VERSION ""

NS_ :

BS_:

BU_: PowertrainControlModule AtmosphericSensor SafetyRestraintSystem2 Aftertreatment_2_GasOutlet Aftertreatment_2_GasIntake DieselParticulateFilterControl Turbocharger SafetyRestraintSystem1 CabDisplay2 Aftertreatment_1_GasOutlet Aftertreatment_1_GasIntake OnBoardDataLogger OffBoardDiagnosticTool2 OffBoardDiagnosticTool1 FileServer ParkingBrakeController SeatController2 FanDriveController SteeringColumnUnit CommunicationUnitRadio CommunicationUnitSatellite CommunicationUnitCellular PropulsionBatteryCharger ChassisController2 ChassisController1 EngineValveControl AuxiliaryHeater2 AuxiliaryHeater1 ClutchUnit RampControl InformationSystem1 SuspensionSystemController2 OilSensor VehicleDynamicStability ExhaustEmissionController TransmissionDisplay2 TransmissionDisplay1 ClimateControl2 WaterPumpController RearAxleSteeringController LightingOperatorControl SeatController1 IgnitionController2 IgnitionController1 TirePressureController CabController2 CabController1 PneumaticSystemController SuspensionSystemController1 HydraulicPumpController EnduranceBrakingSystem RetarderExhaustEngine2 OnBoardDiagnosticUnit HeadwayController RetarderExhaustEngine1 CabDisplay1 ManagementComputer VirtualTerminal OffVehicleGateway PowerTakeOffFront HitchControl AuxiliaryValveControl BodyController TractorTrailerBridge1 StarterSystem ElectricalSystem VehicleSecurity VehicleNavigation AerodynamicControl ElectricalChargingSystem ClimateControl1 TripRecorder InstrumentCluster SuspensionDriveAxle2 SuspensionDriveAxle1 SuspensionSteerAxle SteeringController FuelSystem CruiseControl RetarderDriveline RetarderEngine BrakesDriveAxle2 BrakesDriveAxle1 BrakesSystemController BrakesSteerAxle AxleDrive2 AxleDrive1 AxleSteering PowerTakeOff ShiftConsoleSecondary ShiftConsolePrimary Transmission2 Transmission1 Engine2 Engine1

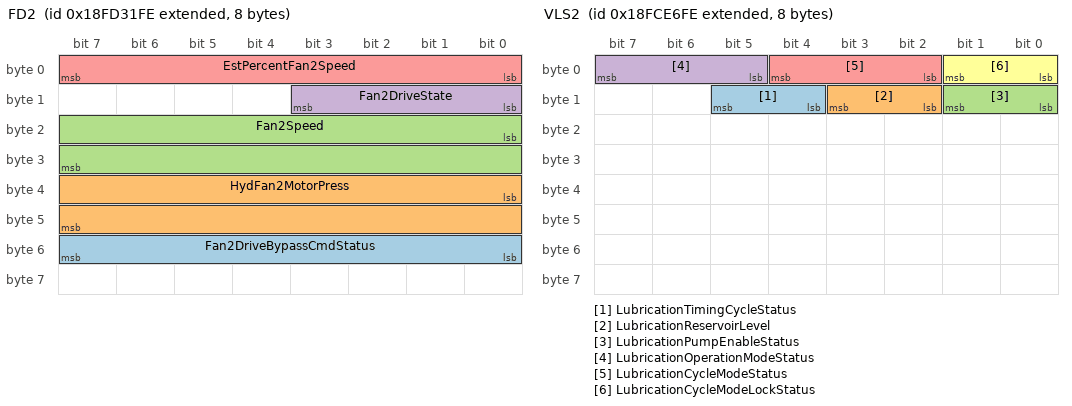
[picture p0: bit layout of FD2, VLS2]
BO_ 2566730238 FD2: 8 Vector__XXX
 SG_ Fan2DriveBypassCmdStatus : 48|8@1+ (0.4,0) [0|100] "%" Vector__XXX
 SG_ HydFan2MotorPress : 32|16@1+ (0.5,0) [0|32127.5] "kPa" Vector__XXX
 SG_ Fan2Speed : 16|16@1+ (0.125,0) [0|8031.875] "rpm" Vector__XXX
 SG_ Fan2DriveState : 8|4@1+ (1,0) [0|15] "" Vector__XXX
 SG_ EstPercentFan2Speed : 0|8@1+ (0.4,0) [0|100] "%" Vector__XXX

BO_ 2566711038 VLS2: 8 Vector__XXX
 SG_ LubricationTimingCycleStatus : 12|2@1+ (1,0) [0|3] "" Vector__XXX
 SG_ LubricationReservoirLevel : 10|2@1+ (1,0) [0|3] "" Vector__XXX
 SG_ LubricationPumpEnableStatus : 8|2@1+ (1,0) [0|3] "" Vector__XXX
 SG_ LubricationOperationModeStatus : 5|3@1+ (1,0) [0|7] "" Vector__XXX
 SG_ LubricationCycleModeStatus : 2|3@1+ (1,0) [0|7] "" Vector__XXX
 SG_ LubricationCycleModeLockStatus : 0|2@1+ (1,0) [0|3] "" Vector__XXX

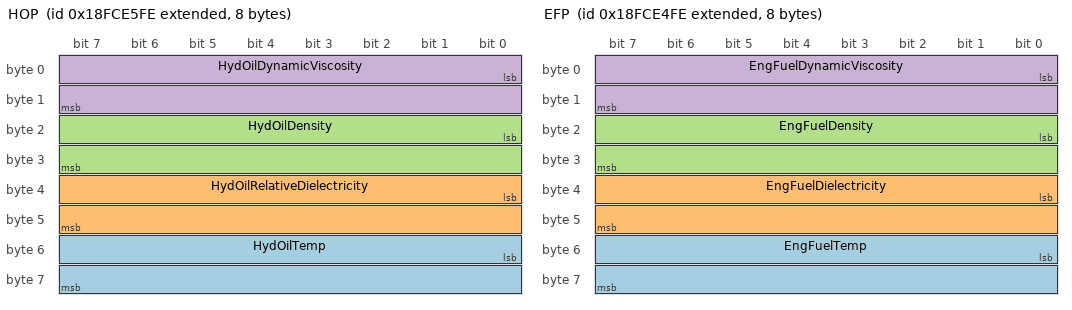
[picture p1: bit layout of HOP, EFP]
BO_ 2566710782 HOP: 8 Vector__XXX
 SG_ HydOilTemp : 48|16@1+ (0.03125,-273) [-273|1734.96875] "캜" Vector__XXX
 SG_ HydOilRelativeDielectricity : 32|16@1+ (0.0001220703125,0) [0|7.844] "" Vector__XXX
 SG_ HydOilDensity : 16|16@1+ (3.052E-005,0) [0|1.961] "g/cc" Vector__XXX
 SG_ HydOilDynamicViscosity : 0|16@1+ (0.015625,0) [0|1003.984375] "Cp" Vector__XXX

BO_ 2566710526 EFP: 8 Vector__XXX
 SG_ EngFuelTemp : 48|16@1+ (0.03125,-273) [-273|1734.96875] "캜" Vector__XXX
 SG_ EngFuelDielectricity : 32|16@1+ (0.0001220703125,0) [0|7.844] "" Vector__XXX
 SG_ EngFuelDensity : 16|16@1+ (3.052E-005,0) [0|1.961] "g/cc" Vector__XXX
 SG_ EngFuelDynamicViscosity : 0|16@1+ (0.015625,0) [0|1003.984375] "Cp" Vector__XXX

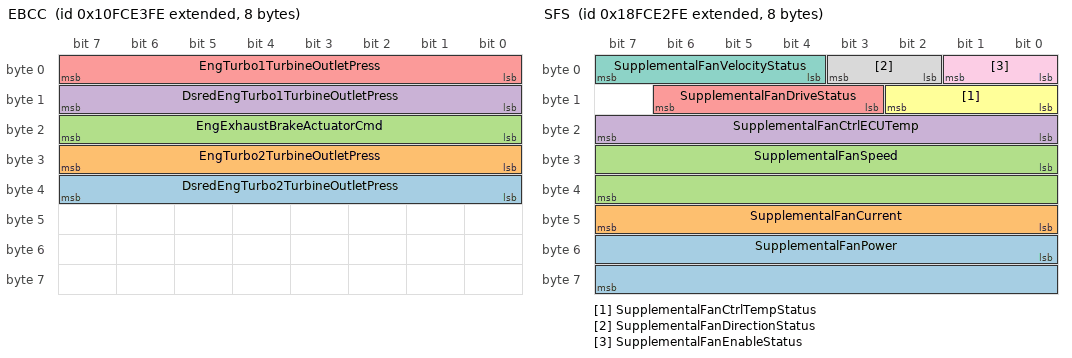
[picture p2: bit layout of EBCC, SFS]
BO_ 2432492542 EBCC: 8 Vector__XXX
 SG_ DsredEngTurbo2TurbineOutletPress : 32|8@1+ (2,0) [0|500] "kPa" Vector__XXX
 SG_ EngTurbo2TurbineOutletPress : 24|8@1+ (2,0) [0|500] "kPa" Vector__XXX
 SG_ EngExhaustBrakeActuatorCmd : 16|8@1+ (0.4,0) [0|100] "%" Vector__XXX
 SG_ DsredEngTurbo1TurbineOutletPress : 8|8@1+ (2,0) [0|500] "kPa" Vector__XXX
 SG_ EngTurbo1TurbineOutletPress : 0|8@1+ (2,0) [0|500] "kPa" Vector__XXX

BO_ 2566710014 SFS: 8 Vector__XXX
 SG_ SupplementalFanPower : 48|16@1+ (0.5,0) [0|32127.5] "W" Vector__XXX
 SG_ SupplementalFanCurrent : 40|8@1+ (1,-125) [-125|125] "A" Vector__XXX
 SG_ SupplementalFanSpeed : 24|16@1+ (0.5,0) [0|32127.5] "rpm" Vector__XXX
 SG_ SupplementalFanCtrlECUTemp : 16|8@1+ (1,-40) [-40|210] "캜" Vector__XXX
 SG_ SupplementalFanDriveStatus : 11|4@1+ (1,0) [0|15] "" Vector__XXX
 SG_ SupplementalFanCtrlTempStatus : 8|3@1+ (1,0) [0|7] "" Vector__XXX
 SG_ SupplementalFanVelocityStatus : 4|4@1+ (1,0) [0|15] "" Vector__XXX
 SG_ SupplementalFanDirectionStatus : 2|2@1+ (1,0) [0|3] "" Vector__XXX
 SG_ SupplementalFanEnableStatus : 0|2@1+ (1,0) [0|3] "" Vector__XXX

BO_ 2566709758 LFE2: 8 Vector__XXX
 SG_ EngDieselFuelDemandRate : 32|16@1+ (0.05,0) [0|3212.75] "l/h" Vector__XXX
 SG_ HighResolutionEngFuelRate : 0|32@1+ (0.001,0) [0|4211081.215] "l/h" Vector__XXX

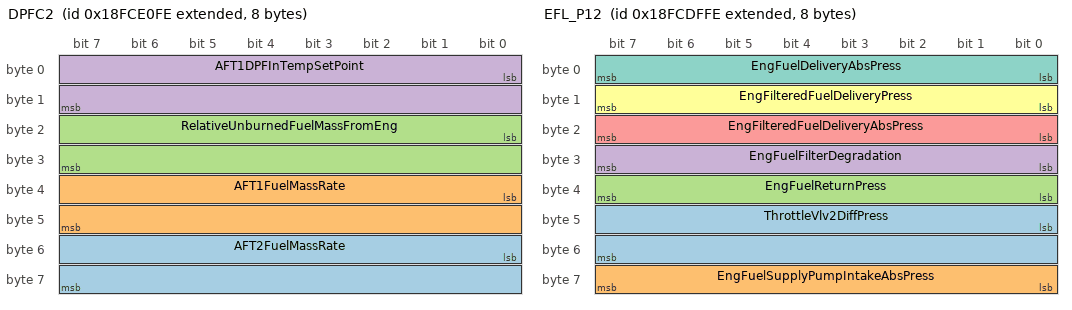
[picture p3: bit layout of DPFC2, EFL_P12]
BO_ 2566709502 DPFC2: 8 Vector__XXX
 SG_ AFT2FuelMassRate : 48|16@1+ (0.05,0) [0|3212.75] "g/min" Vector__XXX
 SG_ AFT1FuelMassRate : 32|16@1+ (0.05,0) [0|3212.75] "g/min" Vector__XXX
 SG_ RelativeUnburnedFuelMassFromEng : 16|16@1+ (0.0025,0) [0|160.6375] "%" Vector__XXX
 SG_ AFT1DPFInTempSetPoint : 0|16@1+ (0.03125,-273) [-273|1734.96875] "캜" Vector__XXX

BO_ 2566709246 EFL_P12: 8 Vector__XXX
 SG_ ThrottleVlv2DiffPress : 40|16@1+ (0.1,0) [0|6425.5] "kPa" Vector__XXX
 SG_ EngFuelSupplyPumpIntakeAbsPress : 56|8@1+ (5,0) [0|1250] "kPa" Vector__XXX
 SG_ EngFuelReturnPress : 32|8@1+ (1.64,-7) [-7|403] "kPa" Vector__XXX
 SG_ EngFuelFilterDegradation : 24|8@1+ (1,0) [0|250] "%" Vector__XXX
 SG_ EngFilteredFuelDeliveryAbsPress : 16|8@1+ (4,0) [0|1000] "kPa" Vector__XXX
 SG_ EngFilteredFuelDeliveryPress : 8|8@1+ (4,0) [0|1000] "kPa" Vector__XXX
 SG_ EngFuelDeliveryAbsPress : 0|8@1+ (4,0) [0|1000] "kPa" Vector__XXX

BO_ 2566708990 AT1AC3: 8 Vector__XXX
 SG_ SecondAirAbsPress : 0|16@1+ (0.1,0) [0|6425.5] "kPa" Vector__XXX

BO_ 2566708734 AT2AC3: 8 Vector__XXX
 SG_ SecondAirAbsPress : 0|16@1+ (0.1,0) [0|6425.5] "kPa" Vector__XXX

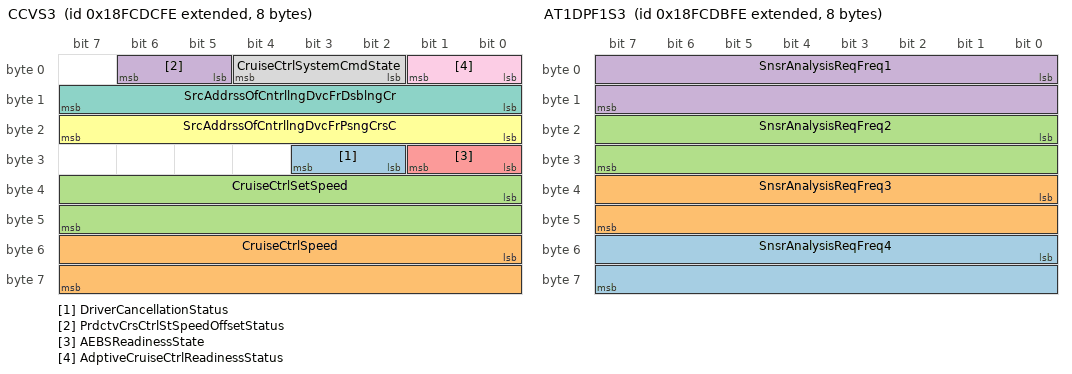
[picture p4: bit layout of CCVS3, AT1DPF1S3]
BO_ 2566708478 CCVS3: 8 Vector__XXX
 SG_ DriverCancellationStatus : 26|2@1+ (1,0) [0|3] "" Vector__XXX
 SG_ CruiseCtrlSpeed : 48|16@1+ (0.00390625,0) [0|250.996] "km/h" Vector__XXX
 SG_ CruiseCtrlSetSpeed : 32|16@1+ (0.00390625,0) [0|250.996] "km/h" Vector__XXX
 SG_ PrdctvCrsCtrlStSpeedOffsetStatus : 5|2@1+ (1,0) [0|3] "" Vector__XXX
 SG_ AEBSReadinessState : 24|2@1+ (1,0) [0|3] "" Vector__XXX
 SG_ SrcAddrssOfCntrllngDvcFrPsngCrsC : 16|8@1+ (1,0) [0|255] "" Vector__XXX
 SG_ SrcAddrssOfCntrllngDvcFrDsblngCr : 8|8@1+ (1,0) [0|255] "" Vector__XXX
 SG_ CruiseCtrlSystemCmdState : 2|3@1+ (1,0) [0|7] "" Vector__XXX
 SG_ AdptiveCruiseCtrlReadinessStatus : 0|2@1+ (1,0) [0|3] "" Vector__XXX

BO_ 2566708222 AT1DPF1S3: 8 Vector__XXX
 SG_ SnsrAnalysisReqFreq4 : 48|16@1+ (0.1,0) [0|6425.5] "MHz" Vector__XXX
 SG_ SnsrAnalysisReqFreq3 : 32|16@1+ (0.1,0) [0|6425.5] "MHz" Vector__XXX
 SG_ SnsrAnalysisReqFreq2 : 16|16@1+ (0.1,0) [0|6425.5] "MHz" Vector__XXX
 SG_ SnsrAnalysisReqFreq1 : 0|16@1+ (0.1,0) [0|6425.5] "MHz" Vector__XXX

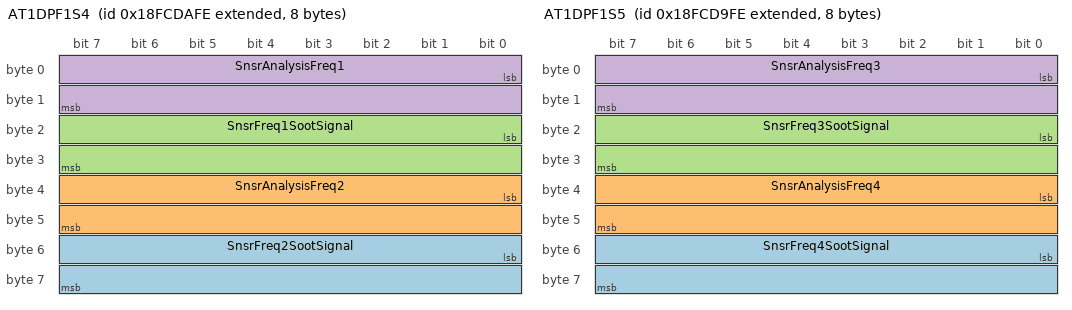
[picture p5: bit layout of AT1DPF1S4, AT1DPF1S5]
BO_ 2566707966 AT1DPF1S4: 8 Vector__XXX
 SG_ SnsrFreq2SootSignal : 48|16@1+ (0.0025,0) [0|160.6375] "%" Vector__XXX
 SG_ SnsrAnalysisFreq2 : 32|16@1+ (0.1,0) [0|6425.5] "MHz" Vector__XXX
 SG_ SnsrFreq1SootSignal : 16|16@1+ (0.0025,0) [0|160.6375] "%" Vector__XXX
 SG_ SnsrAnalysisFreq1 : 0|16@1+ (0.1,0) [0|6425.5] "MHz" Vector__XXX

BO_ 2566707710 AT1DPF1S5: 8 Vector__XXX
 SG_ SnsrFreq4SootSignal : 48|16@1+ (0.0025,0) [0|160.6375] "%" Vector__XXX
 SG_ SnsrAnalysisFreq4 : 32|16@1+ (0.1,0) [0|6425.5] "MHz" Vector__XXX
 SG_ SnsrFreq3SootSignal : 16|16@1+ (0.0025,0) [0|160.6375] "%" Vector__XXX
 SG_ SnsrAnalysisFreq3 : 0|16@1+ (0.1,0) [0|6425.5] "MHz" Vector__XXX

BO_ 2561343230 CFS: 8 Vector__XXX

BO_ 2566749694 FMS1: 8 Vector__XXX

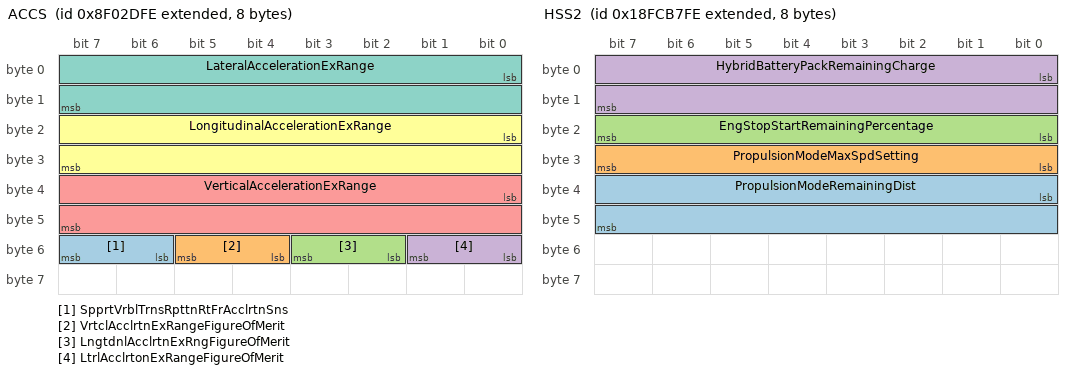
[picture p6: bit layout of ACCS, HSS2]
BO_ 2297441790 ACCS: 8 Vector__XXX
 SG_ SpprtVrblTrnsRpttnRtFrAcclrtnSns : 54|2@1+ (1,0) [0|3] "" Vector__XXX
 SG_ VrtclAcclrtnExRangeFigureOfMerit : 52|2@1+ (1,0) [0|3] "" Vector__XXX
 SG_ LngtdnlAcclrtnExRngFigureOfMerit : 50|2@1+ (1,0) [0|3] "" Vector__XXX
 SG_ LtrlAcclrtonExRangeFigureOfMerit : 48|2@1+ (1,0) [0|3] "" Vector__XXX
 SG_ VerticalAccelerationExRange : 32|16@1+ (0.01,-320) [-320|322.55] "m/s�" Vector__XXX
 SG_ LongitudinalAccelerationExRange : 16|16@1+ (0.01,-320) [-320|322.55] "m/s�" Vector__XXX
 SG_ LateralAccelerationExRange : 0|16@1+ (0.01,-320) [-320|322.55] "m/s�" Vector__XXX

BO_ 2566699006 HSS2: 8 Vector__XXX
 SG_ PropulsionModeRemainingDist : 32|16@1+ (0.03125,0) [0|2007.96875] "km" Vector__XXX
 SG_ PropulsionModeMaxSpdSetting : 24|8@1+ (1,0) [0|250] "km/h" Vector__XXX
 SG_ EngStopStartRemainingPercentage : 16|8@1+ (0.4,0) [0|100] "%" Vector__XXX
 SG_ HybridBatteryPackRemainingCharge : 0|16@1+ (0.0025,0) [0|160.6375] "%" Vector__XXX

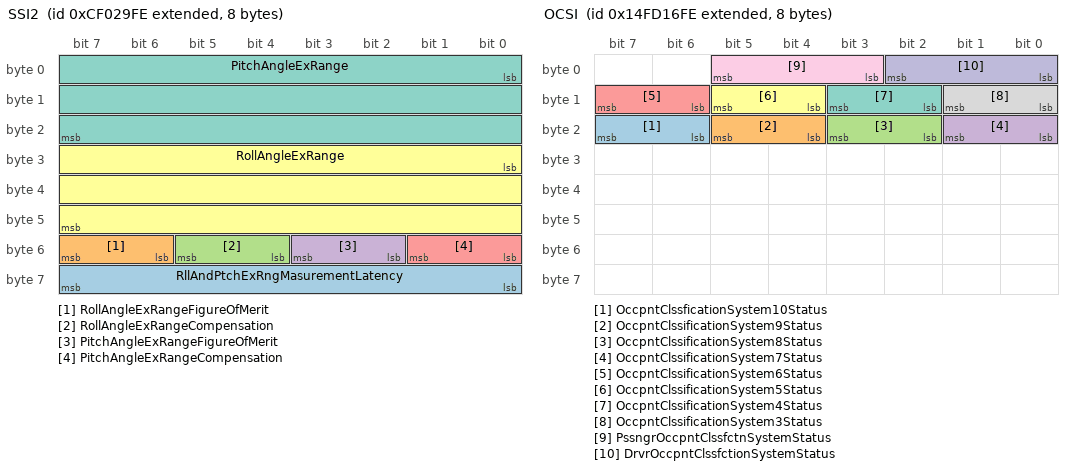
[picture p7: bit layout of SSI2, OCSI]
BO_ 2364549630 SSI2: 8 Vector__XXX
 SG_ RllAndPtchExRngMasurementLatency : 56|8@1+ (0.5,0) [0|125] "ms" Vector__XXX
 SG_ RollAngleExRangeFigureOfMerit : 54|2@1+ (1,0) [0|3] "" Vector__XXX
 SG_ RollAngleExRangeCompensation : 52|2@1+ (1,0) [0|3] "" Vector__XXX
 SG_ PitchAngleExRangeFigureOfMerit : 50|2@1+ (1,0) [0|3] "" Vector__XXX
 SG_ PitchAngleExRangeCompensation : 48|2@1+ (1,0) [0|3] "" Vector__XXX
 SG_ RollAngleExRange : 24|24@1+ (3.0517578125E-005,-250) [-250|252] "deg" Vector__XXX
 SG_ PitchAngleExRange : 0|24@1+ (3.0517578125E-005,-250) [-250|252] "deg" Vector__XXX

BO_ 2499614462 OCSI: 8 Vector__XXX
 SG_ OccpntClssficationSystem10Status : 22|2@1+ (1,0) [0|3] "" Vector__XXX
 SG_ OccpntClssificationSystem9Status : 20|2@1+ (1,0) [0|3] "" Vector__XXX
 SG_ OccpntClssificationSystem8Status : 18|2@1+ (1,0) [0|3] "" Vector__XXX
 SG_ OccpntClssificationSystem7Status : 16|2@1+ (1,0) [0|3] "" Vector__XXX
 SG_ OccpntClssificationSystem6Status : 14|2@1+ (1,0) [0|3] "" Vector__XXX
 SG_ OccpntClssificationSystem5Status : 12|2@1+ (1,0) [0|3] "" Vector__XXX
 SG_ OccpntClssificationSystem4Status : 10|2@1+ (1,0) [0|3] "" Vector__XXX
 SG_ OccpntClssificationSystem3Status : 8|2@1+ (1,0) [0|3] "" Vector__XXX
 SG_ PssngrOccpntClssfctnSystemStatus : 3|3@1+ (1,0) [0|7] "" Vector__XXX
 SG_ DrvrOccpntClssfctionSystemStatus : 0|3@1+ (1,0) [0|7] "" Vector__XXX

BO_ 2560098046 NCS: 8 Vector__XXX
 SG_ CabNoiseCtrlTuningStatus : 2|4@1+ (1,0) [0|15] "" Vector__XXX
 SG_ CabNoiseCtrlStatus : 0|2@1+ (1,0) [0|3] "" Vector__XXX

BO_ 2560163582 NC1: 8 Vector__XXX
 SG_ CabNoiseCtrlTuningCmd : 2|3@1+ (1,0) [0|7] "" Vector__XXX
 SG_ CabNoiseCtrlCmd : 0|2@1+ (1,0) [0|3] "" Vector__XXX

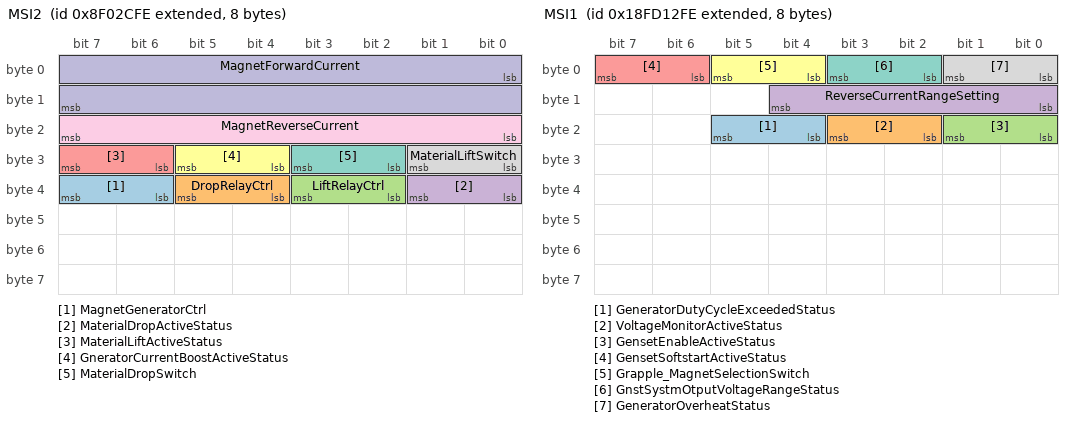
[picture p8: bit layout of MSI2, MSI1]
BO_ 2297441534 MSI2: 8 Vector__XXX
 SG_ MagnetGeneratorCtrl : 38|2@1+ (1,0) [0|3] "" Vector__XXX
 SG_ DropRelayCtrl : 36|2@1+ (1,0) [0|3] "" Vector__XXX
 SG_ LiftRelayCtrl : 34|2@1+ (1,0) [0|3] "" Vector__XXX
 SG_ MaterialDropActiveStatus : 32|2@1+ (1,0) [0|3] "" Vector__XXX
 SG_ MaterialLiftActiveStatus : 30|2@1+ (1,0) [0|3] "" Vector__XXX
 SG_ GneratorCurrentBoostActiveStatus : 28|2@1+ (1,0) [0|3] "" Vector__XXX
 SG_ MaterialDropSwitch : 26|2@1+ (1,0) [0|3] "" Vector__XXX
 SG_ MaterialLiftSwitch : 24|2@1+ (1,0) [0|3] "" Vector__XXX
 SG_ MagnetReverseCurrent : 16|8@1+ (1,0) [0|250] "A" Vector__XXX
 SG_ MagnetForwardCurrent : 0|16@1+ (1,0) [0|64255] "A" Vector__XXX

BO_ 2566722302 MSI1: 8 Vector__XXX
 SG_ GeneratorDutyCycleExceededStatus : 20|2@1+ (1,0) [0|3] "" Vector__XXX
 SG_ VoltageMonitorActiveStatus : 18|2@1+ (1,0) [0|3] "" Vector__XXX
 SG_ GensetEnableActiveStatus : 16|2@1+ (1,0) [0|3] "" Vector__XXX
 SG_ ReverseCurrentRangeSetting : 8|5@1+ (1,0) [0|31] "" Vector__XXX
 SG_ GensetSoftstartActiveStatus : 6|2@1+ (1,0) [0|3] "" Vector__XXX
 SG_ Grapple_MagnetSelectionSwitch : 4|2@1+ (1,0) [0|3] "" Vector__XXX
 SG_ GnstSystmOtputVoltageRangeStatus : 2|2@1+ (1,0) [0|3] "" Vector__XXX
 SG_ GeneratorOverheatStatus : 0|2@1+ (1,0) [0|3] "" Vector__XXX

BO_ 2566722558 MSCI: 8 Vector__XXX
 SG_ MagnetRatedPower : 8|16@1+ (0.5,0) [0|32127.5] "kW" Vector__XXX
 SG_ MagnetBoostTime : 0|8@1+ (0.25,0) [0|62.5] "s" Vector__XXX

BO_ 2560032510 LVDSOM: 8 Vector__XXX
 SG_ LwVltgDscnnctDsiredOperatingMode : 0|4@1+ (1,0) [0|15] "" Vector__XXX

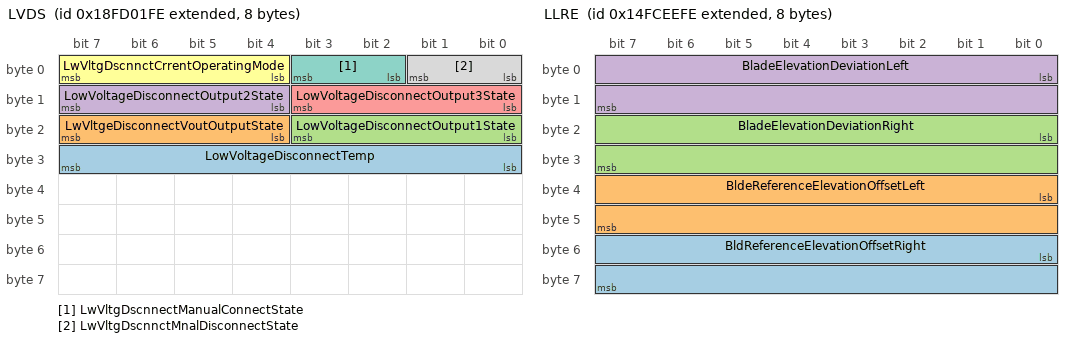
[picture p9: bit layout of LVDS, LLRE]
BO_ 2566717950 LVDS: 8 Vector__XXX
 SG_ LowVoltageDisconnectTemp : 24|8@1+ (1,-40) [-40|210] "캜" Vector__XXX
 SG_ LwVltgeDisconnectVoutOutputState : 20|4@1+ (1,0) [0|15] "" Vector__XXX
 SG_ LowVoltageDisconnectOutput1State : 16|4@1+ (1,0) [0|15] "" Vector__XXX
 SG_ LowVoltageDisconnectOutput2State : 12|4@1+ (1,0) [0|15] "" Vector__XXX
 SG_ LowVoltageDisconnectOutput3State : 8|4@1+ (1,0) [0|15] "" Vector__XXX
 SG_ LwVltgDscnnctCrrentOperatingMode : 4|4@1+ (1,0) [0|15] "" Vector__XXX
 SG_ LwVltgDscnnectManualConnectState : 2|2@1+ (1,0) [0|3] "" Vector__XXX
 SG_ LwVltgDscnnctMnalDisconnectState : 0|2@1+ (1,0) [0|3] "" Vector__XXX

BO_ 2499604222 LLRE: 8 Vector__XXX
 SG_ BldReferenceElevationOffsetRight : 48|16@1+ (1,-32000) [-32000|32255] "mm" Vector__XXX
 SG_ BldeReferenceElevationOffsetLeft : 32|16@1+ (1,-32000) [-32000|32255] "mm" Vector__XXX
 SG_ BladeElevationDeviationRight : 16|16@1+ (1,-32000) [-32000|32255] "mm" Vector__XXX
 SG_ BladeElevationDeviationLeft : 0|16@1+ (1,-32000) [-32000|32255] "mm" Vector__XXX

BO_ 2358902526 JLCM: 8 Vector__XXX
 SG_ Joystick3Lamp10Cmd : 58|2@1+ (1,0) [0|3] "" Vector__XXX
 SG_ Joystick3Lamp9Cmd : 56|2@1+ (1,0) [0|3] "" Vector__XXX
 SG_ Joystick3Lamp8Cmd : 54|2@1+ (1,0) [0|3] "" Vector__XXX
 SG_ Joystick3Lamp7Cmd : 52|2@1+ (1,0) [0|3] "" Vector__XXX
 SG_ Joystick3Lamp6Cmd : 50|2@1+ (1,0) [0|3] "" Vector__XXX
 SG_ Joystick3Lamp5Cmd : 48|2@1+ (1,0) [0|3] "" Vector__XXX
 SG_ Joystick3Lamp4Cmd : 46|2@1+ (1,0) [0|3] "" Vector__XXX
 SG_ Joystick3Lamp3Cmd : 44|2@1+ (1,0) [0|3] "" Vector__XXX
 SG_ Joystick3Lamp2Cmd : 42|2@1+ (1,0) [0|3] "" Vector__XXX
 SG_ Joystick3Lamp1Cmd : 40|2@1+ (1,0) [0|3] "" Vector__XXX
 SG_ Joystick2Lamp10Cmd : 38|2@1+ (1,0) [0|3] "" Vector__XXX
 SG_ Joystick2Lamp9Cmd : 36|2@1+ (1,0) [0|3] "" Vector__XXX
 SG_ Joystick2Lamp8Cmd : 34|2@1+ (1,0) [0|3] "" Vector__XXX
 SG_ Joystick2Lamp7Cmd : 32|2@1+ (1,0) [0|3] "" Vector__XXX
 SG_ Joystick2Lamp6Cmd : 30|2@1+ (1,0) [0|3] "" Vector__XXX
 SG_ Joystick2Lamp5Cmd : 28|2@1+ (1,0) [0|3] "" Vector__XXX
 SG_ Joystick2Lamp4Cmd : 26|2@1+ (1,0) [0|3] "" Vector__XXX
 SG_ Joystick2Lamp3Cmd : 24|2@1+ (1,0) [0|3] "" Vector__XXX
 SG_ Joystick2Lamp2Cmd : 22|2@1+ (1,0) [0|3] "" Vector__XXX
 SG_ Joystick2Lamp1Cmd : 20|2@1+ (1,0) [0|3] "" Vector__XXX
 SG_ Joystick1Lamp10Cmd : 18|2@1+ (1,0) [0|3] "" Vector__XXX
 SG_ Joystick1Lamp9Cmd : 16|2@1+ (1,0) [0|3] "" Vector__XXX
 SG_ Joystick1Lamp8Cmd : 14|2@1+ (1,0) [0|3] "" Vector__XXX
 SG_ Joystick1Lamp7Cmd : 12|2@1+ (1,0) [0|3] "" Vector__XXX
 SG_ Joystick1Lamp6Cmd : 10|2@1+ (1,0) [0|3] "" Vector__XXX
 SG_ Joystick1Lamp5Cmd : 8|2@1+ (1,0) [0|3] "" Vector__XXX
 SG_ Joystick1Lamp4Cmd : 6|2@1+ (1,0) [0|3] "" Vector__XXX
 SG_ Joystick1Lamp3Cmd : 4|2@1+ (1,0) [0|3] "" Vector__XXX
 SG_ Joystick1Lamp2Cmd : 2|2@1+ (1,0) [0|3] "" Vector__XXX
 SG_ Joystick1Lamp1Cmd : 0|2@1+ (1,0) [0|3] "" Vector__XXX

BO_ 2566711550 IVAC: 8 Vector__XXX
 SG_ IntkVlvActtnSystmOlPrss2SlndCtrl : 2|2@1+ (1,0) [0|3] "" Vector__XXX
 SG_ IntkVlvActtnSystmOlPrss1SlndCtrl : 0|2@1+ (1,0) [0|3] "" Vector__XXX

BO_ 2633832958 ILI: 8 Vector__XXX
 SG_ SpecialIgnitorLoop90Resistance : 1584|16@1+ (0.1,0) [0|6425.5] "ohm" Vector__XXX
 SG_ SpecialIgnitorLoop89Resistance : 1568|16@1+ (0.1,0) [0|6425.5] "ohm" Vector__XXX
 SG_ SpecialIgnitorLoop88Resistance : 1552|16@1+ (0.1,0) [0|6425.5] "ohm" Vector__XXX
 SG_ SpecialIgnitorLoop87Resistance : 1536|16@1+ (0.1,0) [0|6425.5] "ohm" Vector__XXX
 SG_ SpecialIgnitorLoop86Resistance : 1520|16@1+ (0.1,0) [0|6425.5] "ohm" Vector__XXX
 SG_ SpecialIgnitorLoop85Resistance : 1504|16@1+ (0.1,0) [0|6425.5] "ohm" Vector__XXX
 SG_ SpecialIgnitorLoop84Resistance : 1488|16@1+ (0.1,0) [0|6425.5] "ohm" Vector__XXX
 SG_ SpecialIgnitorLoop83Resistance : 1472|16@1+ (0.1,0) [0|6425.5] "ohm" Vector__XXX
 SG_ SpecialIgnitorLoop82Resistance : 1456|16@1+ (0.1,0) [0|6425.5] "ohm" Vector__XXX
 SG_ SpecialIgnitorLoop81Resistance : 1440|16@1+ (0.1,0) [0|6425.5] "ohm" Vector__XXX
 SG_ SpecialIgnitorLoop80Resistance : 1424|16@1+ (0.1,0) [0|6425.5] "ohm" Vector__XXX
 SG_ SpecialIgnitorLoop79Resistance : 1408|16@1+ (0.1,0) [0|6425.5] "ohm" Vector__XXX
 SG_ SpecialIgnitorLoop78Resistance : 1392|16@1+ (0.1,0) [0|6425.5] "ohm" Vector__XXX
 SG_ SpecialIgnitorLoop77Resistance : 1376|16@1+ (0.1,0) [0|6425.5] "ohm" Vector__XXX
 SG_ SpecialIgnitorLoop76Resistance : 1360|16@1+ (0.1,0) [0|6425.5] "ohm" Vector__XXX
 SG_ SpecialIgnitorLoop75Resistance : 1344|16@1+ (0.1,0) [0|6425.5] "ohm" Vector__XXX
 SG_ SpecialIgnitorLoop74Resistance : 1328|16@1+ (0.1,0) [0|6425.5] "ohm" Vector__XXX
 SG_ SpecialIgnitorLoop73Resistance : 1312|16@1+ (0.1,0) [0|6425.5] "ohm" Vector__XXX
 SG_ SpecialIgnitorLoop72Resistance : 1296|16@1+ (0.1,0) [0|6425.5] "ohm" Vector__XXX
 SG_ SpecialIgnitorLoop71Resistance : 1280|16@1+ (0.1,0) [0|6425.5] "ohm" Vector__XXX
 SG_ SpecialIgnitorLoop70Resistance : 1264|16@1+ (0.1,0) [0|6425.5] "ohm" Vector__XXX
 SG_ SpecialIgnitorLoop69Resistance : 1248|16@1+ (0.1,0) [0|6425.5] "ohm" Vector__XXX
 SG_ SpecialIgnitorLoop68Resistance : 1232|16@1+ (0.1,0) [0|6425.5] "ohm" Vector__XXX
 SG_ SpecialIgnitorLoop67Resistance : 1216|16@1+ (0.1,0) [0|6425.5] "ohm" Vector__XXX
 SG_ SpecialIgnitorLoop66Resistance : 1200|16@1+ (0.1,0) [0|6425.5] "ohm" Vector__XXX
 SG_ SpecialIgnitorLoop65Resistance : 1184|16@1+ (0.1,0) [0|6425.5] "ohm" Vector__XXX
 SG_ SpecialIgnitorLoop64Resistance : 1168|16@1+ (0.1,0) [0|6425.5] "ohm" Vector__XXX
 SG_ SpecialIgnitorLoop63Resistance : 1152|16@1+ (0.1,0) [0|6425.5] "ohm" Vector__XXX
 SG_ SpecialIgnitorLoop62Resistance : 1136|16@1+ (0.1,0) [0|6425.5] "ohm" Vector__XXX
 SG_ SpecialIgnitorLoop61Resistance : 1120|16@1+ (0.1,0) [0|6425.5] "ohm" Vector__XXX
 SG_ SpecialIgnitorLoop60Resistance : 1104|16@1+ (0.1,0) [0|6425.5] "ohm" Vector__XXX
 SG_ SpecialIgnitorLoop59Resistance : 1088|16@1+ (0.1,0) [0|6425.5] "ohm" Vector__XXX
 SG_ SpecialIgnitorLoop58Resistance : 1072|16@1+ (0.1,0) [0|6425.5] "ohm" Vector__XXX
 SG_ SpecialIgnitorLoop57Resistance : 1056|16@1+ (0.1,0) [0|6425.5] "ohm" Vector__XXX
 SG_ SpecialIgnitorLoop56Resistance : 1040|16@1+ (0.1,0) [0|6425.5] "ohm" Vector__XXX
 SG_ SpecialIgnitorLoop55Resistance : 1024|16@1+ (0.1,0) [0|6425.5] "ohm" Vector__XXX
 SG_ SpecialIgnitorLoop54Resistance : 1008|16@1+ (0.1,0) [0|6425.5] "ohm" Vector__XXX
 SG_ SpecialIgnitorLoop53Resistance : 992|16@1+ (0.1,0) [0|6425.5] "ohm" Vector__XXX
 SG_ SpecialIgnitorLoop52Resistance : 976|16@1+ (0.1,0) [0|6425.5] "ohm" Vector__XXX
 SG_ SpecialIgnitorLoop51Resistance : 960|16@1+ (0.1,0) [0|6425.5] "ohm" Vector__XXX
 SG_ SpecialIgnitorLoop50Resistance : 944|16@1+ (0.1,0) [0|6425.5] "ohm" Vector__XXX
 SG_ SpecialIgnitorLoop49Resistance : 928|16@1+ (0.1,0) [0|6425.5] "ohm" Vector__XXX
 SG_ SpecialIgnitorLoop48Resistance : 912|16@1+ (0.1,0) [0|6425.5] "ohm" Vector__XXX
 SG_ SpecialIgnitorLoop47Resistance : 896|16@1+ (0.1,0) [0|6425.5] "ohm" Vector__XXX
 SG_ SpecialIgnitorLoop46Resistance : 880|16@1+ (0.1,0) [0|6425.5] "ohm" Vector__XXX
 SG_ SpecialIgnitorLoop45Resistance : 864|16@1+ (0.1,0) [0|6425.5] "ohm" Vector__XXX
 SG_ SpecialIgnitorLoop44Resistance : 848|16@1+ (0.1,0) [0|6425.5] "ohm" Vector__XXX
 SG_ SpecialIgnitorLoop43Resistance : 832|16@1+ (0.1,0) [0|6425.5] "ohm" Vector__XXX
 SG_ SpecialIgnitorLoop42Resistance : 816|16@1+ (0.1,0) [0|6425.5] "ohm" Vector__XXX
 SG_ SpecialIgnitorLoop41Resistance : 800|16@1+ (0.1,0) [0|6425.5] "ohm" Vector__XXX
 SG_ SpecialIgnitorLoop40Resistance : 784|16@1+ (0.1,0) [0|6425.5] "ohm" Vector__XXX
 SG_ SpecialIgnitorLoop39Resistance : 768|16@1+ (0.1,0) [0|6425.5] "ohm" Vector__XXX
 SG_ SpecialIgnitorLoop38Resistance : 752|16@1+ (0.1,0) [0|6425.5] "ohm" Vector__XXX
 SG_ SpecialIgnitorLoop37Resistance : 736|16@1+ (0.1,0) [0|6425.5] "ohm" Vector__XXX
 SG_ SpecialIgnitorLoop36Resistance : 720|16@1+ (0.1,0) [0|6425.5] "ohm" Vector__XXX
 SG_ SpecialIgnitorLoop35Resistance : 704|16@1+ (0.1,0) [0|6425.5] "ohm" Vector__XXX
 SG_ SpecialIgnitorLoop34Resistance : 688|16@1+ (0.1,0) [0|6425.5] "ohm" Vector__XXX
 SG_ SpecialIgnitorLoop33Resistance : 672|16@1+ (0.1,0) [0|6425.5] "ohm" Vector__XXX
 SG_ SpecialIgnitorLoop32Resistance : 656|16@1+ (0.1,0) [0|6425.5] "ohm" Vector__XXX
 SG_ SpecialIgnitorLoop31Resistance : 640|16@1+ (0.1,0) [0|6425.5] "ohm" Vector__XXX
 SG_ SpecialIgnitorLoop30Resistance : 624|16@1+ (0.1,0) [0|6425.5] "ohm" Vector__XXX
 SG_ SpecialIgnitorLoop29Resistance : 608|16@1+ (0.1,0) [0|6425.5] "ohm" Vector__XXX
 SG_ SpecialIgnitorLoop28Resistance : 592|16@1+ (0.1,0) [0|6425.5] "ohm" Vector__XXX
 SG_ SpecialIgnitorLoop27Resistance : 576|16@1+ (0.1,0) [0|6425.5] "ohm" Vector__XXX
 SG_ SpecialIgnitorLoop26Resistance : 560|16@1+ (0.1,0) [0|6425.5] "ohm" Vector__XXX
 SG_ SpecialIgnitorLoop25Resistance : 544|16@1+ (0.1,0) [0|6425.5] "ohm" Vector__XXX
 SG_ SpecialIgnitorLoop24Resistance : 528|16@1+ (0.1,0) [0|6425.5] "ohm" Vector__XXX
 SG_ SpecialIgnitorLoop23Resistance : 512|16@1+ (0.1,0) [0|6425.5] "ohm" Vector__XXX
 SG_ SpecialIgnitorLoop22Resistance : 496|16@1+ (0.1,0) [0|6425.5] "ohm" Vector__XXX
 SG_ SpecialIgnitorLoop21Resistance : 480|16@1+ (0.1,0) [0|6425.5] "ohm" Vector__XXX
 SG_ SpecialIgnitorLoop20Resistance : 464|16@1+ (0.1,0) [0|6425.5] "ohm" Vector__XXX
 SG_ SpecialIgnitorLoop19Resistance : 448|16@1+ (0.1,0) [0|6425.5] "ohm" Vector__XXX
 SG_ SpecialIgnitorLoop18Resistance : 432|16@1+ (0.1,0) [0|6425.5] "ohm" Vector__XXX
 SG_ SpecialIgnitorLoop17Resistance : 416|16@1+ (0.1,0) [0|6425.5] "ohm" Vector__XXX
 SG_ SpecialIgnitorLoop16Resistance : 400|16@1+ (0.1,0) [0|6425.5] "ohm" Vector__XXX
 SG_ SpecialIgnitorLoop15Resistance : 384|16@1+ (0.1,0) [0|6425.5] "ohm" Vector__XXX
 SG_ SpecialIgnitorLoop14Resistance : 368|16@1+ (0.1,0) [0|6425.5] "ohm" Vector__XXX
 SG_ SpecialIgnitorLoop13Resistance : 352|16@1+ (0.1,0) [0|6425.5] "ohm" Vector__XXX
 SG_ SpecialIgnitorLoop12Resistance : 336|16@1+ (0.1,0) [0|6425.5] "ohm" Vector__XXX
 SG_ SpecialIgnitorLoop11Resistance : 320|16@1+ (0.1,0) [0|6425.5] "ohm" Vector__XXX
 SG_ SpecialIgnitorLoop10Resistance : 304|16@1+ (0.1,0) [0|6425.5] "ohm" Vector__XXX
 SG_ SpecialIgnitorLoop9Resistance : 288|16@1+ (0.1,0) [0|6425.5] "ohm" Vector__XXX
 SG_ SpecialIgnitorLoop8Resistance : 272|16@1+ (0.1,0) [0|6425.5] "ohm" Vector__XXX
 SG_ SpecialIgnitorLoop7Resistance : 256|16@1+ (0.1,0) [0|6425.5] "ohm" Vector__XXX
 SG_ SpecialIgnitorLoop6Resistance : 240|16@1+ (0.1,0) [0|6425.5] "ohm" Vector__XXX
 SG_ SpecialIgnitorLoop5Resistance : 224|16@1+ (0.1,0) [0|6425.5] "ohm" Vector__XXX
 SG_ SpecialIgnitorLoop4Resistance : 208|16@1+ (0.1,0) [0|6425.5] "ohm" Vector__XXX
 SG_ SpecialIgnitorLoop3Resistance : 192|16@1+ (0.1,0) [0|6425.5] "ohm" Vector__XXX
 SG_ SpecialIgnitorLoop2Resistance : 176|16@1+ (0.1,0) [0|6425.5] "ohm" Vector__XXX
 SG_ SpecialIgnitorLoop1Resistance : 160|16@1+ (0.1,0) [0|6425.5] "ohm" Vector__XXX
 SG_ SdBagIgnitorLoop2RightResistance : 144|16@1+ (0.1,0) [0|6425.5] "ohm" Vector__XXX
 SG_ SdBagIgnitorLoop1RightResistance : 128|16@1+ (0.1,0) [0|6425.5] "ohm" Vector__XXX
 SG_ SdeBagIgnitorLoop2LeftResistance : 112|16@1+ (0.1,0) [0|6425.5] "ohm" Vector__XXX
 SG_ SdeBagIgnitorLoop1LeftResistance : 96|16@1+ (0.1,0) [0|6425.5] "ohm" Vector__XXX
 SG_ PssngrBltTnsnrIgntrLopResistance : 80|16@1+ (0.1,0) [0|6425.5] "ohm" Vector__XXX
 SG_ DrvrBltTnsnrIgntorLoopResistance : 64|16@1+ (0.1,0) [0|6425.5] "ohm" Vector__XXX
 SG_ PssngrArbgIgntrLp2ndStgRsistance : 48|16@1+ (0.1,0) [0|6425.5] "ohm" Vector__XXX
 SG_ DrvrArbgIgntrLp2ndStgeResistance : 32|16@1+ (0.1,0) [0|6425.5] "ohm" Vector__XXX
 SG_ PssngrArbgIgntrLp1stStgRsistance : 16|16@1+ (0.1,0) [0|6425.5] "ohm" Vector__XXX
 SG_ DrvrArbgIgntrLp1stStgeResistance : 0|16@1+ (0.1,0) [0|6425.5] "ohm" Vector__XXX

BO_ 2566719998 HRLFC: 8 Vector__XXX
 SG_ HighResolutionEngTotalFuelUsed : 32|32@1+ (0.001,0) [0|4211081.215] "l" Vector__XXX
 SG_ HighResolutionEngTripFuel : 0|32@1+ (0.001,0) [0|4211081.215] "l" Vector__XXX

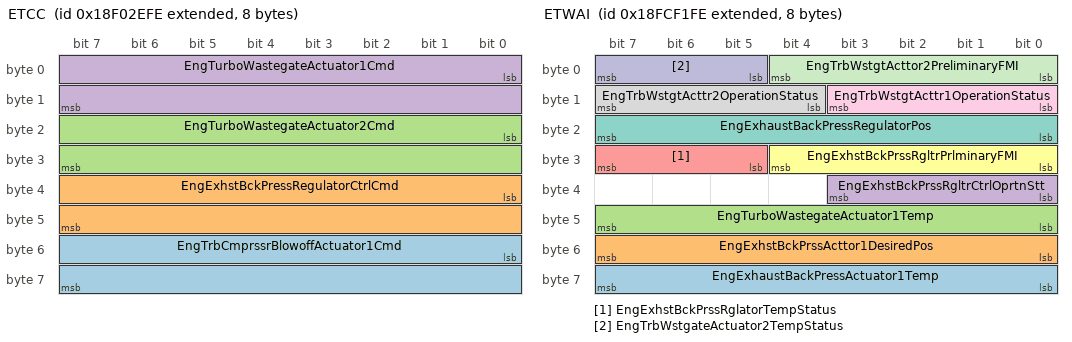
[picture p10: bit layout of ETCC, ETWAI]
BO_ 2565877502 ETCC: 8 Vector__XXX
 SG_ EngTrbCmprssrBlowoffActuator1Cmd : 48|16@1+ (0.0025,0) [0|100] "%" Vector__XXX
 SG_ EngExhstBckPressRegulatorCtrlCmd : 32|16@1+ (0.0025,0) [0|100] "%" Vector__XXX
 SG_ EngTurboWastegateActuator2Cmd : 16|16@1+ (0.0025,0) [0|160.6375] "%" Vector__XXX
 SG_ EngTurboWastegateActuator1Cmd : 0|16@1+ (0.0025,0) [0|160.6375] "%" Vector__XXX

BO_ 2566713854 ETWAI: 8 Vector__XXX
 SG_ EngExhaustBackPressActuator1Temp : 56|8@1+ (1,-40) [-40|210] "캜" Vector__XXX
 SG_ EngExhstBckPrssActtor1DesiredPos : 48|8@1+ (0.4,0) [0|100] "%" Vector__XXX
 SG_ EngTurboWastegateActuator1Temp : 40|8@1+ (1,-40) [-40|210] "캜" Vector__XXX
 SG_ EngExhstBckPrssRgltrCtrlOprtnStt : 32|4@1+ (1,0) [0|15] "" Vector__XXX
 SG_ EngExhstBckPrssRglatorTempStatus : 29|3@1+ (1,0) [0|7] "" Vector__XXX
 SG_ EngExhstBckPrssRgltrPrlminaryFMI : 24|5@1+ (1,0) [0|31] "" Vector__XXX
 SG_ EngExhaustBackPressRegulatorPos : 16|8@1+ (0.4,0) [0|100] "%" Vector__XXX
 SG_ EngTrbWstgtActtr2OperationStatus : 12|4@1+ (1,0) [0|15] "" Vector__XXX
 SG_ EngTrbWstgtActtr1OperationStatus : 8|4@1+ (1,0) [0|15] "" Vector__XXX
 SG_ EngTrbWstgateActuator2TempStatus : 5|3@1+ (1,0) [0|7] "" Vector__XXX
 SG_ EngTrbWstgtActtor2PreliminaryFMI : 0|5@1+ (1,0) [0|31] "" Vector__XXX

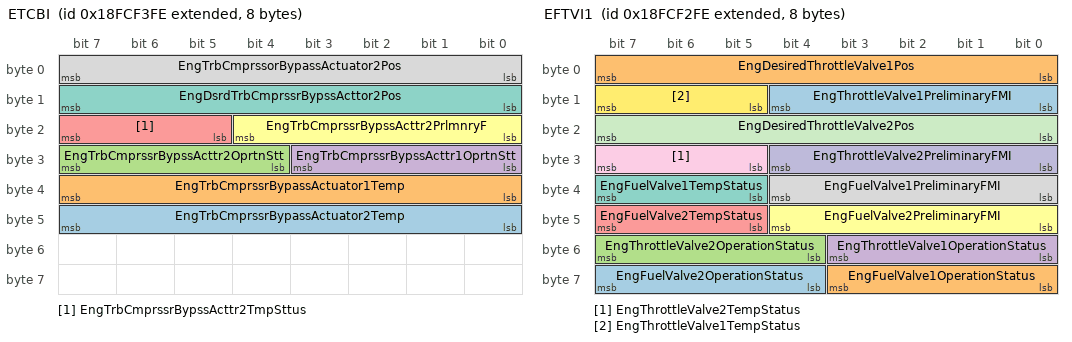
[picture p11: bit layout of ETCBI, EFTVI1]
BO_ 2566714366 ETCBI: 8 Vector__XXX
 SG_ EngTrbCmprssrBypassActuator2Temp : 40|8@1+ (1,-40) [-40|210] "캜" Vector__XXX
 SG_ EngTrbCmprssrBypassActuator1Temp : 32|8@1+ (1,-40) [-40|210] "캜" Vector__XXX
 SG_ EngTrbCmprssrBypssActtr2OprtnStt : 28|4@1+ (1,0) [0|15] "" Vector__XXX
 SG_ EngTrbCmprssrBypssActtr1OprtnStt : 24|4@1+ (1,0) [0|15] "" Vector__XXX
 SG_ EngTrbCmprssrBypssActtr2TmpSttus : 21|3@1+ (1,0) [0|7] "" Vector__XXX
 SG_ EngTrbCmprssrBypssActtr2PrlmnryF : 16|5@1+ (1,0) [0|31] "" Vector__XXX
 SG_ EngDsrdTrbCmprssrBypssActtor2Pos : 8|8@1+ (0.4,0) [0|100] "%" Vector__XXX
 SG_ EngTrbCmprssorBypassActuator2Pos : 0|8@1+ (0.4,0) [0|100] "%" Vector__XXX

BO_ 2566714110 EFTVI1: 8 Vector__XXX
 SG_ EngFuelValve2OperationStatus : 60|4@1+ (1,0) [0|15] "" Vector__XXX
 SG_ EngFuelValve1OperationStatus : 56|4@1+ (1,0) [0|15] "" Vector__XXX
 SG_ EngThrottleValve2OperationStatus : 52|4@1+ (1,0) [0|15] "" Vector__XXX
 SG_ EngThrottleValve1OperationStatus : 48|4@1+ (1,0) [0|15] "" Vector__XXX
 SG_ EngFuelValve2TempStatus : 45|3@1+ (1,0) [0|7] "" Vector__XXX
 SG_ EngFuelValve2PreliminaryFMI : 40|5@1+ (1,0) [0|31] "" Vector__XXX
 SG_ EngFuelValve1TempStatus : 37|3@1+ (1,0) [0|7] "" Vector__XXX
 SG_ EngFuelValve1PreliminaryFMI : 32|5@1+ (1,0) [0|31] "" Vector__XXX
 SG_ EngThrottleValve2TempStatus : 29|3@1+ (1,0) [0|7] "" Vector__XXX
 SG_ EngThrottleValve2PreliminaryFMI : 24|5@1+ (1,0) [0|31] "" Vector__XXX
 SG_ EngDesiredThrottleValve2Pos : 16|8@1+ (0.4,0) [0|100] "%" Vector__XXX
 SG_ EngThrottleValve1TempStatus : 13|3@1+ (1,0) [0|7] "" Vector__XXX
 SG_ EngThrottleValve1PreliminaryFMI : 8|5@1+ (1,0) [0|31] "" Vector__XXX
 SG_ EngDesiredThrottleValve1Pos : 0|8@1+ (0.4,0) [0|100] "%" Vector__XXX

BO_ 2566717438 ET5: 8 Vector__XXX
 SG_ EngExhstGsRcrcltn2MxerIntakeTemp : 16|16@1+ (0.03125,-273) [-273|1734.96875] "캜" Vector__XXX
 SG_ EngExhaustGasRecirculation2Temp : 0|16@1+ (0.03125,-273) [-273|1734.96875] "캜" Vector__XXX

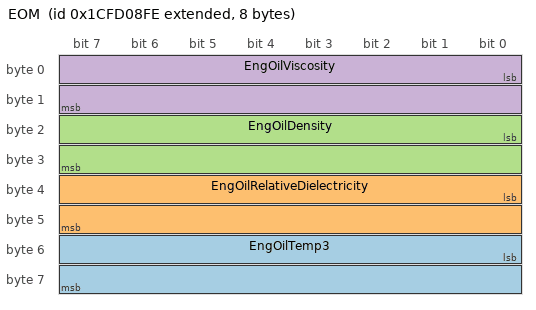
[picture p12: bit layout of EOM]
BO_ 2633828606 EOM: 8 Vector__XXX
 SG_ EngOilTemp3 : 48|16@1+ (0.03125,-273) [-273|1734.96875] "캜" Vector__XXX
 SG_ EngOilRelativeDielectricity : 32|16@1+ (0.0001220703125,0) [0|7.844] "" Vector__XXX
 SG_ EngOilDensity : 16|16@1+ (3.052E-005,0) [0|1.961] "g/cc" Vector__XXX
 SG_ EngOilViscosity : 0|16@1+ (0.015625,0) [0|1003.984375] "Cp" Vector__XXX

BO_ 2499607550 EMAP: 8 Vector__XXX
 SG_ EngExhstMnfldBnk2FlwBlncVlvActtr : 16|16@1+ (0.0025,0) [0|160.6375] "%" Vector__XXX
 SG_ EngExhstMnfldBnk1FlwBlncVlvActtr : 0|16@1+ (0.0025,0) [0|160.6375] "%" Vector__XXX

BO_ 2633825534 EMAC: 8 Vector__XXX
 SG_ EngExhstMnfldBnk2FlwBlncVlvActtr : 16|16@1+ (0.0025,0) [0|160.6375] "%" Vector__XXX
 SG_ EngExhstMnfldBnk1FlwBlncVlvActtr : 0|16@1+ (0.0025,0) [0|160.6375] "%" Vector__XXX

BO_ 2365400574 EJM9: 8 Vector__XXX
 SG_ Joystick9Button13PressedStatus : 62|2@1+ (1,0) [0|3] "" Vector__XXX
 SG_ Joystick9Button14PressedStatus : 60|2@1+ (1,0) [0|3] "" Vector__XXX
 SG_ Joystick9Button15PressedStatus : 58|2@1+ (1,0) [0|3] "" Vector__XXX
 SG_ Joystick9Button16PressedStatus : 56|2@1+ (1,0) [0|3] "" Vector__XXX
 SG_ Jystick9GripXAxisDetentPosStatus : 54|2@1+ (1,0) [0|3] "" Vector__XXX
 SG_ Jystick9GripYAxisDetentPosStatus : 52|2@1+ (1,0) [0|3] "" Vector__XXX
 SG_ Jystick9ThetaAxisDetentPosStatus : 50|2@1+ (1,0) [0|3] "" Vector__XXX
 SG_ Joystick9ThetaAxisPos : 38|10@1+ (0.1,0) [0|102] "%" Vector__XXX
 SG_ Jystck9ThtAxsClckwsPstvPosStatus : 36|2@1+ (1,0) [0|3] "" Vector__XXX
 SG_ Jystck9ThtAxsCntrClckwsNgtvPsStt : 34|2@1+ (1,0) [0|3] "" Vector__XXX
 SG_ Jystck9ThetaAxisNeutralPosStatus : 32|2@1+ (1,0) [0|3] "" Vector__XXX
 SG_ Joystick9GripYAxisPos : 22|10@1+ (0.1,0) [0|102] "%" Vector__XXX
 SG_ Jystck9GrpYAxsLvrFrwrdPstvPsStts : 20|2@1+ (1,0) [0|3] "" Vector__XXX
 SG_ Jystck9GrpYAxsLvrBckNgtvPsStatus : 18|2@1+ (1,0) [0|3] "" Vector__XXX
 SG_ Jystck9GripYAxisNeutralPosStatus : 16|2@1+ (1,0) [0|3] "" Vector__XXX
 SG_ Joystick9GripXAxisPos : 6|10@1+ (0.1,0) [0|102] "%" Vector__XXX
 SG_ Jystck9GrpXAxsLvrRghtPstvPsSttus : 4|2@1+ (1,0) [0|3] "" Vector__XXX
 SG_ Jystck9GrpXAxsLvrLftNgtvPsStatus : 2|2@1+ (1,0) [0|3] "" Vector__XXX
 SG_ Jystck9GripXAxisNeutralPosStatus : 0|2@1+ (1,0) [0|3] "" Vector__XXX

BO_ 2365401086 EJM8: 8 Vector__XXX
 SG_ Joystick8Button13PressedStatus : 62|2@1+ (1,0) [0|3] "" Vector__XXX
 SG_ Joystick8Button14PressedStatus : 60|2@1+ (1,0) [0|3] "" Vector__XXX
 SG_ Joystick8Button15PressedStatus : 58|2@1+ (1,0) [0|3] "" Vector__XXX
 SG_ Joystick8Button16PressedStatus : 56|2@1+ (1,0) [0|3] "" Vector__XXX
 SG_ Jystick8GripXAxisDetentPosStatus : 54|2@1+ (1,0) [0|3] "" Vector__XXX
 SG_ Jystick8GripYAxisDetentPosStatus : 52|2@1+ (1,0) [0|3] "" Vector__XXX
 SG_ Jystick8ThetaAxisDetentPosStatus : 50|2@1+ (1,0) [0|3] "" Vector__XXX
 SG_ Joystick8ThetaAxisPos : 38|10@1+ (0.1,0) [0|102] "%" Vector__XXX
 SG_ Jystck8ThtAxsClckwsPstvPosStatus : 36|2@1+ (1,0) [0|3] "" Vector__XXX
 SG_ Jystck8ThtAxsCntrClckwsNgtvPsStt : 34|2@1+ (1,0) [0|3] "" Vector__XXX
 SG_ Jystck8ThetaAxisNeutralPosStatus : 32|2@1+ (1,0) [0|3] "" Vector__XXX
 SG_ Joystick8GripYAxisPos : 22|10@1+ (0.1,0) [0|102] "%" Vector__XXX
 SG_ Jystck8GrpYAxsLvrFrwrdPstvPsStts : 20|2@1+ (1,0) [0|3] "" Vector__XXX
 SG_ Jystck8GrpYAxsLvrBckNgtvPsStatus : 18|2@1+ (1,0) [0|3] "" Vector__XXX
 SG_ Jystck8GripYAxisNeutralPosStatus : 16|2@1+ (1,0) [0|3] "" Vector__XXX
 SG_ Joystick8GripXAxisPos : 6|10@1+ (0.1,0) [0|102] "%" Vector__XXX
 SG_ Jystck8GrpXAxsLvrRghtPstvPsSttus : 4|2@1+ (1,0) [0|3] "" Vector__XXX
 SG_ Jystck8GrpXAxsLvrLftNgtvPsStatus : 2|2@1+ (1,0) [0|3] "" Vector__XXX
 SG_ Jystck8GripXAxisNeutralPosStatus : 0|2@1+ (1,0) [0|3] "" Vector__XXX

BO_ 2365401598 EJM7: 8 Vector__XXX
 SG_ Joystick7Button13PressedStatus : 62|2@1+ (1,0) [0|3] "" Vector__XXX
 SG_ Joystick7Button14PressedStatus : 60|2@1+ (1,0) [0|3] "" Vector__XXX
 SG_ Joystick7Button15PressedStatus : 58|2@1+ (1,0) [0|3] "" Vector__XXX
 SG_ Joystick7Button16PressedStatus : 56|2@1+ (1,0) [0|3] "" Vector__XXX
 SG_ Jystick7GripXAxisDetentPosStatus : 54|2@1+ (1,0) [0|3] "" Vector__XXX
 SG_ Jystick7GripYAxisDetentPosStatus : 52|2@1+ (1,0) [0|3] "" Vector__XXX
 SG_ Jystick7ThetaAxisDetentPosStatus : 50|2@1+ (1,0) [0|3] "" Vector__XXX
 SG_ Joystick7ThetaAxisPos : 38|10@1+ (0.1,0) [0|102] "%" Vector__XXX
 SG_ Jystck7ThtAxsClckwsPstvPosStatus : 36|2@1+ (1,0) [0|3] "" Vector__XXX
 SG_ Jystck7ThtAxsCntrClckwsNgtvPsStt : 34|2@1+ (1,0) [0|3] "" Vector__XXX
 SG_ Jystck7ThetaAxisNeutralPosStatus : 32|2@1+ (1,0) [0|3] "" Vector__XXX
 SG_ Joystick7GripYAxisPos : 22|10@1+ (0.1,0) [0|102] "%" Vector__XXX
 SG_ Jystck7GrpYAxsLvrFrwrdPstvPsStts : 20|2@1+ (1,0) [0|3] "" Vector__XXX
 SG_ Jystck7GrpYAxsLvrBckNgtvPsStatus : 18|2@1+ (1,0) [0|3] "" Vector__XXX
 SG_ Jystck7GripYAxisNeutralPosStatus : 16|2@1+ (1,0) [0|3] "" Vector__XXX
 SG_ Joystick7GripXAxisPos : 6|10@1+ (0.1,0) [0|102] "%" Vector__XXX
 SG_ Jystck7GrpXAxsLvrRghtPstvPsSttus : 4|2@1+ (1,0) [0|3] "" Vector__XXX
 SG_ Jystck7GrpXAxsLvrLftNgtvPsStatus : 2|2@1+ (1,0) [0|3] "" Vector__XXX
 SG_ Jystck7GripXAxisNeutralPosStatus : 0|2@1+ (1,0) [0|3] "" Vector__XXX

CM_ BO_ 2566730238 "Fan Drive #2
This parameter group transfers status and measured information for a second engine coolant fan.  For systems with a single or the primary fan, see PGN 65213.";
CM_ SG_ 2566730238 Fan2DriveBypassCmdStatus "Status of the Fan Drive Bypass Command for the second fan as being commanded by the ECU.  The fan drive bypass diverts pump pressure away from the hydraulic motor to maintain the fan drive pressure.  0% is defined as no bypass (i.e. diverting no fan ...";
CM_ SG_ 2566730238 HydFan2MotorPress "The hydraulic pressure used to drive the second fan system, sensed before the hydraulic fan motor.";
CM_ SG_ 2566730238 Fan2Speed "The speed of the second fan associated with engine coolant system.";
CM_ SG_ 2566730238 Fan2DriveState "This parameter is used to indicate the current state or mode of operation by the second fan drive.
0000 Fan off
0001 Engine system-General
0010 Excessive engine air temperature
0011 Excessive engine oil temperature
0100 Excessive engine coolant ...";
CM_ SG_ 2566730238 EstPercentFan2Speed "Estimated fan speed as a ratio of the fan drive (current speed) to the fully engaged fan drive (maximum fan speed).  A two state fan (off/on) will use 0% and 100% respectively.  A three state fan (off/intermediate/on) will use 0%, 50% and 100% ...";
CM_ BO_ 2566711038 "Vehicle/Chassis Lubrication System 2
Reports vehicle/chassis lubrication systems status";
CM_ SG_ 2566711038 LubricationTimingCycleStatus "Reports the status of the lubrication activation clock.
00 - Paused
01 - Enabled
10 - Error
11 - Not available or not installed
Note:  In some vehicles or machines, lubrication is only required when the vehicle or machine is in certain state e ...";
CM_ SG_ 2566711038 LubricationReservoirLevel "Reports the status of the lubrication system reservior level.  The lubrication reservoir stores the grease for the lubrication system. The lubrication pump draws grease from this reservoir and pushes it into the vehicle/chassis joints
00 - ...";
CM_ SG_ 2566711038 LubricationPumpEnableStatus "Reports the operational status of the lubrication system pump.  In the disabled state, the lubrication pump will not run a lubrication cycle.  In the enabled state, the lubrication system will perform normal operations.
00 - Disabled
01 - Enabled
 ...";
CM_ SG_ 2566711038 LubricationOperationModeStatus "Reports the current operational mode status of the lubrication system.
Automatic is the normal operation mode of lubrication system. In this mode the operator has the privilege to change duty cycle mode, if the lubrication mode in not locked.
In ...";
CM_ SG_ 2566711038 LubricationCycleModeStatus "Reports the current lubrication cycle mode of the lubrication system
000 - Cycle mode # 1 (Lowest Lubrication Frequency)
001 - Cycle mode # 2
010 - Cycle mode # 3 (Highest Lubrication Frequency)
011 to 101 - Reserved
110 - Error
111 - Not ...";
CM_ SG_ 2566711038 LubricationCycleModeLockStatus "Reports status of the ability to change the lubrication cycle mode.  Locking the lubrication mode would prevent the changing of the lubrication cycle mode, perhaps by an operator

00 - Not Locked
01 - Locked
10 - Error
11 - Not available";
CM_ BO_ 2566710782 "Hydraulic Oil Properties
Hydraulic Oil Properties.  This hydraulic fluid is for the entire hydraulics system of a piece of equipment.";
CM_ SG_ 2566710782 HydOilTemp "Hydraulic Oil Temperature.  This hydraulic fluid is for the entire hydraulics system of a piece of equipment.";
CM_ SG_ 2566710782 HydOilRelativeDielectricity "Hydraulic oil relative dielectricity used to describe the hydraulic oil quality.  This hydraulic fluid is for the entire hydraulics system of a piece of equipment.";
CM_ SG_ 2566710782 HydOilDensity "Density of hydraulic oil.  This hydraulic fluid is for the entire hydraulics system of a piece of equipment.";
CM_ SG_ 2566710782 HydOilDynamicViscosity "Dynamic viscosity of hydraulic oil.  This hydraulic fluid is for the entire hydraulics system of a piece of equipment.";
CM_ BO_ 2566710526 "Engine Fuel Properties
Engine Fuel Properties";
CM_ SG_ 2566710526 EngFuelTemp "Engine Fuel Temperature of the first fuel type. See also SPNs 174 or 3468 for alternate resolution.";
CM_ SG_ 2566710526 EngFuelDielectricity "Engine fuel relative dielectricity.";
CM_ SG_ 2566710526 EngFuelDensity "Density of engine fuel";
CM_ SG_ 2566710526 EngFuelDynamicViscosity "Dynamic viscosity of engine fuel";
CM_ BO_ 2432492542 "Engine Exhaust Brake Control
Contains information about the engine exhaust brake system control.";
CM_ SG_ 2432492542 DsredEngTurbo2TurbineOutletPress "The desired gage pressure of the combustion by-products exiting the turbine side of the turbocharger 2 at the current engine operating conditions.";
CM_ SG_ 2432492542 EngTurbo2TurbineOutletPress "Gage pressure of the combustion by-products exiting the turbine side of the turbocharger 2.";
CM_ SG_ 2432492542 EngExhaustBrakeActuatorCmd "The control command applied to the engine exhaust brake actuator, where 0% represents no braking and 100% represents full braking.";
CM_ SG_ 2432492542 DsredEngTurbo1TurbineOutletPress "The desired gage pressure of the combustion by-products exiting the turbine side of the turbocharger 1 at the current engine operating conditions.";
CM_ SG_ 2432492542 EngTurbo1TurbineOutletPress "Gage pressure of the combustion by-products exiting the turbine side of the turbocharger 1.";
CM_ BO_ 2566710014 "Supplemental Fan Status
The status of Supplemental Fan. This is a supplemental fan used for additional cooling beyond that of the primary cooling fan system. For example, this fan could be used to provide additional cooling to an aftertreatment ...";
CM_ SG_ 2566710014 SupplementalFanPower "Estimated Power output of Supplemental Fan";
CM_ SG_ 2566710014 SupplementalFanCurrent "Measured electrical current of supplemental fan drive.";
CM_ SG_ 2566710014 SupplementalFanSpeed "Measured speed of supplemental fan.";
CM_ SG_ 2566710014 SupplementalFanCtrlECUTemp "Measured temperature of Supplemental Fan Controller ECU.";
CM_ SG_ 2566710014 SupplementalFanDriveStatus "The drive status of the Supplemental Fan. This status parameter indicates the overall health of the fan drive. It will indicate that the fan is working OK or if there is an internal fault such as open winding or internal short circuit.
0000 ...";
CM_ SG_ 2566710014 SupplementalFanCtrlTempStatus "Internal Controller Temperature Status of Supplemental Fan.

000   High most severe 
001   High Least severe 
010   In Range 
011   Low Least severe 
100   Low Most severe 
101   Not Defined 
110   Error 
111   Not available";
CM_ SG_ 2566710014 SupplementalFanVelocityStatus "Status of the rotational velocity of Supplemental Fan. Used to indicate if the fan is spinning at the desired speed. If fan is not able to obtain the commanded speed, velocity error is indicated. If fan is unable to spin, the fan is in Fan Stall ...";
CM_ SG_ 2566710014 SupplementalFanDirectionStatus "Rotational Direction of Supplemental Fan. Fan could be spinning forward or reverse.

00   Forward
01   Reverse
10   Error
11   Not available/Not installed";
CM_ SG_ 2566710014 SupplementalFanEnableStatus "Enable/Disable Status of Supplemental Fan.

00   Disabled
01   Enabled
10   Error
11   Not available/Not installed";
CM_ BO_ 2566709758 "Fuel Economy 2 (Liquid)";
CM_ SG_ 2566709758 EngDieselFuelDemandRate "Amount of diesel fuel that would be consumed by an engine per unit of time if it were not substituting gaseous fuel.  This parameter is the sum of SPN 183 and the amount of diesel fuel that is being displaced by gaseous fuel.  If the engine is not ...";
CM_ SG_ 2566709758 HighResolutionEngFuelRate "Amount of fuel consumed by engine per unit of time.  

NOTE - See SPN 183 for alternate resolution.";
CM_ BO_ 2566709502 "Diesel Particulate Filter Control 2
The purpose of this PGN is to group parameters about the diesel particulate filter regeneration control.";
CM_ SG_ 2566709502 AFT2FuelMassRate "Mass rate of total fuel being delivered to Atertreatment 2 for DPF regeneration.";
CM_ SG_ 2566709502 AFT1FuelMassRate "Mass rate of total fuel being delivered to aftertreatment 1 for DPF regeneration.";
CM_ SG_ 2566709502 RelativeUnburnedFuelMassFromEng "The unburned amount of diesel fuel coming out of the engine. This fuel increases the temperature while oxidated in the DOC. Therefore, this amount of fuel also needs to be taken into account of the HCD temperature controller.";
CM_ SG_ 2566709502 AFT1DPFInTempSetPoint "Set point temperature for the particulate filter (DPF) regeneration at the intake to the DPF for Exhaust bank 1.";
CM_ BO_ 2566709246 "Engine Fluid Level/Pressure 12
12th PGN which identifies parameters that are either measuring various pressures within the engine or identifying engine fluid levels";
CM_ SG_ 2566709246 ThrottleVlv2DiffPress "The differential pressure between the intake and outlet of the throttle valve 2 (SPN 3673). The differential pressure is measured from the intake with respect to the outlet of the throttle valve.";
CM_ SG_ 2566709246 EngFuelSupplyPumpIntakeAbsPress "Absolute pressure of fuel at the fuel supply pump intake. See Figures SPN16_A & SPN16_B. See SPN 1381 for alternate resolution.

Engine Fuel Supply Pump Intake Absolute Pressure (Extended Range)";
CM_ SG_ 2566709246 EngFuelReturnPress "Used to read fuel (or gas) pressure passing through the return line.";
CM_ SG_ 2566709246 EngFuelFilterDegradation "The estimated percentage relative to the useful life of the engine fuel filter.
This is not a calculation of the physical restriction of the filter.  0% is typical of a new filter.  100% is typical of an end of life filter, the filter should be ...";
CM_ SG_ 2566709246 EngFilteredFuelDeliveryAbsPress "Absolute pressure of fuel in system as delivered from supply pump to the injection pump after the pressure side fuel filter.  See SPN 5579 for gage pressure of fuel in system after the pressure side fuel filter.";
CM_ SG_ 2566709246 EngFilteredFuelDeliveryPress "Gage pressure of fuel in system as delivered from supply pump to the injection pump after the pressure side fuel filter.  See SPN 5580 for absolute pressure of fuel in system after the pressure side fuel filter.";
CM_ SG_ 2566709246 EngFuelDeliveryAbsPress "Absolute pressure of fuel in system as delivered from supply pump to the injection pump.  See also SPN 94 for Fuel Delivery Pressure (Gage).";
CM_ BO_ 2566708990 "Aftertreatment 1 Air Control 3
This PGN contains information about the Aftertreatment 1 Air Control.
NOTE: This message will be transmitted by the engine or aftertreatment controller. Other aftertreatment air control information could be added in ...";
CM_ SG_ 2566708990 SecondAirAbsPress "Absolute pressure of the secondary air for aftertreatment 1. Secondary air is air provided to the exhaust system (per SAE J2403).

For gage pressure, see SPN 3837.";
CM_ BO_ 2566708734 "Aftertreatment 2 Air Control 3
This PGN contains information about the Aftertreatment 2 Air Control.
NOTE: This message will be transmitted by the engine or aftertreatment controller. Other aftertreatment air control information could be added in ...";
CM_ SG_ 2566708734 SecondAirAbsPress "Absolute pressure of the secondary air for aftertreatment 2. Secondary air is air provided to the exhaust system (per SAE J2403).

For gage pressure, see SPN 3838.";
CM_ BO_ 2566708478 "Cruise Control / Vehicle Speed 3
Cruise Control / Vehicle Speed 3";
CM_ SG_ 2566708478 DriverCancellationStatus "State signal which indicates that the cruise control is cancelled by driver action.  Driver actions could include switch off, brake pedal activation, clutch pedal actuation, cancel switch, or other reasons determined by the cruise control ...";
CM_ SG_ 2566708478 CruiseCtrlSpeed "This parameter is the vehicle speed that the cruise control algorithm is currently using as its cruise control set point.
Cruise Control Speed (SPN 7319) will include the effects of other algorithms, such as Predictive Cruise Control, Adaptive ...";
CM_ SG_ 2566708478 CruiseCtrlSetSpeed "Value of set (chosen) velocity of velocity control system. See SPN 86 for an alternate resolution.
If an algorithm that can modify the cruise control set point exists in the system, such as Predictive Cruise Control or Adaptive Cruise Control, then ...";
CM_ SG_ 2566708478 PrdctvCrsCtrlStSpeedOffsetStatus "This parameter indicates if the cruise control algorithm is currently adding the value in Predictive Cruise Control Set Speed Offset (SPN 7316) to the Cruise Control Set Speed (SPN 86 or SPN 6809) for its set point. The final set point will be ...";
CM_ SG_ 2566708478 AEBSReadinessState "Advanced emergency braking systems (AEBS) will limit the engine torque via TSC1 during warning and braking phases. Therefore the engine controller gives a feedback to the AEBS if it is configured and able to obey these limitation commands.
00 - Off ...";
CM_ SG_ 2566708478 SrcAddrssOfCntrllngDvcFrPsngCrsC "The source address of the SAE J1939 device that is currently sending the Cruise Control Pause Command (SPN 5605).
If there are multiple devices sending Cruise Control Pause Command with a value of 01, then the value transmitted for this parameter ...";
CM_ SG_ 2566708478 SrcAddrssOfCntrllngDvcFrDsblngCr "The source address of the SAE J1939 device that is currently sending the Cruise Control Disable Command (SPN 5603).
If there are multiple devices sending Cruise Control Disable Command with a value of 01, then the value transmitted for this ...";
CM_ SG_ 2566708478 CruiseCtrlSystemCmdState "Indicates the current state of the cruise control system due to the Cruise Control System Commands, which include Cruise Control Disable Command (SPN 5603), Cruise Control Resume Command (SPN 5604), and Cruise Control Pause Command (SPN 5605).
000 ...";
CM_ SG_ 2566708478 AdptiveCruiseCtrlReadinessStatus "This parameter is used to indicate an application's state of readiness for responding to commands from an adaptive cruise control system controller.
00 - Off -- Cruise Control System is not configured to accept commands from an adaptive cruise ...";
CM_ BO_ 2566708222 "Aftertreatment 1 Diesel Particulate Filter 1 Soot 3
This message is used to specify up to 4 soot sensor analysis frequencies to request the soot sensor signal data associated with those analysis frequencies for aftertreatment 1 diesel particulate ...";
CM_ SG_ 2566708222 SnsrAnalysisReqFreq4 "Fourth requested analysis frequency for the diesel particulate filter 1 soot sensor.";
CM_ SG_ 2566708222 SnsrAnalysisReqFreq3 "Third requested analysis frequency for the diesel particulate filter 1 soot sensor.";
CM_ SG_ 2566708222 SnsrAnalysisReqFreq2 "Second requested analysis frequency for the diesel particulate filter 1 soot sensor.";
CM_ SG_ 2566708222 SnsrAnalysisReqFreq1 "First requested analysis frequency for the diesel particulate filter 1 soot sensor.";
CM_ BO_ 2566707966 "Aftertreatment 1 Diesel Particulate Filter 1 Soot 4
This message is used report the analysis frequency and associated soot sensor signal data for two of the requested analysis frequencies for the aftertreatment 1 diesel particulate filter 1.";
CM_ SG_ 2566707966 SnsrFreq2SootSignal "The soot signal attenuation measurement for analysis frequency 2 for the diesel particulate filter 1 soot sensor.  See SPN 5633.";
CM_ SG_ 2566707966 SnsrAnalysisFreq2 "The analysis frequency associated with the frequency 2 soot signal for the diesel particulate filter 1 soot sensor.  See SPN 5633.";
CM_ SG_ 2566707966 SnsrFreq1SootSignal "The soot signal attenuation measurement for analysis frequency 1 for the diesel particulate filter 1 soot sensor.  See SPN 5632.";
CM_ SG_ 2566707966 SnsrAnalysisFreq1 "The analysis frequency associated with the frequency 1 soot signal for the diesel particulate filter 1 soot sensor.  See SPN 5632.";
CM_ BO_ 2566707710 "Aftertreatment 1 Diesel Particulate Filter 1 Soot 5
This message is used report the analysis frequency and associated soot sensor signal data for two of the requested analysis frequencies for the aftertreatment 1 diesel particulate filter 1.";
CM_ SG_ 2566707710 SnsrFreq4SootSignal "The soot signal attenuation measurement for analysis frequency 4 for the diesel particulate filter 1 soot sensor.  See SPN 5635.";
CM_ SG_ 2566707710 SnsrAnalysisFreq4 "The analysis frequency associated with the frequency 4 soot signal for the diesel particulate filter 1 soot sensor.  See SPN 5635.";
CM_ SG_ 2566707710 SnsrFreq3SootSignal "The soot signal attenuation measurement for analysis frequency 3 for the diesel particulate filter 1 soot sensor.  See SPN 5634.";
CM_ SG_ 2566707710 SnsrAnalysisFreq3 "The analysis frequency associated with the frequency 3 soot signal for the diesel particulate filter 1 soot sensor.  See SPN 5634.";
CM_ BO_ 2561343230 "Client (ECU) to File Server message
Used for send Status of the client to the file server, volume handling, file access, file handling and directory handling.  Description of messages is given in ISO 11783 Part 13.";
CM_ BO_ 2566749694 "Reserved for FMS Telltale status
Reserved for FMS Telltale Status";
CM_ BO_ 2297441790 "Acceleration Sensor
The acceleration sensor message shall provide a measurement of the vehicle's acceleration in the lateral, longitudinal, and vertical axes.  The vehicle dynamics measurements in this message shall be according to a Z-Up axis ...";
CM_ SG_ 2297441790 SpprtVrblTrnsRpttnRtFrAcclrtnSns "Indicates which acceleration transmission rate are supported by the ECU in addition to the required 10 ms transmission rate.
00 - Reserve for SAE assignment
01 - Reserved for SAE assignment
10 - 20 ms rate supported
11 - ECU only supports ...";
CM_ SG_ 2297441790 VrtclAcclrtnExRangeFigureOfMerit "Figure of merit for vertical acceleration measurement.
00 = vertical acceleration is fully functional.  Data is within sensor specification
01 = verticalacceleration is degraded.  Data is suspect due to enviromental conditions
10 = error
11 = ...";
CM_ SG_ 2297441790 LngtdnlAcclrtnExRngFigureOfMerit "Figure of merit for longitudinal acceleration measurement.
00 = longitudinal acceleration is fully functional.  Data is within sensor specification
01 = longitudinal acceleration is degraded.  Data is suspect due to enviromental conditions
10 = ...";
CM_ SG_ 2297441790 LtrlAcclrtonExRangeFigureOfMerit "Figure of merit for lateral acceleration measurement.
00 = lateral acceleration is fully functional.  Data is within sensor specification
01 = lateral acceleration is degraded.  Data is suspect due to enviromental conditions
10 = error
11 = not ...";
CM_ SG_ 2297441790 VerticalAccelerationExRange "Indicates vertical acceleration of the vehicle and the effect of gravity (the component of vehicle acceleration vector along the Z-axis).  A positive vertical acceleration signal of 1 gravity results when the vehicle is stationary on a horizontal ...";
CM_ SG_ 2297441790 LongitudinalAccelerationExRange "Indicates longitudinal acceleration of the vehicle (the component of vehicle acceleration vector along the X-axis).  A positive longitudinal acceleration signal results when the vehicle speed increases in the forward direction.  Longitudinal ...";
CM_ SG_ 2297441790 LateralAccelerationExRange "Indicates lateral acceleration of the vehicle (the component of vehicle acceleration vector along the Y-axis).  A positive lateral acceleration signal results when the vehicle is accelerated to the left.  This parameter is defined according to a ...";
CM_ BO_ 2566699006 "Hybrid System Status 2
Status information of a hybrid system.";
CM_ SG_ 2566699006 PropulsionModeRemainingDist "While in a Hybrid Propulsion Mode (see SPN 7889) other than Mode 1 - Stored Energy Source Sustaining, this reports a count down of the remaining distance until the mode is exited.  When the requested Hybrid Propulsion Mode (see SPN 7889) changes, it ...";
CM_ SG_ 2566699006 PropulsionModeMaxSpdSetting "The maximum speed setting as requested using Hybrid Propulsion Mode Requested Maximum Speed (SPN 9706).
A value of FBh indicates that the sender supports this parameter, but there is currently no requested limit.
A value of FFh indicates that this ...";
CM_ SG_ 2566699006 EngStopStartRemainingPercentage "Indicates the remaining percentage of engine stop-start operation allowed by the hybrid system.
The calculation of the percentage is manufacturer specific.  It is an operational limitation, not a functional one, meaning the hybrid system could ...";
CM_ SG_ 2566699006 HybridBatteryPackRemainingCharge "Indicates the hybrid battery pack remaining charge. 0% means no charge remaining, 100% means full charge remaining.";
CM_ BO_ 2364549630 "Slope Sensor Information 2
The Slope Sensor Information 2 message shall provide a measurement of the vehicle's extended pitch angle and a measurement of the vehicle's extended roll angle.  The vehicle dynamics measurements in this message shall be ...";
CM_ SG_ 2364549630 RllAndPtchExRngMasurementLatency "Time between start of sensor processing and CAN transmission";
CM_ SG_ 2364549630 RollAngleExRangeFigureOfMerit "Figure of merit for roll angle measurement.

00 = Roll angle fully functional. Data is within sensor specification.
01 = Roll angle degraded. Data is suspect due to environmental conditions.
10 = Error
11 = Not available";
CM_ SG_ 2364549630 RollAngleExRangeCompensation "Compensated mode for the roll angle measurement.  Compensation is the use of multiple sensors together to enhance the output of the roll angle measurement.

00 = On
01 = Off
10 = Error
11 = Not Available";
CM_ SG_ 2364549630 PitchAngleExRangeFigureOfMerit "Figure of merit for pitch angle measurement.

00 = Pitch angle fully functional. Data is within sensor specification.
01 = Pitch angle degraded. Data is suspect due to environmental conditions.
10 = Error
11 = Not available";
CM_ SG_ 2364549630 PitchAngleExRangeCompensation "Compensated mode for the pitch measurement.  Compensation is the use of multiple sensors together to enhance the output of the pitch measurement.

00 = On
01 = Off
10 = Error
11 = Not Available";
CM_ SG_ 2364549630 RollAngleExRange "The angle between the vehicle y-axis and the ground plane (i.e. rotation about the X-axis).  The roll angle for a roll to the right is reported with a positive value. Roll angle is the same for both Z-Down and Z-Up axis systems, since both systems ...";
CM_ SG_ 2364549630 PitchAngleExRange "The angle between the vehicle x-axis and the ground plane (i.e. rotation about the vehicle Y-axis).  The pitch angle for an angle of ascent is reported with a positive value. This parameter is defined according to a Z-Down axis system and the sign ...";
CM_ BO_ 2499614462 "Occupant Classification System Information
Message containing status of Occupant Classification System for driver, passenger and rear seating positions. The PGN becomes updated every time a Beltlock Status changes in the Beltlock and Airbag ...";
CM_ SG_ 2499614462 OccpntClssficationSystem10Status "State of Occupant Classification System for seat position 10.

00 = empty
01 = occupied
10 = Error - Classification cannot be determined
11 = not available";
CM_ SG_ 2499614462 OccpntClssificationSystem9Status "State of Occupant Classification System for seat position 9.

00 = empty
01 = occupied
10 = Error - Classification cannot be determined
11 = not available";
CM_ SG_ 2499614462 OccpntClssificationSystem8Status "State of Occupant Classification System for seat position 8.

00 = empty
01 = occupied
10 = Error - Classification cannot be determined
11 = not available";
CM_ SG_ 2499614462 OccpntClssificationSystem7Status "State of Occupant Classification System for seat position 7.

00 = empty
01 = occupied
10 = Error - Classification cannot be determined
11 = not available";
CM_ SG_ 2499614462 OccpntClssificationSystem6Status "State of Occupant Classification System for seat position 6.

00 = empty
01 = occupied
10 = Error - Classification cannot be determined
11 = not available";
CM_ SG_ 2499614462 OccpntClssificationSystem5Status "State of Occupant Classification System for seat position 5.

00 = empty
01 = occupied
10 = Error - Classification cannot be determined
11 = not available";
CM_ SG_ 2499614462 OccpntClssificationSystem4Status "State of Occupant Classification System for seat position 4.

00 = empty
01 = occupied
10 = Error - Classification cannot be determined
11 = not available";
CM_ SG_ 2499614462 OccpntClssificationSystem3Status "State of Occupant Classification System for seat position 3.

00 = empty
01 = occupied
10 = Error - Classification cannot be determined
11 = not available";
CM_ SG_ 2499614462 PssngrOccpntClssfctnSystemStatus "State of Occupant Classification System for passenger.

000 = empty
001 = child
010 = small adult
011 = adult
100 = large adult
101 = Error - Classification of occupant cannot be determined
110 = reserved
111 = not available";
CM_ SG_ 2499614462 DrvrOccpntClssfctionSystemStatus "State of Occupant Classification System for driver.

000 = empty
001 = child
010 = small adult
011 = adult
100 = large adult
101 = reserved
110 = Error - Classification of occupant cannot be determined
111 = not available";
CM_ BO_ 2560098046 "Noise Control Status
Used to report the current state of the Noise Control System.";
CM_ SG_ 2560098046 CabNoiseCtrlTuningStatus "This parameter returns the current status of tuning function of the Cab Noise Control system.    When the tuning state is active, the Cab Noise Control System adjusts certain system characteristics (e.g. to account for sensor and/or transducer ...";
CM_ SG_ 2560098046 CabNoiseCtrlStatus "This parameter returns the current status of the Cab Noise Control system.

00 - Cab Noise Control System ON-Line
01 - Cab Noise Control System OFF-Line
10 - Error Indicator
11 - Not Available/Not Requested";
CM_ BO_ 2560163582 "Noise Control 1
Used to issue commands to the Noise Control System.  This command PGN typically originates from either a Cab control panel or a diagnostic tool.";
CM_ SG_ 2560163582 CabNoiseCtrlTuningCmd "Command values for the Tuning State of the Cab Noise Control System.  The Tuning State allows the Cab Noise Control System to adjust certain system characteristics (e.g. to account for microphone or speaker degradation over time).
000 - Activate ...";
CM_ SG_ 2560163582 CabNoiseCtrlCmd "Command signal to change the state of the Cab Noise Control System to on-line or off-line

00 - Take Cab Noise Control System Off Line
01 - Bring Cab Noise Control System On Line
10 - Reserved
11 - Don't Care/Not Commanded";
CM_ BO_ 2297441534 "Magnet Status Information 2
This message carries data related to the status of the magnetic material handling system, possibly including the generator that provides power to the magnet.";
CM_ SG_ 2297441534 MagnetGeneratorCtrl "Command signal used to Enable and Disable the Generator controlling a Magnet.

00  Off, Disable Generator
01  On, Enable Generator
10  Reserved
11  Take No Action";
CM_ SG_ 2297441534 DropRelayCtrl "Command signal used to Engage and Disengage the Drop Relay controlling a Steady-State Magnet.

00 = Off, Disable Drop Relay Request
01 = On, Enable Drop Relay Request
10 = Reserved
11 = Take No Action";
CM_ SG_ 2297441534 LiftRelayCtrl "Command signal used to Engage and Disengage the Lift Relay controlling a Steady-State Magnet.

00 = Off, Disable Lift Relay Request 
01 = On, Enable Lift Relay Request
10 = Reserved
11 = Take No Action";
CM_ SG_ 2297441534 MaterialDropActiveStatus "The status of Material Drop Relay. When it is on, the generator generates reverse direction current so that the material handler machine can release material.

00 = Off
01 = On
10 = Error
11 = Not Available";
CM_ SG_ 2297441534 MaterialLiftActiveStatus "The status of Material Lift Relay. When it is on, the generator generates forward direction current so that the material handler machine can pick up material.

00 = Off
01 = On
10 = Error
11 = Not Available";
CM_ SG_ 2297441534 GneratorCurrentBoostActiveStatus "Status of generator current boost relay that can boost the generator output current for picking-up material operations. When this relay is \"on\", the generator is generating the maximum current for the material handler machine to pick-up material ...";
CM_ SG_ 2297441534 MaterialDropSwitch "This is a switch that can be used to enable the drop functionality of the Material Handler machine.

00 = Don't Drop
01 = Drop
10 = Error
11 = Not Available";
CM_ SG_ 2297441534 MaterialLiftSwitch "This is a switch that can be used to enable the lift functionality of the Material Handler machine. When it is activated, the magnet is energized to pick up material.

00 = Don't Lift
01 = Lift
10 = Error
11 = Not Available";
CM_ SG_ 2297441534 MagnetReverseCurrent "A reverse current being supplied to the electric magnet to reduce the forward current generated magnet field as quick as possible so that the magnet can release material as fast as possible.";
CM_ SG_ 2297441534 MagnetForwardCurrent "The forward current being supplied by the generator to the electric magnet to create a magnet field to lift material.";
CM_ BO_ 2566722302 "Magnet Status Information 1
This message carries data related to the status of the magnetic material handling system, possibly including the generator that provides power to the magnet.";
CM_ SG_ 2566722302 GeneratorDutyCycleExceededStatus "The status of the duty cycle of the generator usage, indicating if the generator has been on for too much time within a defined time window.  The duty cycle is the ratio of the time the generator is on and the time the generator is off within a time ...";
CM_ SG_ 2566722302 VoltageMonitorActiveStatus "Status of Voltage Monitor Relay. When it is activated, the Generator Voltage Monitor is connected to the generator output line so that the generator output voltage range could be monitored.
00 = Monitor is Off
01 = Monitor is On
10 = Error
11 = ...";
CM_ SG_ 2566722302 GensetEnableActiveStatus "Status of the Genset Enable Relay that enables or disables the Genset.

00 = Not Enabled
01 = Enabled
10 = Error
11 = Not Avaialble";
CM_ SG_ 2566722302 ReverseCurrentRangeSetting "The operator setting for the Reverse Current. The setting defines the maximum reverse current. The actual current limits are specific to the application.
00000 = 1
00001 = 2
00010 = 3
00011 = 4
00100 = 5
00101 = 6
00110 = 7
00111 = 8
01000 ...";
CM_ SG_ 2566722302 GensetSoftstartActiveStatus "The Genset Softstart Active Status refers to the status of the genset softstart relay. The moment the Genset System is started, this relay is activated. As a result, the hydraulic power is hold on for a short period of time, and this relay will be ...";
CM_ SG_ 2566722302 Grapple_MagnetSelectionSwitch "This is a switch that can be used to select either the Grapple or Magnet function of the material handler machine.

00 = Grapple Selected
01 = Magnet Selected
10 = Error
11 = Not Available";
CM_ SG_ 2566722302 GnstSystmOtputVoltageRangeStatus "Status of generator voltage in or out of desired operating range.

00 = Out of Range 
01 = In Range
10 = Error
11 = Not Available";
CM_ SG_ 2566722302 GeneratorOverheatStatus "The Status of Generator being Overheated.

00 = Not Overheat
01 = Overheat
10 = Error
11 = Not Available";
CM_ BO_ 2566722558 "Magnet System Configuration Information
This message carries data related to the configuration of the magnetic material handling system, possibly including the generator that provides power to the magnet.";
CM_ SG_ 2566722558 MagnetRatedPower "The rated power that the magnet can accept during material holding operations.  Note that the magnet may experience more power over short intervals, such as during initial activation of the magnet circuit to pick up material.";
CM_ SG_ 2566722558 MagnetBoostTime "The duration of time after the activation of the magnet circuit that a relatively high current is sent to the magnet for material pick up operations. This time is called boost time. After the boost time expires, a lower operation current is sent to ...";
CM_ BO_ 2560032510 "Low Voltage Disconnect Set Operating Mode
Low Voltage Disconnect (LVD) Set Operating Mode is sent to the LVD to either manuallly override the normal LVD function and force the outputs to be disconnected or connected, or to put the LVD back into ...";
CM_ SG_ 2560032510 LwVltgDscnnctDsiredOperatingMode "Desired Operating Mode of the LVD.  Used to issue a J1939 request to the LVD to change modes.

0000 - Automatic
0001-0011 - Reserved
0100 - Manual Disconnect
0101 - Manual Connect
0110-1110 - Reserved
1111 - No change";
CM_ BO_ 2566717950 "Low Voltage Disconnect  Status
Status of the Low-Voltage Disconnect (LVD) device.";
CM_ SG_ 2566717950 LowVoltageDisconnectTemp "Internal temperature of the LVD.";
CM_ SG_ 2566717950 LwVltgeDisconnectVoutOutputState "State of the Vout Output from the LVD.  Vout is the LVD's main internal, controllable, high-current output.  If the LVD supports prioritization, this circuit will be the last to disconnect and the first to reconnect.
0000 - Output off or ...";
CM_ SG_ 2566717950 LowVoltageDisconnectOutput1State "State of the Output #1 from the LVD.  Output #1 controls an external load or relay.  This external load could be independent of the main output, and may apply to an application specific circuit or zone.  If the LVD supports prioritization, this ...";
CM_ SG_ 2566717950 LowVoltageDisconnectOutput2State "State of the Output #2 from the LVD.  Output #2 controls an external load or relay.  This external load could be independent of the main output, and may apply to an application specific circuit or zone.  If the LVD supports prioritization, this ...";
CM_ SG_ 2566717950 LowVoltageDisconnectOutput3State "State of the Output #3 from the LVD.  Output #3 controls an external load or relay.  This external load could be independent of the main output, and may apply to an application specific circuit or zone.  If the LVD supports prioritization, this ...";
CM_ SG_ 2566717950 LwVltgDscnnctCrrentOperatingMode "Current operating mode of the LVD.  The current mode is dependent on the state of the Manual Disconnect/Connect hardwired inputs and on the most-recent received LVD Set Desired Operating Mode message.  The hardwired inputs have priority over the LVD ...";
CM_ SG_ 2566717950 LwVltgDscnnectManualConnectState "State of the Manual Connect hardwired input to the LVD.  Manual Connect is used to override the LVD's normal activlty and connect all of the LVD outputs.  Manual Connect has priority over the Manual Dicsonnect hardwired input and all LVD Set ...";
CM_ SG_ 2566717950 LwVltgDscnnctMnalDisconnectState "State of the Manual Disconnect hardwired input to the LVD.  Manual Disconnect is used to override the LVD's normal activlty and dicconnect all of the LVD outputs.  Manual Disconnect is lower in priority than the Manual Connect hardwired input, but ...";
CM_ BO_ 2499604222 "Land Leveling System Reference Elevation Data
This PGN will be used to communicate the reference elvation information for the land leveling system.  It will communicate the left and right blade offset data and left and right elevation deviation ...";
CM_ SG_ 2499604222 BldReferenceElevationOffsetRight "Indicates the blade's right elevation offset with respect to the reference elevation.  An offset of 0 m represents no offset from the reference elevation.  A positive number indicates that the offset elevation is above the original reference ...";
CM_ SG_ 2499604222 BldeReferenceElevationOffsetLeft "Indicates the blade's left elevation offset with respect to the reference elevation.  An offset of 0 m represents no offset from the reference elevation.  A positive number indicates that the offset elevation is above the original reference ...";
CM_ SG_ 2499604222 BladeElevationDeviationRight "Indicate the blade's right elevation deviation with respect to the reference elevation.  Serves as an indication of how far the left end of the blade is above or below grade.  A positive number indicates that the blade is above the desired grade.  A ...";
CM_ SG_ 2499604222 BladeElevationDeviationLeft "Indicate the blade's left elevation deviation with respect to the reference elevation.  Serves as an indication of how far the left end of the blade is above or below grade.  A positive number indicates that the blade is above the desired grade.  A ...";
CM_ BO_ 2358902526 "Joystick Lamp Command Message
Used to transfer joystick lamp command informations which are used to switch on/off/blinking joystick 1...3 lamps 1...10.";
CM_ SG_ 2358902526 Joystick3Lamp10Cmd "Tells joystick 3 to switch on/off/blinking lamp 10.

00 - Off
01 - On
10 - Blinking
11 - Don't care / Take no action";
CM_ SG_ 2358902526 Joystick3Lamp9Cmd "Tells joystick 3 to switch on/off/blinking lamp 9.

00 - Off
01 - On
10 - Blinking
11 - Don't care / Take no action";
CM_ SG_ 2358902526 Joystick3Lamp8Cmd "Tells joystick 3 to switch on/off/blinking lamp 8.

00 - Off
01 - On
10 - Blinking
11 - Don't care / Take no action";
CM_ SG_ 2358902526 Joystick3Lamp7Cmd "Tells joystick 3 to switch on/off/blinking lamp 7.

00 - Off
01 - On
10 - Blinking
11 - Don't care / Take no action";
CM_ SG_ 2358902526 Joystick3Lamp6Cmd "Tells joystick 3 to switch on/off/blinking lamp 6.

00 - Off
01 - On
10 - Blinking
11 - Don't care / Take no action";
CM_ SG_ 2358902526 Joystick3Lamp5Cmd "Tells joystick 3 to switch on/off/blinking lamp 5.

00 - Off
01 - On
10 - Blinking
11 - Don't care / Take no action";
CM_ SG_ 2358902526 Joystick3Lamp4Cmd "Tells joystick 3 to switch on/off/blinking lamp 4.

00 - Off
01 - On
10 - Blinking
11 - Don't care / Take no action";
CM_ SG_ 2358902526 Joystick3Lamp3Cmd "Tells joystick 3 to switch on/off/blinking lamp 3.

00 - Off
01 - On
10 - Blinking
11 - Don't care / Take no action";
CM_ SG_ 2358902526 Joystick3Lamp2Cmd "Tells joystick 3 to switch on/off/blinking lamp 2.

00 - Off
01 - On
10 - Blinking
11 - Don't care / Take no action";
CM_ SG_ 2358902526 Joystick3Lamp1Cmd "Tells joystick 3 to switch on/off/blinking lamp 1.

00 - Off
01 - On
10 - Blinking
11 - Don't care / Take no action";
CM_ SG_ 2358902526 Joystick2Lamp10Cmd "Tells joystick 2 to switch on/off/blinking lamp 10.

00 - Off
01 - On
10 - Blinking
11 - Don't care / Take no action";
CM_ SG_ 2358902526 Joystick2Lamp9Cmd "Tells joystick 2 to switch on/off/blinking lamp 9.

00 - Off
01 - On
10 - Blinking
11 - Don't care / Take no action";
CM_ SG_ 2358902526 Joystick2Lamp8Cmd "Tells joystick 2 to switch on/off/blinking lamp 8.

00 - Off
01 - On
10 - Blinking
11 - Don't care / Take no action";
CM_ SG_ 2358902526 Joystick2Lamp7Cmd "Tells joystick 2 to switch on/off/blinking lamp 7.

00 - Off
01 - On
10 - Blinking
11 - Don't care / Take no action";
CM_ SG_ 2358902526 Joystick2Lamp6Cmd "Tells joystick 2 to switch on/off/blinking lamp 6.

00 - Off
01 - On
10 - Blinking
11 - Don't care / Take no action";
CM_ SG_ 2358902526 Joystick2Lamp5Cmd "Tells joystick 2 to switch on/off/blinking lamp 5.

00 - Off
01 - On
10 - Blinking
11 - Don't care / Take no action";
CM_ SG_ 2358902526 Joystick2Lamp4Cmd "Tells joystick 2 to switch on/off/blinking lamp 4.

00 - Off
01 - On
10 - Blinking
11 - Don't care / Take no action";
CM_ SG_ 2358902526 Joystick2Lamp3Cmd "Tells joystick 2 to switch on/off/blinking lamp 3.

00 - Off
01 - On
10 - Blinking
11 - Don't care / Take no action";
CM_ SG_ 2358902526 Joystick2Lamp2Cmd "Tells joystick 2 to switch on/off/blinking lamp 2.

00 - Off
01 - On
10 - Blinking
11 - Don't care / Take no action";
CM_ SG_ 2358902526 Joystick2Lamp1Cmd "Tells joystick 2 to switch on/off/blinking lamp 1.

00 - Off
01 - On
10 - Blinking
11 - Don't care / Take no action";
CM_ SG_ 2358902526 Joystick1Lamp10Cmd "Tells joystick 1 to switch on/off/blinking lamp 10.

00 - Off
01 - On
10 - Blinking
11 - Don't care / Take no action";
CM_ SG_ 2358902526 Joystick1Lamp9Cmd "Tells joystick 1 to switch on/off/blinking lamp 9.

00 - Off
01 - On
10 - Blinking
11 - Don't care / Take no action";
CM_ SG_ 2358902526 Joystick1Lamp8Cmd "Tells joystick 1 to switch on/off/blinking lamp 8.

00 - Off
01 - On
10 - Blinking
11 - Don't care / Take no action";
CM_ SG_ 2358902526 Joystick1Lamp7Cmd "Tells joystick 1 to switch on/off/blinking lamp 7.

00 - Off
01 - On
10 - Blinking
11 - Don't care / Take no action";
CM_ SG_ 2358902526 Joystick1Lamp6Cmd "Tells joystick 1 to switch on/off/blinking lamp 6.

00 - Off
01 - On
10 - Blinking
11 - Don't care / Take no action";
CM_ SG_ 2358902526 Joystick1Lamp5Cmd "Tells joystick 1 to switch on/off/blinking lamp 5.

00 - Off
01 - On
10 - Blinking
11 - Don't care / Take no action";
CM_ SG_ 2358902526 Joystick1Lamp4Cmd "Tells joystick 1 to switch on/off/blinking lamp 4.

00 - Off
01 - On
10 - Blinking
11 - Don't care / Take no action";
CM_ SG_ 2358902526 Joystick1Lamp3Cmd "Tells joystick 1 to switch on/off/blinking lamp 3.

00 - Off
01 - On
10 - Blinking
11 - Don't care / Take no action";
CM_ SG_ 2358902526 Joystick1Lamp2Cmd "Tells joystick 1 to switch on/off/blinking lamp 2.

00 - Off
01 - On
10 - Blinking
11 - Don't care / Take no action";
CM_ SG_ 2358902526 Joystick1Lamp1Cmd "Tells joystick 1 to switch on/off/blinking lamp 1.

00 - Off
01 - On
10 - Blinking
11 - Don't care / Take no action";
CM_ BO_ 2566711550 "Intake Valve Actuation Control
Contains information about the intake valve actuation system control.";
CM_ SG_ 2566711550 IntkVlvActtnSystmOlPrss2SlndCtrl "Indicates the current command to the solenoid that controls the intake valve actuation system oil pressure 2 valve. This valve opens or closes a connection from the intake valve actuation oil rail to tank.
00 off
01 on
10 reserved for SAE ...";
CM_ SG_ 2566711550 IntkVlvActtnSystmOlPrss1SlndCtrl "Indicates the current command to the solenoid that controls the intake valve actuation system oil pressure 1 valve. This valve opens or closes a connection from the intake valve actuation oil rail to tank.
00 off
01 on
10 reserved for SAE ...";
CM_ BO_ 2633832958 "Ignitor Loop Information
Message containing resistance values for every equipped ignitor loop of the restraint-system. (Maximum of 100 Ignitor Loops.)
.
.
Byte 21-22    Special Ignitor Loop [1], if installed
Byte 23-24    Special Ignitor Loop ...";
CM_ SG_ 2633832958 SpecialIgnitorLoop90Resistance "Resistance of Special Ignitor Loop 90.   Since there are many different vehicle types (e.g. truck, bus, firetruck or ambulance), the ignitor loop configuration has a wide variation.";
CM_ SG_ 2633832958 SpecialIgnitorLoop89Resistance "Resistance of Special Ignitor Loop 89.   Since there are many different vehicle types (e.g. truck, bus, firetruck or ambulance), the ignitor loop configuration has a wide variation.";
CM_ SG_ 2633832958 SpecialIgnitorLoop88Resistance "Resistance of Special Ignitor Loop 88.   Since there are many different vehicle types (e.g. truck, bus, firetruck or ambulance), the ignitor loop configuration has a wide variation.";
CM_ SG_ 2633832958 SpecialIgnitorLoop87Resistance "Resistance of Special Ignitor Loop 87.   Since there are many different vehicle types (e.g. truck, bus, firetruck or ambulance), the ignitor loop configuration has a wide variation.";
CM_ SG_ 2633832958 SpecialIgnitorLoop86Resistance "Resistance of Special Ignitor Loop 86.   Since there are many different vehicle types (e.g. truck, bus, firetruck or ambulance), the ignitor loop configuration has a wide variation.";
CM_ SG_ 2633832958 SpecialIgnitorLoop85Resistance "Resistance of Special Ignitor Loop 85.   Since there are many different vehicle types (e.g. truck, bus, firetruck or ambulance), the ignitor loop configuration has a wide variation.";
CM_ SG_ 2633832958 SpecialIgnitorLoop84Resistance "Resistance of Special Ignitor Loop 84.   Since there are many different vehicle types (e.g. truck, bus, firetruck or ambulance), the ignitor loop configuration has a wide variation.";
CM_ SG_ 2633832958 SpecialIgnitorLoop83Resistance "Resistance of Special Ignitor Loop 83.   Since there are many different vehicle types (e.g. truck, bus, firetruck or ambulance), the ignitor loop configuration has a wide variation.";
CM_ SG_ 2633832958 SpecialIgnitorLoop82Resistance "Resistance of Special Ignitor Loop 82.   Since there are many different vehicle types (e.g. truck, bus, firetruck or ambulance), the ignitor loop configuration has a wide variation.";
CM_ SG_ 2633832958 SpecialIgnitorLoop81Resistance "Resistance of Special Ignitor Loop 81.   Since there are many different vehicle types (e.g. truck, bus, firetruck or ambulance), the ignitor loop configuration has a wide variation.";
CM_ SG_ 2633832958 SpecialIgnitorLoop80Resistance "Resistance of Special Ignitor Loop 80.   Since there are many different vehicle types (e.g. truck, bus, firetruck or ambulance), the ignitor loop configuration has a wide variation.";
CM_ SG_ 2633832958 SpecialIgnitorLoop79Resistance "Resistance of Special Ignitor Loop 79.   Since there are many different vehicle types (e.g. truck, bus, firetruck or ambulance), the ignitor loop configuration has a wide variation.";
CM_ SG_ 2633832958 SpecialIgnitorLoop78Resistance "Resistance of Special Ignitor Loop 78.   Since there are many different vehicle types (e.g. truck, bus, firetruck or ambulance), the ignitor loop configuration has a wide variation.";
CM_ SG_ 2633832958 SpecialIgnitorLoop77Resistance "Resistance of Special Ignitor Loop 77.   Since there are many different vehicle types (e.g. truck, bus, firetruck or ambulance), the ignitor loop configuration has a wide variation.";
CM_ SG_ 2633832958 SpecialIgnitorLoop76Resistance "Resistance of Special Ignitor Loop 76.   Since there are many different vehicle types (e.g. truck, bus, firetruck or ambulance), the ignitor loop configuration has a wide variation.";
CM_ SG_ 2633832958 SpecialIgnitorLoop75Resistance "Resistance of Special Ignitor Loop 75.   Since there are many different vehicle types (e.g. truck, bus, firetruck or ambulance), the ignitor loop configuration has a wide variation.";
CM_ SG_ 2633832958 SpecialIgnitorLoop74Resistance "Resistance of Special Ignitor Loop 74.   Since there are many different vehicle types (e.g. truck, bus, firetruck or ambulance), the ignitor loop configuration has a wide variation.";
CM_ SG_ 2633832958 SpecialIgnitorLoop73Resistance "Resistance of Special Ignitor Loop 73.   Since there are many different vehicle types (e.g. truck, bus, firetruck or ambulance), the ignitor loop configuration has a wide variation.";
CM_ SG_ 2633832958 SpecialIgnitorLoop72Resistance "Resistance of Special Ignitor Loop 72.   Since there are many different vehicle types (e.g. truck, bus, firetruck or ambulance), the ignitor loop configuration has a wide variation.";
CM_ SG_ 2633832958 SpecialIgnitorLoop71Resistance "Resistance of Special Ignitor Loop 71.   Since there are many different vehicle types (e.g. truck, bus, firetruck or ambulance), the ignitor loop configuration has a wide variation.";
CM_ SG_ 2633832958 SpecialIgnitorLoop70Resistance "Resistance of Special Ignitor Loop 70.   Since there are many different vehicle types (e.g. truck, bus, firetruck or ambulance), the ignitor loop configuration has a wide variation.";
CM_ SG_ 2633832958 SpecialIgnitorLoop69Resistance "Resistance of Special Ignitor Loop 69.   Since there are many different vehicle types (e.g. truck, bus, firetruck or ambulance), the ignitor loop configuration has a wide variation.";
CM_ SG_ 2633832958 SpecialIgnitorLoop68Resistance "Resistance of Special Ignitor Loop 68.   Since there are many different vehicle types (e.g. truck, bus, firetruck or ambulance), the ignitor loop configuration has a wide variation.";
CM_ SG_ 2633832958 SpecialIgnitorLoop67Resistance "Resistance of Special Ignitor Loop 67.   Since there are many different vehicle types (e.g. truck, bus, firetruck or ambulance), the ignitor loop configuration has a wide variation.";
CM_ SG_ 2633832958 SpecialIgnitorLoop66Resistance "Resistance of Special Ignitor Loop 66.   Since there are many different vehicle types (e.g. truck, bus, firetruck or ambulance), the ignitor loop configuration has a wide variation.";
CM_ SG_ 2633832958 SpecialIgnitorLoop65Resistance "Resistance of Special Ignitor Loop 65.   Since there are many different vehicle types (e.g. truck, bus, firetruck or ambulance), the ignitor loop configuration has a wide variation.";
CM_ SG_ 2633832958 SpecialIgnitorLoop64Resistance "Resistance of Special Ignitor Loop 64.   Since there are many different vehicle types (e.g. truck, bus, firetruck or ambulance), the ignitor loop configuration has a wide variation.";
CM_ SG_ 2633832958 SpecialIgnitorLoop63Resistance "Resistance of Special Ignitor Loop 63.   Since there are many different vehicle types (e.g. truck, bus, firetruck or ambulance), the ignitor loop configuration has a wide variation.";
CM_ SG_ 2633832958 SpecialIgnitorLoop62Resistance "Resistance of Special Ignitor Loop 62.   Since there are many different vehicle types (e.g. truck, bus, firetruck or ambulance), the ignitor loop configuration has a wide variation.";
CM_ SG_ 2633832958 SpecialIgnitorLoop61Resistance "Resistance of Special Ignitor Loop 61.   Since there are many different vehicle types (e.g. truck, bus, firetruck or ambulance), the ignitor loop configuration has a wide variation.";
CM_ SG_ 2633832958 SpecialIgnitorLoop60Resistance "Resistance of Special Ignitor Loop 60.   Since there are many different vehicle types (e.g. truck, bus, firetruck or ambulance), the ignitor loop configuration has a wide variation.";
CM_ SG_ 2633832958 SpecialIgnitorLoop59Resistance "Resistance of Special Ignitor Loop 59.   Since there are many different vehicle types (e.g. truck, bus, firetruck or ambulance), the ignitor loop configuration has a wide variation.";
CM_ SG_ 2633832958 SpecialIgnitorLoop58Resistance "Resistance of Special Ignitor Loop 58.   Since there are many different vehicle types (e.g. truck, bus, firetruck or ambulance), the ignitor loop configuration has a wide variation.";
CM_ SG_ 2633832958 SpecialIgnitorLoop57Resistance "Resistance of Special Ignitor Loop 57.   Since there are many different vehicle types (e.g. truck, bus, firetruck or ambulance), the ignitor loop configuration has a wide variation.";
CM_ SG_ 2633832958 SpecialIgnitorLoop56Resistance "Resistance of Special Ignitor Loop 56.   Since there are many different vehicle types (e.g. truck, bus, firetruck or ambulance), the ignitor loop configuration has a wide variation.";
CM_ SG_ 2633832958 SpecialIgnitorLoop55Resistance "Resistance of Special Ignitor Loop 55.   Since there are many different vehicle types (e.g. truck, bus, firetruck or ambulance), the ignitor loop configuration has a wide variation.";
CM_ SG_ 2633832958 SpecialIgnitorLoop54Resistance "Resistance of Special Ignitor Loop 54.   Since there are many different vehicle types (e.g. truck, bus, firetruck or ambulance), the ignitor loop configuration has a wide variation.";
CM_ SG_ 2633832958 SpecialIgnitorLoop53Resistance "Resistance of Special Ignitor Loop 53.   Since there are many different vehicle types (e.g. truck, bus, firetruck or ambulance), the ignitor loop configuration has a wide variation.";
CM_ SG_ 2633832958 SpecialIgnitorLoop52Resistance "Resistance of Special Ignitor Loop 52.   Since there are many different vehicle types (e.g. truck, bus, firetruck or ambulance), the ignitor loop configuration has a wide variation.";
CM_ SG_ 2633832958 SpecialIgnitorLoop51Resistance "Resistance of Special Ignitor Loop 51.   Since there are many different vehicle types (e.g. truck, bus, firetruck or ambulance), the ignitor loop configuration has a wide variation.";
CM_ SG_ 2633832958 SpecialIgnitorLoop50Resistance "Resistance of Special Ignitor Loop 50.   Since there are many different vehicle types (e.g. truck, bus, firetruck or ambulance), the ignitor loop configuration has a wide variation.";
CM_ SG_ 2633832958 SpecialIgnitorLoop49Resistance "Resistance of Special Ignitor Loop 49.   Since there are many different vehicle types (e.g. truck, bus, firetruck or ambulance), the ignitor loop configuration has a wide variation.";
CM_ SG_ 2633832958 SpecialIgnitorLoop48Resistance "Resistance of Special Ignitor Loop 48.   Since there are many different vehicle types (e.g. truck, bus, firetruck or ambulance), the ignitor loop configuration has a wide variation.";
CM_ SG_ 2633832958 SpecialIgnitorLoop47Resistance "Resistance of Special Ignitor Loop 47.   Since there are many different vehicle types (e.g. truck, bus, firetruck or ambulance), the ignitor loop configuration has a wide variation.";
CM_ SG_ 2633832958 SpecialIgnitorLoop46Resistance "Resistance of Special Ignitor Loop 46.   Since there are many different vehicle types (e.g. truck, bus, firetruck or ambulance), the ignitor loop configuration has a wide variation.";
CM_ SG_ 2633832958 SpecialIgnitorLoop45Resistance "Resistance of Special Ignitor Loop 45.   Since there are many different vehicle types (e.g. truck, bus, firetruck or ambulance), the ignitor loop configuration has a wide variation.";
CM_ SG_ 2633832958 SpecialIgnitorLoop44Resistance "Resistance of Special Ignitor Loop 44.   Since there are many different vehicle types (e.g. truck, bus, firetruck or ambulance), the ignitor loop configuration has a wide variation.";
CM_ SG_ 2633832958 SpecialIgnitorLoop43Resistance "Resistance of Special Ignitor Loop 43.   Since there are many different vehicle types (e.g. truck, bus, firetruck or ambulance), the ignitor loop configuration has a wide variation.";
CM_ SG_ 2633832958 SpecialIgnitorLoop42Resistance "Resistance of Special Ignitor Loop 42.   Since there are many different vehicle types (e.g. truck, bus, firetruck or ambulance), the ignitor loop configuration has a wide variation.";
CM_ SG_ 2633832958 SpecialIgnitorLoop41Resistance "Resistance of Special Ignitor Loop 41.   Since there are many different vehicle types (e.g. truck, bus, firetruck or ambulance), the ignitor loop configuration has a wide variation.";
CM_ SG_ 2633832958 SpecialIgnitorLoop40Resistance "Resistance of Special Ignitor Loop 40.   Since there are many different vehicle types (e.g. truck, bus, firetruck or ambulance), the ignitor loop configuration has a wide variation.";
CM_ SG_ 2633832958 SpecialIgnitorLoop39Resistance "Resistance of Special Ignitor Loop 39.   Since there are many different vehicle types (e.g. truck, bus, firetruck or ambulance), the ignitor loop configuration has a wide variation.";
CM_ SG_ 2633832958 SpecialIgnitorLoop38Resistance "Resistance of Special Ignitor Loop 38.   Since there are many different vehicle types (e.g. truck, bus, firetruck or ambulance), the ignitor loop configuration has a wide variation.";
CM_ SG_ 2633832958 SpecialIgnitorLoop37Resistance "Resistance of Special Ignitor Loop 37.   Since there are many different vehicle types (e.g. truck, bus, firetruck or ambulance), the ignitor loop configuration has a wide variation.";
CM_ SG_ 2633832958 SpecialIgnitorLoop36Resistance "Resistance of Special Ignitor Loop 36.   Since there are many different vehicle types (e.g. truck, bus, firetruck or ambulance), the ignitor loop configuration has a wide variation.";
CM_ SG_ 2633832958 SpecialIgnitorLoop35Resistance "Resistance of Special Ignitor Loop 35.   Since there are many different vehicle types (e.g. truck, bus, firetruck or ambulance), the ignitor loop configuration has a wide variation.";
CM_ SG_ 2633832958 SpecialIgnitorLoop34Resistance "Resistance of Special Ignitor Loop 34.   Since there are many different vehicle types (e.g. truck, bus, firetruck or ambulance), the ignitor loop configuration has a wide variation.";
CM_ SG_ 2633832958 SpecialIgnitorLoop33Resistance "Resistance of Special Ignitor Loop 33.   Since there are many different vehicle types (e.g. truck, bus, firetruck or ambulance), the ignitor loop configuration has a wide variation.";
CM_ SG_ 2633832958 SpecialIgnitorLoop32Resistance "Resistance of Special Ignitor Loop 32.   Since there are many different vehicle types (e.g. truck, bus, firetruck or ambulance), the ignitor loop configuration has a wide variation.";
CM_ SG_ 2633832958 SpecialIgnitorLoop31Resistance "Resistance of Special Ignitor Loop 31.   Since there are many different vehicle types (e.g. truck, bus, firetruck or ambulance), the ignitor loop configuration has a wide variation.";
CM_ SG_ 2633832958 SpecialIgnitorLoop30Resistance "Resistance of Special Ignitor Loop 30.   Since there are many different vehicle types (e.g. truck, bus, firetruck or ambulance), the ignitor loop configuration has a wide variation.";
CM_ SG_ 2633832958 SpecialIgnitorLoop29Resistance "Resistance of Special Ignitor Loop 29.   Since there are many different vehicle types (e.g. truck, bus, firetruck or ambulance), the ignitor loop configuration has a wide variation.";
CM_ SG_ 2633832958 SpecialIgnitorLoop28Resistance "Resistance of Special Ignitor Loop 28.   Since there are many different vehicle types (e.g. truck, bus, firetruck or ambulance), the ignitor loop configuration has a wide variation.";
CM_ SG_ 2633832958 SpecialIgnitorLoop27Resistance "Resistance of Special Ignitor Loop 27.   Since there are many different vehicle types (e.g. truck, bus, firetruck or ambulance), the ignitor loop configuration has a wide variation.";
CM_ SG_ 2633832958 SpecialIgnitorLoop26Resistance "Resistance of Special Ignitor Loop 26.   Since there are many different vehicle types (e.g. truck, bus, firetruck or ambulance), the ignitor loop configuration has a wide variation.";
CM_ SG_ 2633832958 SpecialIgnitorLoop25Resistance "Resistance of Special Ignitor Loop 25.   Since there are many different vehicle types (e.g. truck, bus, firetruck or ambulance), the ignitor loop configuration has a wide variation.";
CM_ SG_ 2633832958 SpecialIgnitorLoop24Resistance "Resistance of Special Ignitor Loop 24.   Since there are many different vehicle types (e.g. truck, bus, firetruck or ambulance), the ignitor loop configuration has a wide variation.";
CM_ SG_ 2633832958 SpecialIgnitorLoop23Resistance "Resistance of Special Ignitor Loop 23.   Since there are many different vehicle types (e.g. truck, bus, firetruck or ambulance), the ignitor loop configuration has a wide variation.";
CM_ SG_ 2633832958 SpecialIgnitorLoop22Resistance "Resistance of Special Ignitor Loop 22.   Since there are many different vehicle types (e.g. truck, bus, firetruck or ambulance), the ignitor loop configuration has a wide variation.";
CM_ SG_ 2633832958 SpecialIgnitorLoop21Resistance "Resistance of Special Ignitor Loop 21.   Since there are many different vehicle types (e.g. truck, bus, firetruck or ambulance), the ignitor loop configuration has a wide variation.";
CM_ SG_ 2633832958 SpecialIgnitorLoop20Resistance "Resistance of Special Ignitor Loop 20.   Since there are many different vehicle types (e.g. truck, bus, firetruck or ambulance), the ignitor loop configuration has a wide variation.";
CM_ SG_ 2633832958 SpecialIgnitorLoop19Resistance "Resistance of Special Ignitor Loop 19.   Since there are many different vehicle types (e.g. truck, bus, firetruck or ambulance), the ignitor loop configuration has a wide variation.";
CM_ SG_ 2633832958 SpecialIgnitorLoop18Resistance "Resistance of Special Ignitor Loop 18.   Since there are many different vehicle types (e.g. truck, bus, firetruck or ambulance), the ignitor loop configuration has a wide variation.";
CM_ SG_ 2633832958 SpecialIgnitorLoop17Resistance "Resistance of Special Ignitor Loop 17.   Since there are many different vehicle types (e.g. truck, bus, firetruck or ambulance), the ignitor loop configuration has a wide variation.";
CM_ SG_ 2633832958 SpecialIgnitorLoop16Resistance "Resistance of Special Ignitor Loop 16.   Since there are many different vehicle types (e.g. truck, bus, firetruck or ambulance), the ignitor loop configuration has a wide variation.";
CM_ SG_ 2633832958 SpecialIgnitorLoop15Resistance "Resistance of Special Ignitor Loop 15.   Since there are many different vehicle types (e.g. truck, bus, firetruck or ambulance), the ignitor loop configuration has a wide variation.";
CM_ SG_ 2633832958 SpecialIgnitorLoop14Resistance "Resistance of Special Ignitor Loop 14.   Since there are many different vehicle types (e.g. truck, bus, firetruck or ambulance), the ignitor loop configuration has a wide variation.";
CM_ SG_ 2633832958 SpecialIgnitorLoop13Resistance "Resistance of Special Ignitor Loop 13.   Since there are many different vehicle types (e.g. truck, bus, firetruck or ambulance), the ignitor loop configuration has a wide variation.";
CM_ SG_ 2633832958 SpecialIgnitorLoop12Resistance "Resistance of Special Ignitor Loop 12.   Since there are many different vehicle types (e.g. truck, bus, firetruck or ambulance), the ignitor loop configuration has a wide variation.";
CM_ SG_ 2633832958 SpecialIgnitorLoop11Resistance "Resistance of Special Ignitor Loop 11.   Since there are many different vehicle types (e.g. truck, bus, firetruck or ambulance), the ignitor loop configuration has a wide variation.";
CM_ SG_ 2633832958 SpecialIgnitorLoop10Resistance "Resistance of Special Ignitor Loop 10.   Since there are many different vehicle types (e.g. truck, bus, firetruck or ambulance), the ignitor loop configuration has a wide variation.";
CM_ SG_ 2633832958 SpecialIgnitorLoop9Resistance "Resistance of Special Ignitor Loop 9.   Since there are many different vehicle types (e.g. truck, bus, firetruck or ambulance), the ignitor loop configuration has a wide variation.";
CM_ SG_ 2633832958 SpecialIgnitorLoop8Resistance "Resistance of Special Ignitor Loop 8.   Since there are many different vehicle types (e.g. truck, bus, firetruck or ambulance), the ignitor loop configuration has a wide variation.";
CM_ SG_ 2633832958 SpecialIgnitorLoop7Resistance "Resistance of Special Ignitor Loop 7.   Since there are many different vehicle types (e.g. truck, bus, firetruck or ambulance), the ignitor loop configuration has a wide variation.";
CM_ SG_ 2633832958 SpecialIgnitorLoop6Resistance "Resistance of Special Ignitor Loop 6.   Since there are many different vehicle types (e.g. truck, bus, firetruck or ambulance), the ignitor loop configuration has a wide variation.";
CM_ SG_ 2633832958 SpecialIgnitorLoop5Resistance "Resistance of Special Ignitor Loop 5.   Since there are many different vehicle types (e.g. truck, bus, firetruck or ambulance), the ignitor loop configuration has a wide variation.";
CM_ SG_ 2633832958 SpecialIgnitorLoop4Resistance "Resistance of Special Ignitor Loop 4.   Since there are many different vehicle types (e.g. truck, bus, firetruck or ambulance), the ignitor loop configuration has a wide variation.";
CM_ SG_ 2633832958 SpecialIgnitorLoop3Resistance "Resistance of Special Ignitor Loop 3.   Since there are many different vehicle types (e.g. truck, bus, firetruck or ambulance), the ignitor loop configuration has a wide variation.";
CM_ SG_ 2633832958 SpecialIgnitorLoop2Resistance "Resistance of Special Ignitor Loop 2.   Since there are many different vehicle types (e.g. truck, bus, firetruck or ambulance), the ignitor loop configuration has a wide variation.";
CM_ SG_ 2633832958 SpecialIgnitorLoop1Resistance "Resistance of Special Ignitor Loop 1.   Since there are many different vehicle types (e.g. truck, bus, firetruck or ambulance), the ignitor loop configuration has a wide variation.";
CM_ SG_ 2633832958 SdBagIgnitorLoop2RightResistance "Resistance of Side Bag Ignitor Loop 2 - Right.";
CM_ SG_ 2633832958 SdBagIgnitorLoop1RightResistance "Resistance of Side Bag Ignitor Loop 1 - Right.";
CM_ SG_ 2633832958 SdeBagIgnitorLoop2LeftResistance "Resistance of Side Bag Ignitor Loop 2 - Left.";
CM_ SG_ 2633832958 SdeBagIgnitorLoop1LeftResistance "Resistance of Side Bag Ignitor Loop 1 - Left.";
CM_ SG_ 2633832958 PssngrBltTnsnrIgntrLopResistance "Resistance of Passenger Belt Tensioner Ignitor Loop 1st Stage.";
CM_ SG_ 2633832958 DrvrBltTnsnrIgntorLoopResistance "Resistance of Driver Belt Tensioner Ignitor Loop 1st Stage.";
CM_ SG_ 2633832958 PssngrArbgIgntrLp2ndStgRsistance "Resistance of Passenger Airbag Ignitor Loop 2nd Stage.";
CM_ SG_ 2633832958 DrvrArbgIgntrLp2ndStgeResistance "Resistance of Driver Airbag Ignitor Loop 2nd Stage.";
CM_ SG_ 2633832958 PssngrArbgIgntrLp1stStgRsistance "Resistance of Passenger Airbag Ignitor Loop 1st Stage.";
CM_ SG_ 2633832958 DrvrArbgIgntrLp1stStgeResistance "Resistance of Driver Airbag Ignitor Loop 1st Stage.";
CM_ BO_ 2566719998 "High Resolution Fuel Consumption (Liquid)
Engine fuel consumption accumulators.  See PGN 65257 for alternate resolution.";
CM_ SG_ 2566719998 HighResolutionEngTotalFuelUsed "Accumulated amount of fuel used during vehicle operation.  High resolution used for calculations and fleet management systems.  See SPN 250 for alternate resolution.";
CM_ SG_ 2566719998 HighResolutionEngTripFuel "Fuel consumed during all or part of a journey.   High resolution used for calculations and fleet management systems.  See SPN 182 for alternate resolution.";
CM_ BO_ 2565877502 "Engine Turbocharger Control
This PGN contains the Engine Turbocharger Wastegate Actuator 1 & 2 control, Exhaust Back Pressure Regulator and Blowoff Actuator commands.";
CM_ SG_ 2565877502 EngTrbCmprssrBlowoffActuator1Cmd "The command to blow off actuator 1, normalized to percent, where 0% nominally represents fully closed (No Flow) and 100% represents fully open (Max Flow). The purpose of Blow-off value is similar to that of Compressor bypass valve, however the ...";
CM_ SG_ 2565877502 EngExhstBckPressRegulatorCtrlCmd "The control command to the Engine Exhaust Pressure Regulator in bank 1, normalized to percent.  100 percent means the regulator is fully closed, providing the maximum restriction to exhaust gas flow from the engine.  Zero percent means the regulator ...";
CM_ SG_ 2565877502 EngTurboWastegateActuator2Cmd "The command to a Turbocharger Wastegate actuator 2, normalized to percent, where 0% nominally represents fully closed (No Flow) and 100% represents fully open (Max Flow).";
CM_ SG_ 2565877502 EngTurboWastegateActuator1Cmd "The command to a Turbocharger Wastegate actuator 1, normalized to percent, where 0% nominally represents fully closed (No Flow) and 100% represents fully open (Max Flow).
0xFB00 - 0xFB64 is sent to calibrate to a specific position.  The LSB ...";
CM_ BO_ 2566713854 "Engine Turbocharger Wastegate Actuator and Exhaust Back Pressure Regulator Information
This PGN will be used to transmit  the Engine Turbocharger Wastegate and Exhaust Back Pressure Regulator Information.";
CM_ SG_ 2566713854 EngExhaustBackPressActuator1Temp "Temperature of the Engine Exhaust Pressure Actuator 1 drive circuitry.  Temperature excursions may affect the torque output.";
CM_ SG_ 2566713854 EngExhstBckPrssActtor1DesiredPos "The requested position of the Engine Exhaust Pressure Actuator 1 by the engine ECU, where 0% represents fully closed and 100% represents fully open.

This is the position that the device is attempting to achieve.";
CM_ SG_ 2566713854 EngTurboWastegateActuator1Temp "Temperature of the Engine Turbocharger Wastegate Actuator 1 drive circuitry.  Temperature excursions may affect the torque output.";
CM_ SG_ 2566713854 EngExhstBckPrssRgltrCtrlOprtnStt "Used to identify the status of Engine Exhaust Pressure Regulator.
0000 - Normal
0001 - Alarm (fully operational but needs service)
0010 - Alarm High Severity (functional but transient performance may be reduced)
0011 - Derate Active (torque ...";
CM_ SG_ 2566713854 EngExhstBckPrssRglatorTempStatus "Used to identify the status of the Engine Exhaust Pressure Regulator (EPR) drive circuitry temperature. Temperature excursions may affect the torque output.
000 - High most severe
001 - High Least severe
010 - In Range
011 - Low Least severe
 ...";
CM_ SG_ 2566713854 EngExhstBckPrssRgltrPrlminaryFMI "Used to identify the applicable J1939-73 FMI detected in the Engine Exhaust Pressure Regulator (EPR) by the manufacturers software.  When there are multiple failures, the most severe is transmitted.
A value of 31 is sent to indicate that no failure ...";
CM_ SG_ 2566713854 EngExhaustBackPressRegulatorPos "The position of the Exhaust Pressure Regulator (EPR) in bank 1 expressed as a percentage of full travel.  One hundred percent means the regulator is fully closed, providing the maximum restriction to exhaust gas flow from the engine.  Zero percent ...";
CM_ SG_ 2566713854 EngTrbWstgtActtr2OperationStatus "Used to identify the status of Engine Turbocharger Wastegate Actuator 2.
0000 - Normal
0001 - Alarm (fully operational but needs service)
0010 - Alarm High Severity (functional but transient performance may be reduced)
0011 - Derate Active ...";
CM_ SG_ 2566713854 EngTrbWstgtActtr1OperationStatus "Used to identify the status of Engine Turbocharger Wastegate Actuator 1.
0000 - Normal
0001 - Alarm (fully operational but needs service)
0010 - Alarm High Severity (functional but transient performance may be reduced)
0011 - Derate Active ...";
CM_ SG_ 2566713854 EngTrbWstgateActuator2TempStatus "Used to identify the status of the Engine Turbocharger Wastegate Actuator 2 drive circuitry temperature.  Temperature excursions may affect the torque output.
000 - High most severe
001 - High Least severe
010 - In Range
011 - Low Least severe
 ...";
CM_ SG_ 2566713854 EngTrbWstgtActtor2PreliminaryFMI "Used to identify the applicable J1939-73 FMI detected in the Engine Turbocharger Wastegate Actuator 2 by the manufacturers software. When there is multiple failures, the most severe is transmitted.
A value of 31 is sent to indicate that no failure ...";
CM_ BO_ 2566714366 "Engine Turbocharger Compressor Bypass Information
This PGN will contain the Engine Turbocharger Compressor Bypass information";
CM_ SG_ 2566714366 EngTrbCmprssrBypassActuator2Temp "Temperature of the Engine Turbocharger Compressor Bypass Actuator 2 drive circuitry.    Temperature excursions may affect the torque output.";
CM_ SG_ 2566714366 EngTrbCmprssrBypassActuator1Temp "Temperature of the Engine Turbocharger Compressor Bypass Actuator 1 drive circuitry.    Temperature excursions may affect the torque output.";
CM_ SG_ 2566714366 EngTrbCmprssrBypssActtr2OprtnStt "Used to identify the status of Engine Turbocharger Compressor Bypass Actuator 2.
0000 - Normal
0001 - Alarm (fully operational but needs service)
0010 - Alarm High Severity (functional but transient performance may be reduced)
0011 - Derate ...";
CM_ SG_ 2566714366 EngTrbCmprssrBypssActtr1OprtnStt "Used to identify the status of Engine Turbocharger Compressor Bypass Actuator 1.
0000 - Normal
0001 - Alarm (fully operational but needs service)
0010 - Alarm High Severity (functional but transient performance may be reduced)
0011 - Derate ...";
CM_ SG_ 2566714366 EngTrbCmprssrBypssActtr2TmpSttus "Used to identify the status of the Engine Turbocharger Compresssor Bypass Actuator 2 drive circuitry temperature.  Temperature excursions may affect the torque output.
000 - High most severe
001 - High Least severe
010 - In Range
011 - Low Least ...";
CM_ SG_ 2566714366 EngTrbCmprssrBypssActtr2PrlmnryF "Used to identify the applicable J1939-73 FMI detected in the Engine Turbocharger Compressor Bypass Actuator 1 by the manufacturers software.  When there is multiple failures, the most severe is transmitted.
A value of 31 is sent to indicate that no ...";
CM_ SG_ 2566714366 EngDsrdTrbCmprssrBypssActtor2Pos "The desired position of the Engine Turbocharger Compressor Bypass actuator 2 by the engine ECU, where 0% represents bypass fully closed and 100% represents bypass fully open.

This is the position that the device is attempting to achieve.";
CM_ SG_ 2566714366 EngTrbCmprssorBypassActuator2Pos "Measures the position of the turbocharger compressor bypass actuator 2, where 0% represents bypass fully closed and 100% represents bypass fully open. Typically, the compressor bypass is used to lower the compressor outlet pressure and/or intake ...";
CM_ BO_ 2566714110 "Engine Fuel/Throttle Valve Information 1
This PGN will be used to transmit the Feedback information from the Engine Throttle and Fuel Actuator.";
CM_ SG_ 2566714110 EngFuelValve2OperationStatus "Used to identify the status of Engine Fuel Valve 2.
0000 - Normal
0001 - Alarm (fully operational but needs service)
0010 - Alarm High Severity (functional but transient performance may be reduced)
0011 - Derate Active (torque output reduced due ...";
CM_ SG_ 2566714110 EngFuelValve1OperationStatus "Used to identify the status of Engine Fuel Valve 1.
0000 - Normal
0001 - Alarm (fully operational but needs service)
0010 - Alarm High Severity (functional but transient performance may be reduced)
0011 - Derate Active (torque output reduced due ...";
CM_ SG_ 2566714110 EngThrottleValve2OperationStatus "Used to identify the status of engine throttle valve 2 (SPN 3673).
0000 - Normal
0001 - Alarm (fully operational but needs service)
0010 - Alarm High Severity (functional but transient performance may be reduced)
0011 - Derate Active (torque ...";
CM_ SG_ 2566714110 EngThrottleValve1OperationStatus "Used to identify the status of engine throttle valve 1 (SPN 51).
0000 - Normal
0001 - Alarm (fully operational but needs service)
0010 - Alarm High Severity (functional but transient performance may be reduced)
0011 - Derate Active (torque ...";
CM_ SG_ 2566714110 EngFuelValve2TempStatus "Used to identify the status of the Engine Fuel valve 2 drive circuitry temperature.  Temperature excursions may affect the torque output.
000 - High most severe
001 - High Least severe
010 - In Range
011 - Low Least severe
100 - Low Most severe
 ...";
CM_ SG_ 2566714110 EngFuelValve2PreliminaryFMI "Used to identify the applicable J1939-73 FMI detected in the Engine Fuel Valve 2 by the manufacturers software.  When there is multiple failures, the most severe is transmitted.
A value of 31 is sent to indicate that no failure has been detected or ...";
CM_ SG_ 2566714110 EngFuelValve1TempStatus "Used to identify the status of the Engine Fuel valve 1 drive circuitry temperature.  Temperature excursions may affect the torque output.
000 - High Most severe
001 - High Least severe
010 - In Range
011 - Low Least severe
100 - Low Most severe
 ...";
CM_ SG_ 2566714110 EngFuelValve1PreliminaryFMI "Used to identify the applicable J1939-73 FMI detected in the Engine Fuel Valve 1 by the manufacturers software. When there is multiple failures, the most severe is transmitted.
A value of 31 is sent to indicate that no failure has been detected or ...";
CM_ SG_ 2566714110 EngThrottleValve2TempStatus "Used to identify the status of the Engine throttle valve 2 (SPN 3673) drive circuitry temperature.  Temperature excursions may affect the torque output.
000 - High Most severe
001 - High Least severe
010 - In Range
011 - Low Least severe
100 - ...";
CM_ SG_ 2566714110 EngThrottleValve2PreliminaryFMI "Used to identify the applicable J1939-73 FMI detected in the engine throttle valve 2 (SPN 3673) by the manufacturers software.  When there is multiple failures, the most severe is transmitted.
A value of 31 is sent to indicate that no failure has ...";
CM_ SG_ 2566714110 EngDesiredThrottleValve2Pos "The desired position of the engine throttle valve 2 (SPN 3673) that is regulating the fluid, usually air/fuel mixture to the engine as commanded by the Engine Control Unit.  0% represents no supply and 100% is full supply.
This is the position that ...";
CM_ SG_ 2566714110 EngThrottleValve1TempStatus "Used to identify the status of the engine throttle valve 1 (SPN 51) drive circuitry temperature.  Temperature excursions may affect the torque output.
000 - High most severe
001 - High Least severe
010 - In Range
011 - Low Least severe
100 - ...";
CM_ SG_ 2566714110 EngThrottleValve1PreliminaryFMI "Used to identify the applicable J1939-73 FMI detected in the engine throttle valve 1 (SPN 51) by the manufacturers software.  When there is multiple failures, the most severe is transmitted.
A value of 31 is sent to indicate that no failure has ...";
CM_ SG_ 2566714110 EngDesiredThrottleValve1Pos "The desired position of the Throttle valve 1 (SPN 51) that is regulating the fluid, usually air/fuel mixture to the engine as commanded by the Engine Control unit.  0% represents no supply and 100% is full supply.
This is the position that the ...";
CM_ BO_ 2566717438 "Engine Temperature 5
Engine related parameters";
CM_ SG_ 2566717438 EngExhstGsRcrcltn2MxerIntakeTemp "The temperature of the EGR gas entering the intake of EGR2 system mixer.";
CM_ SG_ 2566717438 EngExhaustGasRecirculation2Temp "Temperature of Recirculated Exhaust Gas of EGR2";
CM_ BO_ 2633828606 "Engine oil message
Engine oil related parameters";
CM_ SG_ 2633828606 EngOilTemp3 "Temperature of the engine lubricant.

Note:  If there is only one engine oil temperature measurement, SPN 175 should be used. 

See also SPNs 175 and 1135 for additional engine oil temperature measurements.";
CM_ SG_ 2633828606 EngOilRelativeDielectricity "Engine oil relative dielectricity used to describe the engine oil quality.";
CM_ SG_ 2633828606 EngOilDensity "Density of the engine oil";
CM_ SG_ 2633828606 EngOilViscosity "Dynamic viscosity of the engine oil";
CM_ BO_ 2499607550 "Engine Manifold Actuator Position
Engine manifold actuator position parameters";
CM_ SG_ 2499607550 EngExhstMnfldBnk2FlwBlncVlvActtr "Actual percentage of maximum Engine Manifold Bank 2 Balance valve opening. 0% means valve is closed. 100% means maximum valve opening (full gas flow).";
CM_ SG_ 2499607550 EngExhstMnfldBnk1FlwBlncVlvActtr "Actual percentage of maximum Engine Exhaust Manifold Bank 1 Balance valve opening. 0% means valve is closed. 100% means maximum valve opening (full gas flow).";
CM_ BO_ 2633825534 "Engine Manifold Actuator Control
Engine manifold actuator control parameters.";
CM_ SG_ 2633825534 EngExhstMnfldBnk2FlwBlncVlvActtr "Commanded percentage of maximum Engine Ehaust Manifold Bank 2 Balance valve opening. 0% means valve is closed. 100% means maximum valve opening (full gas flow).";
CM_ SG_ 2633825534 EngExhstMnfldBnk1FlwBlncVlvActtr "Commanded percentage of maximum Engine Exhaust Manifold Bank 1 Balance valve opening. 0% means valve is closed. 100% means maximum valve opening (full gas flow).";
CM_ BO_ 2365400574 "Extended Joystick Message 9
Used to transfer information about the measured status of three additional axes of a joystick and switches of the joystick grip or handle.  The joystick axial motion information is available in the Basic Joystick ...";
CM_ SG_ 2365400574 Joystick9Button13PressedStatus "Reports when the joystick button has been pressed.

00 Button not pressed
01 Button pressed
10 Error Indicator
11 Not Available";
CM_ SG_ 2365400574 Joystick9Button14PressedStatus "Reports when the joystick button has been pressed.

00 Button not pressed
01 Button pressed
10 Error Indicator
11 Not Available";
CM_ SG_ 2365400574 Joystick9Button15PressedStatus "Reports when the joystick button has been pressed.

00 Button not pressed
01 Button pressed
10 Error Indicator
11 Not Available";
CM_ SG_ 2365400574 Joystick9Button16PressedStatus "Reports when the joystick button has been pressed.

00 Button not pressed
01 Button pressed
10 Error Indicator
11 Not Available";
CM_ SG_ 2365400574 Jystick9GripXAxisDetentPosStatus "Reports when the current joystick grip position is in the detent position for that axis of travel.

00 Not in the Detent Position
01 In the Detent Position
10 Error Indicator
11 Not Available";
CM_ SG_ 2365400574 Jystick9GripYAxisDetentPosStatus "Reports when the current joystick grip position is in the detent position for that axis of travel.

00 Not in the Detent Position
01 In the Detent Position
10 Error Indicator
11 Not Available";
CM_ SG_ 2365400574 Jystick9ThetaAxisDetentPosStatus "Reports when the current joystick position is in the detent position for that axis of travel.

00 Not in the Detent Position
01 In the Detent Position
10 Error Indicator
11 Not Available";
CM_ SG_ 2365400574 Joystick9ThetaAxisPos "The position of the joystick in the relative motion of travel from the neutral position.  Position value of 0 is Neutral and position value 1000 (100%) is the end of linear zone.  Value of 1022 indicates an error has occurred.";
CM_ SG_ 2365400574 Jystck9ThtAxsClckwsPstvPosStatus "Reports when the current joystick position is on the positive travel side (forward, right, clockwise, up) relative to the neutral position for that axis of travel.
00 Not on Positive side of Neutral
01 On positive side of Neutral
10 Error ...";
CM_ SG_ 2365400574 Jystck9ThtAxsCntrClckwsNgtvPsStt "Reports when the current joystick position is on the negative travel side (back, left, counterclockwise, down) relative to the neutral position for that axis of travel.
00 Not on negative side of Neutral
01 On negative side of Neutral
10 Error ...";
CM_ SG_ 2365400574 Jystck9ThetaAxisNeutralPosStatus "Reports when the current joystick position is in the neutral position for that axis of travel.  The neutral position measurement must be determined from some mechanism other than the axis position measurement device.
00 Not in Neutral Position
01 ...";
CM_ SG_ 2365400574 Joystick9GripYAxisPos "The position of the joystick grip in the relative motion of travel from the neutral position.  Position value of 0 is Neutral and position value 1000 (100%) is the end of linear zone.  Value of 1022 indicates an error has occurred.";
CM_ SG_ 2365400574 Jystck9GrpYAxsLvrFrwrdPstvPsStts "Reports when the current joystick grip position is on the positive travel side (forward, right, clockwise, up) relative to the neutral position for that axis of travel.
00 Not on Positive side of Neutral
01 On positive side of Neutral
10 Error ...";
CM_ SG_ 2365400574 Jystck9GrpYAxsLvrBckNgtvPsStatus "Reports when the current joystick grip position is on the negative travel side (back, left, counterclockwise, down) relative to the neutral position for that axis of travel.
00 Not on negative side of Neutral
01 On negative side of Neutral
10 ...";
CM_ SG_ 2365400574 Jystck9GripYAxisNeutralPosStatus "Reports when the current joystick grip position is in the neutral position for that axis of travel.  The neutral position measurement must be determined from some mechanism other than the axis position measurement device.
00 Not in Neutral Position
 ...";
CM_ SG_ 2365400574 Joystick9GripXAxisPos "The position of the joystick grip in the relative motion of travel from the neutral position.  Position value of 0 is Neutral and position value 1000 (100%) is the end of linear zone.  Value of 1022 indicates an error has occurred.";
CM_ SG_ 2365400574 Jystck9GrpXAxsLvrRghtPstvPsSttus "Reports when the current joystick grip position is on the positive travel side (forward, right, clockwise, up) relative to the neutral position for that axis of travel.
00 Not on Positive side of Neutral
01 On positive side of Neutral
10 Error ...";
CM_ SG_ 2365400574 Jystck9GrpXAxsLvrLftNgtvPsStatus "Reports when the current joystick grip position is on the negative travel side (back, left, counterclockwise, down) relative to the neutral position for that axis of travel.
00 Not on negative side of Neutral
01 On negative side of Neutral
10 ...";
CM_ SG_ 2365400574 Jystck9GripXAxisNeutralPosStatus "Reports when the current joystick grip position is in the neutral position for that axis of travel.  The neutral position measurement must be determined from some mechanism other than the axis position measurement device.
00 Not in Neutral Position
 ...";
CM_ BO_ 2365401086 "Extended Joystick Message 8
Used to transfer information about the measured status of three additional axes of a joystick and switches of the joystick grip or handle.  The joystick axial motion information is available in the Basic Joystick ...";
CM_ SG_ 2365401086 Joystick8Button13PressedStatus "Reports when the joystick button has been pressed.

00 Button not pressed
01 Button pressed
10 Error Indicator
11 Not Available";
CM_ SG_ 2365401086 Joystick8Button14PressedStatus "Reports when the joystick button has been pressed.

00 Button not pressed
01 Button pressed
10 Error Indicator
11 Not Available";
CM_ SG_ 2365401086 Joystick8Button15PressedStatus "Reports when the joystick button has been pressed.

00 Button not pressed
01 Button pressed
10 Error Indicator
11 Not Available";
CM_ SG_ 2365401086 Joystick8Button16PressedStatus "Reports when the joystick button has been pressed.

00 Button not pressed
01 Button pressed
10 Error Indicator
11 Not Available";
CM_ SG_ 2365401086 Jystick8GripXAxisDetentPosStatus "Reports when the current joystick grip position is in the detent position for that axis of travel.

00 Not in the Detent Position
01 In the Detent Position
10 Error Indicator
11 Not Available";
CM_ SG_ 2365401086 Jystick8GripYAxisDetentPosStatus "Reports when the current joystick grip position is in the detent position for that axis of travel.

00 Not in the Detent Position
01 In the Detent Position
10 Error Indicator
11 Not Available";
CM_ SG_ 2365401086 Jystick8ThetaAxisDetentPosStatus "Reports when the current joystick position is in the detent position for that axis of travel.

00 Not in the Detent Position
01 In the Detent Position
10 Error Indicator
11 Not Available";
CM_ SG_ 2365401086 Joystick8ThetaAxisPos "The position of the joystick in the relative motion of travel from the neutral position.  Position value of 0 is Neutral and position value 1000 (100%) is the end of linear zone.  Value of 1022 indicates an error has occurred.";
CM_ SG_ 2365401086 Jystck8ThtAxsClckwsPstvPosStatus "Reports when the current joystick position is on the positive travel side (forward, right, clockwise, up) relative to the neutral position for that axis of travel.
00 Not on Positive side of Neutral
01 On positive side of Neutral
10 Error ...";
CM_ SG_ 2365401086 Jystck8ThtAxsCntrClckwsNgtvPsStt "Reports when the current joystick position is on the negative travel side (back, left, counterclockwise, down) relative to the neutral position for that axis of travel.
00 Not on negative side of Neutral
01 On negative side of Neutral
10 Error ...";
CM_ SG_ 2365401086 Jystck8ThetaAxisNeutralPosStatus "Reports when the current joystick position is in the neutral position for that axis of travel.  The neutral position measurement must be determined from some mechanism other than the axis position measurement device.
00 Not in Neutral Position
01 ...";
CM_ SG_ 2365401086 Joystick8GripYAxisPos "The position of the joystick grip in the relative motion of travel from the neutral position.  Position value of 0 is Neutral and position value 1000 (100%) is the end of linear zone.  Value of 1022 indicates an error has occurred.";
CM_ SG_ 2365401086 Jystck8GrpYAxsLvrFrwrdPstvPsStts "Reports when the current joystick grip position is on the positive travel side (forward, right, clockwise, up) relative to the neutral position for that axis of travel.
00 Not on Positive side of Neutral
01 On positive side of Neutral
10 Error ...";
CM_ SG_ 2365401086 Jystck8GrpYAxsLvrBckNgtvPsStatus "Reports when the current joystick grip position is on the negative travel side (back, left, counterclockwise, down) relative to the neutral position for that axis of travel.
00 Not on negative side of Neutral
01 On negative side of Neutral
10 ...";
CM_ SG_ 2365401086 Jystck8GripYAxisNeutralPosStatus "Reports when the current joystick grip position is in the neutral position for that axis of travel.  The neutral position measurement must be determined from some mechanism other than the axis position measurement device.
00 Not in Neutral Position
 ...";
CM_ SG_ 2365401086 Joystick8GripXAxisPos "The position of the joystick grip in the relative motion of travel from the neutral position.  Position value of 0 is Neutral and position value 1000 (100%) is the end of linear zone.  Value of 1022 indicates an error has occurred.";
CM_ SG_ 2365401086 Jystck8GrpXAxsLvrRghtPstvPsSttus "Reports when the current joystick grip position is on the positive travel side (forward, right, clockwise, up) relative to the neutral position for that axis of travel.
00 Not on Positive side of Neutral
01 On positive side of Neutral
10 Error ...";
CM_ SG_ 2365401086 Jystck8GrpXAxsLvrLftNgtvPsStatus "Reports when the current joystick grip position is on the negative travel side (back, left, counterclockwise, down) relative to the neutral position for that axis of travel.
00 Not on negative side of Neutral
01 On negative side of Neutral
10 ...";
CM_ SG_ 2365401086 Jystck8GripXAxisNeutralPosStatus "Reports when the current joystick grip position is in the neutral position for that axis of travel.  The neutral position measurement must be determined from some mechanism other than the axis position measurement device.
00 Not in Neutral Position
 ...";
CM_ BO_ 2365401598 "Extended Joystick Message 7
Used to transfer information about the measured status of three additional axes of a joystick and switches of the joystick grip or handle.  The joystick axial motion information is available in the Basic Joystick ...";
CM_ SG_ 2365401598 Joystick7Button13PressedStatus "Reports when the joystick button has been pressed.

00 Button not pressed
01 Button pressed
10 Error Indicator
11 Not Available";
CM_ SG_ 2365401598 Joystick7Button14PressedStatus "Reports when the joystick button has been pressed.

00 Button not pressed
01 Button pressed
10 Error Indicator
11 Not Available";
CM_ SG_ 2365401598 Joystick7Button15PressedStatus "Reports when the joystick button has been pressed.

00 Button not pressed
01 Button pressed
10 Error Indicator
11 Not Available";
CM_ SG_ 2365401598 Joystick7Button16PressedStatus "Reports when the joystick button has been pressed.

00 Button not pressed
01 Button pressed
10 Error Indicator
11 Not Available";
CM_ SG_ 2365401598 Jystick7GripXAxisDetentPosStatus "Reports when the current joystick grip position is in the detent position for that axis of travel.

00 Not in the Detent Position
01 In the Detent Position
10 Error Indicator
11 Not Available";
CM_ SG_ 2365401598 Jystick7GripYAxisDetentPosStatus "Reports when the current joystick grip position is in the detent position for that axis of travel.

00 Not in the Detent Position
01 In the Detent Position
10 Error Indicator
11 Not Available";
CM_ SG_ 2365401598 Jystick7ThetaAxisDetentPosStatus "Reports when the current joystick position is in the detent position for that axis of travel.

00 Not in the Detent Position
01 In the Detent Position
10 Error Indicator
11 Not Available";
CM_ SG_ 2365401598 Joystick7ThetaAxisPos "The position of the joystick in the relative motion of travel from the neutral position.  Position value of 0 is Neutral and position value 1000 (100%) is the end of linear zone.  Value of 1022 indicates an error has occurred.";
CM_ SG_ 2365401598 Jystck7ThtAxsClckwsPstvPosStatus "Reports when the current joystick position is on the positive travel side (forward, right, clockwise, up) relative to the neutral position for that axis of travel.
00 Not on Positive side of Neutral
01 On positive side of Neutral
10 Error ...";
CM_ SG_ 2365401598 Jystck7ThtAxsCntrClckwsNgtvPsStt "Reports when the current joystick position is on the negative travel side (back, left, counterclockwise, down) relative to the neutral position for that axis of travel.
00 Not on negative side of Neutral
01 On negative side of Neutral
10 Error ...";
CM_ SG_ 2365401598 Jystck7ThetaAxisNeutralPosStatus "Reports when the current joystick position is in the neutral position for that axis of travel.  The neutral position measurement must be determined from some mechanism other than the axis position measurement device.
00 Not in Neutral Position
01 ...";
CM_ SG_ 2365401598 Joystick7GripYAxisPos "The position of the joystick grip in the relative motion of travel from the neutral position.  Position value of 0 is Neutral and position value 1000 (100%) is the end of linear zone.  Value of 1022 indicates an error has occurred.";
CM_ SG_ 2365401598 Jystck7GrpYAxsLvrFrwrdPstvPsStts "Reports when the current joystick grip position is on the positive travel side (forward, right, clockwise, up) relative to the neutral position for that axis of travel.
00 Not on Positive side of Neutral
01 On positive side of Neutral
10 Error ...";
CM_ SG_ 2365401598 Jystck7GrpYAxsLvrBckNgtvPsStatus "Reports when the current joystick grip position is on the negative travel side (back, left, counterclockwise, down) relative to the neutral position for that axis of travel.
00 Not on negative side of Neutral
01 On negative side of Neutral
10 ...";
CM_ SG_ 2365401598 Jystck7GripYAxisNeutralPosStatus "Reports when the current joystick grip position is in the neutral position for that axis of travel.  The neutral position measurement must be determined from some mechanism other than the axis position measurement device.
00 Not in Neutral Position
 ...";
CM_ SG_ 2365401598 Joystick7GripXAxisPos "The position of the joystick grip in the relative motion of travel from the neutral position.  Position value of 0 is Neutral and position value 1000 (100%) is the end of linear zone.  Value of 1022 indicates an error has occurred.";
CM_ SG_ 2365401598 Jystck7GrpXAxsLvrRghtPstvPsSttus "Reports when the current joystick grip position is on the positive travel side (forward, right, clockwise, up) relative to the neutral position for that axis of travel.
00 Not on Positive side of Neutral
01 On positive side of Neutral
10 Error ...";
CM_ SG_ 2365401598 Jystck7GrpXAxsLvrLftNgtvPsStatus "Reports when the current joystick grip position is on the negative travel side (back, left, counterclockwise, down) relative to the neutral position for that axis of travel.
00 Not on negative side of Neutral
01 On negative side of Neutral
10 ...";
CM_ SG_ 2365401598 Jystck7GripXAxisNeutralPosStatus "Reports when the current joystick grip position is in the neutral position for that axis of travel.  The neutral position measurement must be determined from some mechanism other than the axis position measurement device.
00 Not in Neutral Position
 ...";
BA_DEF_ SG_  "SigType" ENUM  "Default","Range","RangeSigned","ASCII","Discrete","Control","ReferencePGN","DTC","StringDelimiter","StringLength","StringLengthControl","MessageCounter","MessageChecksum";
BA_DEF_ SG_  "GenSigStartValue" INT 0 2147483647;
BA_DEF_ SG_  "GenSigSendType" ENUM  "Cyclic","OnWrite","OnWriteWithRepetition","OnChange","OnChangeWithRepetition","IfActive","IfActiveWithRepetition","NoSigSendType";
BA_DEF_ SG_  "GenSigILSupport" ENUM  "No","Yes";
BA_DEF_ SG_  "GenSigEVName" STRING ;
BA_DEF_ SG_  "SPN" INT 0 524287;
BA_DEF_ BO_  "TpJ1939VarDlc" ENUM  "No","Yes";
BA_DEF_ BO_  "GenMsgStartDelayTime" INT 0 100000;
BA_DEF_ BO_  "GenMsgILSupport" ENUM  "No","Yes";
BA_DEF_ BO_  "GenMsgDelayTime" INT 0 1000;
BA_DEF_ BO_  "GenMsgRequestable" INT 0 1;
BA_DEF_ BO_  "GenMsgSendType" ENUM  "cyclic","NotUsed","NotUsed","NotUsed","NotUsed","NotUsed","NotUsed","IfActive","noMsgSendType";
BA_DEF_ BO_  "VFrameFormat" ENUM  "StandardCAN","ExtendedCAN","reserved","J1939PG";
BA_DEF_ BO_  "GenMsgCycleTime" INT 0 3600000;
BA_DEF_ SG_  "SystemSignalLongSymbol" STRING ;
BA_DEF_DEF_  "SigType" "Default";
BA_DEF_DEF_  "GenSigStartValue" 0;
BA_DEF_DEF_  "GenSigSendType" "NoSigSendType";
BA_DEF_DEF_  "GenSigILSupport" "Yes";
BA_DEF_DEF_  "GenSigEVName" "Env@Nodename_@Signame";
BA_DEF_DEF_  "SPN" 0;
BA_DEF_DEF_  "TpJ1939VarDlc" "No";
BA_DEF_DEF_  "GenMsgStartDelayTime" 0;
BA_DEF_DEF_  "GenMsgILSupport" "Yes";
BA_DEF_DEF_  "GenMsgDelayTime" 0;
BA_DEF_DEF_  "GenMsgRequestable" 1;
BA_DEF_DEF_  "GenMsgSendType" "noMsgSendType";
BA_DEF_DEF_  "VFrameFormat" "J1939PG";
BA_DEF_DEF_  "GenMsgCycleTime" 0;
BA_DEF_DEF_  "SystemSignalLongSymbol" "";
BA_ "GenMsgCycleTime" BO_ 2566730238 1000;
BA_ "GenMsgSendType" BO_ 2566730238 0;
BA_ "GenMsgCycleTime" BO_ 2566711038 500;
BA_ "GenMsgSendType" BO_ 2566711038 0;
BA_ "GenMsgCycleTime" BO_ 2566710782 30000;
BA_ "GenMsgSendType" BO_ 2566710782 0;
BA_ "GenMsgCycleTime" BO_ 2566710526 30000;
BA_ "GenMsgSendType" BO_ 2566710526 0;
BA_ "GenMsgCycleTime" BO_ 2432492542 100;
BA_ "GenMsgSendType" BO_ 2432492542 0;
BA_ "GenMsgCycleTime" BO_ 2566710014 1000;
BA_ "GenMsgSendType" BO_ 2566710014 0;
BA_ "GenMsgCycleTime" BO_ 2566709758 100;
BA_ "GenMsgSendType" BO_ 2566709758 0;
BA_ "GenMsgCycleTime" BO_ 2566709502 100;
BA_ "GenMsgSendType" BO_ 2566709502 0;
BA_ "GenMsgCycleTime" BO_ 2566709246 500;
BA_ "GenMsgSendType" BO_ 2566709246 0;
BA_ "GenMsgCycleTime" BO_ 2566708990 500;
BA_ "GenMsgSendType" BO_ 2566708990 0;
BA_ "GenMsgCycleTime" BO_ 2566708734 500;
BA_ "GenMsgSendType" BO_ 2566708734 0;
BA_ "GenMsgCycleTime" BO_ 2566708478 1000;
BA_ "GenMsgSendType" BO_ 2566708478 0;
BA_ "GenMsgDelayTime" BO_ 2566708478 100;
BA_ "GenMsgCycleTime" BO_ 2566708222 1000;
BA_ "GenMsgSendType" BO_ 2566708222 0;
BA_ "GenMsgCycleTime" BO_ 2566707966 1000;
BA_ "GenMsgSendType" BO_ 2566707966 0;
BA_ "GenMsgCycleTime" BO_ 2566707710 1000;
BA_ "GenMsgSendType" BO_ 2566707710 0;
BA_ "GenMsgCycleTime" BO_ 2297441790 10;
BA_ "GenMsgSendType" BO_ 2297441790 0;
BA_ "GenMsgCycleTime" BO_ 2566699006 1000;
BA_ "GenMsgSendType" BO_ 2566699006 0;
BA_ "GenMsgCycleTime" BO_ 2364549630 10;
BA_ "GenMsgSendType" BO_ 2364549630 0;
BA_ "GenMsgCycleTime" BO_ 2499614462 5000;
BA_ "GenMsgSendType" BO_ 2499614462 0;
BA_ "GenMsgDelayTime" BO_ 2499614462 250;
BA_ "GenMsgCycleTime" BO_ 2560098046 10000;
BA_ "GenMsgSendType" BO_ 2560098046 0;
BA_ "GenMsgDelayTime" BO_ 2560098046 1000;
BA_ "GenMsgCycleTime" BO_ 2560163582 10000;
BA_ "GenMsgSendType" BO_ 2560163582 0;
BA_ "GenMsgCycleTime" BO_ 2297441534 50;
BA_ "GenMsgSendType" BO_ 2297441534 0;
BA_ "GenMsgCycleTime" BO_ 2566722302 500;
BA_ "GenMsgSendType" BO_ 2566722302 0;
BA_ "GenMsgDelayTime" BO_ 2560032510 500;
BA_ "GenMsgCycleTime" BO_ 2566717950 500;
BA_ "GenMsgSendType" BO_ 2566717950 0;
BA_ "GenMsgCycleTime" BO_ 2499604222 200;
BA_ "GenMsgSendType" BO_ 2499604222 0;
BA_ "GenMsgCycleTime" BO_ 2358902526 100;
BA_ "GenMsgSendType" BO_ 2358902526 0;
BA_ "GenMsgCycleTime" BO_ 2566711550 500;
BA_ "GenMsgSendType" BO_ 2566711550 0;
BA_ "GenMsgCycleTime" BO_ 2566719998 1000;
BA_ "GenMsgSendType" BO_ 2566719998 0;
BA_ "GenMsgCycleTime" BO_ 2566713854 100;
BA_ "GenMsgSendType" BO_ 2566713854 0;
BA_ "GenMsgCycleTime" BO_ 2566714366 100;
BA_ "GenMsgSendType" BO_ 2566714366 0;
BA_ "GenMsgCycleTime" BO_ 2566714110 100;
BA_ "GenMsgSendType" BO_ 2566714110 0;
BA_ "GenMsgCycleTime" BO_ 2566717438 1000;
BA_ "GenMsgSendType" BO_ 2566717438 0;
BA_ "GenMsgCycleTime" BO_ 2633828606 30000;
BA_ "GenMsgSendType" BO_ 2633828606 0;
BA_ "GenMsgCycleTime" BO_ 2365400574 100;
BA_ "GenMsgSendType" BO_ 2365400574 0;
BA_ "GenMsgDelayTime" BO_ 2365400574 20;
BA_ "GenMsgCycleTime" BO_ 2365401086 100;
BA_ "GenMsgSendType" BO_ 2365401086 0;
BA_ "GenMsgDelayTime" BO_ 2365401086 20;
BA_ "GenMsgCycleTime" BO_ 2365401598 100;
BA_ "GenMsgSendType" BO_ 2365401598 0;
BA_ "GenMsgDelayTime" BO_ 2365401598 20;
BA_ "SPN" SG_ 2566730238 Fan2DriveBypassCmdStatus 1708;
BA_ "SigType" SG_ 2566730238 Fan2DriveBypassCmdStatus 1;
BA_ "SPN" SG_ 2566730238 HydFan2MotorPress 1707;
BA_ "SigType" SG_ 2566730238 HydFan2MotorPress 1;
BA_ "SPN" SG_ 2566730238 Fan2Speed 1598;
BA_ "SigType" SG_ 2566730238 Fan2Speed 1;
BA_ "SPN" SG_ 2566730238 Fan2DriveState 1557;
BA_ "SPN" SG_ 2566730238 EstPercentFan2Speed 1550;
BA_ "SigType" SG_ 2566730238 EstPercentFan2Speed 1;
BA_ "SPN" SG_ 2566711038 LubricationTimingCycleStatus 5520;
BA_ "SigType" SG_ 2566711038 LubricationTimingCycleStatus 5;
BA_ "SPN" SG_ 2566711038 LubricationReservoirLevel 5519;
BA_ "SigType" SG_ 2566711038 LubricationReservoirLevel 4;
BA_ "SPN" SG_ 2566711038 LubricationPumpEnableStatus 5518;
BA_ "SigType" SG_ 2566711038 LubricationPumpEnableStatus 5;
BA_ "SPN" SG_ 2566711038 LubricationOperationModeStatus 5517;
BA_ "SPN" SG_ 2566711038 LubricationCycleModeStatus 5516;
BA_ "SPN" SG_ 2566711038 LubricationCycleModeLockStatus 5515;
BA_ "SigType" SG_ 2566711038 LubricationCycleModeLockStatus 5;
BA_ "SPN" SG_ 2566710782 HydOilTemp 5536;
BA_ "SigType" SG_ 2566710782 HydOilTemp 1;
BA_ "SPN" SG_ 2566710782 HydOilRelativeDielectricity 5535;
BA_ "SigType" SG_ 2566710782 HydOilRelativeDielectricity 1;
BA_ "SPN" SG_ 2566710782 HydOilDensity 5534;
BA_ "SigType" SG_ 2566710782 HydOilDensity 1;
BA_ "SPN" SG_ 2566710782 HydOilDynamicViscosity 5533;
BA_ "SigType" SG_ 2566710782 HydOilDynamicViscosity 1;
BA_ "SPN" SG_ 2566710526 EngFuelTemp 5540;
BA_ "SigType" SG_ 2566710526 EngFuelTemp 1;
BA_ "SPN" SG_ 2566710526 EngFuelDielectricity 5539;
BA_ "SigType" SG_ 2566710526 EngFuelDielectricity 1;
BA_ "SPN" SG_ 2566710526 EngFuelDensity 5538;
BA_ "SigType" SG_ 2566710526 EngFuelDensity 1;
BA_ "SPN" SG_ 2566710526 EngFuelDynamicViscosity 5537;
BA_ "SigType" SG_ 2566710526 EngFuelDynamicViscosity 1;
BA_ "SPN" SG_ 2432492542 DsredEngTurbo2TurbineOutletPress 5545;
BA_ "SigType" SG_ 2432492542 DsredEngTurbo2TurbineOutletPress 1;
BA_ "SPN" SG_ 2432492542 EngTurbo2TurbineOutletPress 5544;
BA_ "SigType" SG_ 2432492542 EngTurbo2TurbineOutletPress 1;
BA_ "SPN" SG_ 2432492542 EngExhaustBrakeActuatorCmd 5543;
BA_ "SigType" SG_ 2432492542 EngExhaustBrakeActuatorCmd 1;
BA_ "SPN" SG_ 2432492542 DsredEngTurbo1TurbineOutletPress 5542;
BA_ "SigType" SG_ 2432492542 DsredEngTurbo1TurbineOutletPress 1;
BA_ "SPN" SG_ 2432492542 EngTurbo1TurbineOutletPress 5541;
BA_ "SigType" SG_ 2432492542 EngTurbo1TurbineOutletPress 1;
BA_ "SPN" SG_ 2566710014 SupplementalFanPower 5564;
BA_ "SigType" SG_ 2566710014 SupplementalFanPower 1;
BA_ "SPN" SG_ 2566710014 SupplementalFanCurrent 5563;
BA_ "SigType" SG_ 2566710014 SupplementalFanCurrent 1;
BA_ "SPN" SG_ 2566710014 SupplementalFanSpeed 5562;
BA_ "SigType" SG_ 2566710014 SupplementalFanSpeed 1;
BA_ "SPN" SG_ 2566710014 SupplementalFanCtrlECUTemp 5561;
BA_ "SigType" SG_ 2566710014 SupplementalFanCtrlECUTemp 1;
BA_ "SPN" SG_ 2566710014 SupplementalFanDriveStatus 5560;
BA_ "SPN" SG_ 2566710014 SupplementalFanCtrlTempStatus 5559;
BA_ "SPN" SG_ 2566710014 SupplementalFanVelocityStatus 5558;
BA_ "SPN" SG_ 2566710014 SupplementalFanDirectionStatus 5557;
BA_ "SigType" SG_ 2566710014 SupplementalFanDirectionStatus 5;
BA_ "SPN" SG_ 2566710014 SupplementalFanEnableStatus 5556;
BA_ "SigType" SG_ 2566710014 SupplementalFanEnableStatus 5;
BA_ "SPN" SG_ 2566709758 EngDieselFuelDemandRate 7596;
BA_ "SigType" SG_ 2566709758 EngDieselFuelDemandRate 1;
BA_ "SPN" SG_ 2566709758 HighResolutionEngFuelRate 1600;
BA_ "SigType" SG_ 2566709758 HighResolutionEngFuelRate 1;
BA_ "SPN" SG_ 2566709502 AFT2FuelMassRate 5834;
BA_ "SigType" SG_ 2566709502 AFT2FuelMassRate 1;
BA_ "SPN" SG_ 2566709502 AFT1FuelMassRate 5503;
BA_ "SigType" SG_ 2566709502 AFT1FuelMassRate 1;
BA_ "SPN" SG_ 2566709502 RelativeUnburnedFuelMassFromEng 5502;
BA_ "SigType" SG_ 2566709502 RelativeUnburnedFuelMassFromEng 1;
BA_ "SPN" SG_ 2566709502 AFT1DPFInTempSetPoint 5501;
BA_ "SigType" SG_ 2566709502 AFT1DPFInTempSetPoint 1;
BA_ "SPN" SG_ 2566709246 ThrottleVlv2DiffPress 7595;
BA_ "SigType" SG_ 2566709246 ThrottleVlv2DiffPress 1;
BA_ "SPN" SG_ 2566709246 EngFuelSupplyPumpIntakeAbsPress 7472;
BA_ "SigType" SG_ 2566709246 EngFuelSupplyPumpIntakeAbsPress 1;
BA_ "SPN" SG_ 2566709246 EngFuelReturnPress 6816;
BA_ "SigType" SG_ 2566709246 EngFuelReturnPress 1;
BA_ "SPN" SG_ 2566709246 EngFuelFilterDegradation 5584;
BA_ "SigType" SG_ 2566709246 EngFuelFilterDegradation 1;
BA_ "SPN" SG_ 2566709246 EngFilteredFuelDeliveryAbsPress 5580;
BA_ "SigType" SG_ 2566709246 EngFilteredFuelDeliveryAbsPress 1;
BA_ "SPN" SG_ 2566709246 EngFilteredFuelDeliveryPress 5579;
BA_ "SigType" SG_ 2566709246 EngFilteredFuelDeliveryPress 1;
BA_ "SPN" SG_ 2566709246 EngFuelDeliveryAbsPress 5578;
BA_ "SigType" SG_ 2566709246 EngFuelDeliveryAbsPress 1;
BA_ "SPN" SG_ 2566708990 SecondAirAbsPress 5589;
BA_ "SigType" SG_ 2566708990 SecondAirAbsPress 1;
BA_ "SPN" SG_ 2566708734 SecondAirAbsPress 5590;
BA_ "SigType" SG_ 2566708734 SecondAirAbsPress 1;
BA_ "SPN" SG_ 2566708478 DriverCancellationStatus 7836;
BA_ "SigType" SG_ 2566708478 DriverCancellationStatus 5;
BA_ "SPN" SG_ 2566708478 CruiseCtrlSpeed 7319;
BA_ "SigType" SG_ 2566708478 CruiseCtrlSpeed 1;
BA_ "SPN" SG_ 2566708478 CruiseCtrlSetSpeed 6809;
BA_ "SigType" SG_ 2566708478 CruiseCtrlSetSpeed 1;
BA_ "SPN" SG_ 2566708478 PrdctvCrsCtrlStSpeedOffsetStatus 7318;
BA_ "SigType" SG_ 2566708478 PrdctvCrsCtrlStSpeedOffsetStatus 5;
BA_ "SPN" SG_ 2566708478 AEBSReadinessState 6208;
BA_ "SigType" SG_ 2566708478 AEBSReadinessState 5;
BA_ "SPN" SG_ 2566708478 SrcAddrssOfCntrllngDvcFrPsngCrsC 5609;
BA_ "SPN" SG_ 2566708478 SrcAddrssOfCntrllngDvcFrDsblngCr 5608;
BA_ "SPN" SG_ 2566708478 CruiseCtrlSystemCmdState 5607;
BA_ "SPN" SG_ 2566708478 AdptiveCruiseCtrlReadinessStatus 5606;
BA_ "SigType" SG_ 2566708478 AdptiveCruiseCtrlReadinessStatus 5;
BA_ "SPN" SG_ 2566708222 SnsrAnalysisReqFreq4 5635;
BA_ "SigType" SG_ 2566708222 SnsrAnalysisReqFreq4 1;
BA_ "SPN" SG_ 2566708222 SnsrAnalysisReqFreq3 5634;
BA_ "SigType" SG_ 2566708222 SnsrAnalysisReqFreq3 1;
BA_ "SPN" SG_ 2566708222 SnsrAnalysisReqFreq2 5633;
BA_ "SigType" SG_ 2566708222 SnsrAnalysisReqFreq2 1;
BA_ "SPN" SG_ 2566708222 SnsrAnalysisReqFreq1 5632;
BA_ "SigType" SG_ 2566708222 SnsrAnalysisReqFreq1 1;
BA_ "SPN" SG_ 2566707966 SnsrFreq2SootSignal 5639;
BA_ "SigType" SG_ 2566707966 SnsrFreq2SootSignal 1;
BA_ "SPN" SG_ 2566707966 SnsrAnalysisFreq2 5638;
BA_ "SigType" SG_ 2566707966 SnsrAnalysisFreq2 1;
BA_ "SPN" SG_ 2566707966 SnsrFreq1SootSignal 5637;
BA_ "SigType" SG_ 2566707966 SnsrFreq1SootSignal 1;
BA_ "SPN" SG_ 2566707966 SnsrAnalysisFreq1 5636;
BA_ "SigType" SG_ 2566707966 SnsrAnalysisFreq1 1;
BA_ "SPN" SG_ 2566707710 SnsrFreq4SootSignal 5643;
BA_ "SigType" SG_ 2566707710 SnsrFreq4SootSignal 1;
BA_ "SPN" SG_ 2566707710 SnsrAnalysisFreq4 5642;
BA_ "SigType" SG_ 2566707710 SnsrAnalysisFreq4 1;
BA_ "SPN" SG_ 2566707710 SnsrFreq3SootSignal 5641;
BA_ "SigType" SG_ 2566707710 SnsrFreq3SootSignal 1;
BA_ "SPN" SG_ 2566707710 SnsrAnalysisFreq3 5640;
BA_ "SigType" SG_ 2566707710 SnsrAnalysisFreq3 1;
BA_ "SPN" SG_ 2297441790 SpprtVrblTrnsRpttnRtFrAcclrtnSns 5353;
BA_ "SigType" SG_ 2297441790 SpprtVrblTrnsRpttnRtFrAcclrtnSns 5;
BA_ "SPN" SG_ 2297441790 VrtclAcclrtnExRangeFigureOfMerit 5352;
BA_ "SigType" SG_ 2297441790 VrtclAcclrtnExRangeFigureOfMerit 5;
BA_ "SPN" SG_ 2297441790 LngtdnlAcclrtnExRngFigureOfMerit 5351;
BA_ "SigType" SG_ 2297441790 LngtdnlAcclrtnExRngFigureOfMerit 5;
BA_ "SPN" SG_ 2297441790 LtrlAcclrtonExRangeFigureOfMerit 5350;
BA_ "SigType" SG_ 2297441790 LtrlAcclrtonExRangeFigureOfMerit 5;
BA_ "SPN" SG_ 2297441790 VerticalAccelerationExRange 5349;
BA_ "SigType" SG_ 2297441790 VerticalAccelerationExRange 1;
BA_ "SPN" SG_ 2297441790 LongitudinalAccelerationExRange 5348;
BA_ "SigType" SG_ 2297441790 LongitudinalAccelerationExRange 1;
BA_ "SPN" SG_ 2297441790 LateralAccelerationExRange 5347;
BA_ "SigType" SG_ 2297441790 LateralAccelerationExRange 1;
BA_ "SPN" SG_ 2566699006 PropulsionModeRemainingDist 9709;
BA_ "SigType" SG_ 2566699006 PropulsionModeRemainingDist 1;
BA_ "SPN" SG_ 2566699006 PropulsionModeMaxSpdSetting 9708;
BA_ "SigType" SG_ 2566699006 PropulsionModeMaxSpdSetting 1;
BA_ "SPN" SG_ 2566699006 EngStopStartRemainingPercentage 8558;
BA_ "SigType" SG_ 2566699006 EngStopStartRemainingPercentage 1;
BA_ "SPN" SG_ 2566699006 HybridBatteryPackRemainingCharge 5464;
BA_ "SigType" SG_ 2566699006 HybridBatteryPackRemainingCharge 1;
BA_ "SPN" SG_ 2364549630 RllAndPtchExRngMasurementLatency 4982;
BA_ "SigType" SG_ 2364549630 RllAndPtchExRngMasurementLatency 1;
BA_ "SPN" SG_ 2364549630 RollAngleExRangeFigureOfMerit 4981;
BA_ "SigType" SG_ 2364549630 RollAngleExRangeFigureOfMerit 5;
BA_ "SPN" SG_ 2364549630 RollAngleExRangeCompensation 4980;
BA_ "SigType" SG_ 2364549630 RollAngleExRangeCompensation 5;
BA_ "SPN" SG_ 2364549630 PitchAngleExRangeFigureOfMerit 4979;
BA_ "SigType" SG_ 2364549630 PitchAngleExRangeFigureOfMerit 5;
BA_ "SPN" SG_ 2364549630 PitchAngleExRangeCompensation 4978;
BA_ "SigType" SG_ 2364549630 PitchAngleExRangeCompensation 5;
BA_ "SPN" SG_ 2364549630 RollAngleExRange 4977;
BA_ "SPN" SG_ 2364549630 PitchAngleExRange 4976;
BA_ "SPN" SG_ 2499614462 OccpntClssficationSystem10Status 4972;
BA_ "SigType" SG_ 2499614462 OccpntClssficationSystem10Status 5;
BA_ "SPN" SG_ 2499614462 OccpntClssificationSystem9Status 4971;
BA_ "SigType" SG_ 2499614462 OccpntClssificationSystem9Status 5;
BA_ "SPN" SG_ 2499614462 OccpntClssificationSystem8Status 4970;
BA_ "SigType" SG_ 2499614462 OccpntClssificationSystem8Status 5;
BA_ "SPN" SG_ 2499614462 OccpntClssificationSystem7Status 4969;
BA_ "SigType" SG_ 2499614462 OccpntClssificationSystem7Status 5;
BA_ "SPN" SG_ 2499614462 OccpntClssificationSystem6Status 4968;
BA_ "SigType" SG_ 2499614462 OccpntClssificationSystem6Status 5;
BA_ "SPN" SG_ 2499614462 OccpntClssificationSystem5Status 4967;
BA_ "SigType" SG_ 2499614462 OccpntClssificationSystem5Status 5;
BA_ "SPN" SG_ 2499614462 OccpntClssificationSystem4Status 4966;
BA_ "SigType" SG_ 2499614462 OccpntClssificationSystem4Status 5;
BA_ "SPN" SG_ 2499614462 OccpntClssificationSystem3Status 4965;
BA_ "SigType" SG_ 2499614462 OccpntClssificationSystem3Status 5;
BA_ "SPN" SG_ 2499614462 PssngrOccpntClssfctnSystemStatus 4964;
BA_ "SPN" SG_ 2499614462 DrvrOccpntClssfctionSystemStatus 4963;
BA_ "SPN" SG_ 2560098046 CabNoiseCtrlTuningStatus 5060;
BA_ "SPN" SG_ 2560098046 CabNoiseCtrlStatus 5059;
BA_ "SigType" SG_ 2560098046 CabNoiseCtrlStatus 5;
BA_ "SPN" SG_ 2560163582 CabNoiseCtrlTuningCmd 5058;
BA_ "SPN" SG_ 2560163582 CabNoiseCtrlCmd 5057;
BA_ "SigType" SG_ 2560163582 CabNoiseCtrlCmd 5;
BA_ "SPN" SG_ 2297441534 MagnetGeneratorCtrl 5551;
BA_ "SigType" SG_ 2297441534 MagnetGeneratorCtrl 5;
BA_ "SPN" SG_ 2297441534 DropRelayCtrl 5403;
BA_ "SigType" SG_ 2297441534 DropRelayCtrl 5;
BA_ "SPN" SG_ 2297441534 LiftRelayCtrl 5402;
BA_ "SigType" SG_ 2297441534 LiftRelayCtrl 5;
BA_ "SPN" SG_ 2297441534 MaterialDropActiveStatus 5014;
BA_ "SigType" SG_ 2297441534 MaterialDropActiveStatus 5;
BA_ "SPN" SG_ 2297441534 MaterialLiftActiveStatus 5013;
BA_ "SigType" SG_ 2297441534 MaterialLiftActiveStatus 5;
BA_ "SPN" SG_ 2297441534 GneratorCurrentBoostActiveStatus 5012;
BA_ "SigType" SG_ 2297441534 GneratorCurrentBoostActiveStatus 5;
BA_ "SPN" SG_ 2297441534 MaterialDropSwitch 5011;
BA_ "SigType" SG_ 2297441534 MaterialDropSwitch 5;
BA_ "SPN" SG_ 2297441534 MaterialLiftSwitch 5010;
BA_ "SigType" SG_ 2297441534 MaterialLiftSwitch 5;
BA_ "SPN" SG_ 2297441534 MagnetReverseCurrent 5009;
BA_ "SigType" SG_ 2297441534 MagnetReverseCurrent 1;
BA_ "SPN" SG_ 2297441534 MagnetForwardCurrent 5008;
BA_ "SigType" SG_ 2297441534 MagnetForwardCurrent 1;
BA_ "SPN" SG_ 2566722302 GeneratorDutyCycleExceededStatus 5007;
BA_ "SigType" SG_ 2566722302 GeneratorDutyCycleExceededStatus 5;
BA_ "SPN" SG_ 2566722302 VoltageMonitorActiveStatus 5006;
BA_ "SigType" SG_ 2566722302 VoltageMonitorActiveStatus 5;
BA_ "SPN" SG_ 2566722302 GensetEnableActiveStatus 5005;
BA_ "SigType" SG_ 2566722302 GensetEnableActiveStatus 5;
BA_ "SPN" SG_ 2566722302 ReverseCurrentRangeSetting 5002;
BA_ "SPN" SG_ 2566722302 GensetSoftstartActiveStatus 5004;
BA_ "SigType" SG_ 2566722302 GensetSoftstartActiveStatus 5;
BA_ "SPN" SG_ 2566722302 Grapple_MagnetSelectionSwitch 5003;
BA_ "SigType" SG_ 2566722302 Grapple_MagnetSelectionSwitch 5;
BA_ "SPN" SG_ 2566722302 GnstSystmOtputVoltageRangeStatus 5001;
BA_ "SigType" SG_ 2566722302 GnstSystmOtputVoltageRangeStatus 5;
BA_ "SPN" SG_ 2566722302 GeneratorOverheatStatus 5000;
BA_ "SigType" SG_ 2566722302 GeneratorOverheatStatus 5;
BA_ "SPN" SG_ 2566722558 MagnetRatedPower 4999;
BA_ "SigType" SG_ 2566722558 MagnetRatedPower 1;
BA_ "SPN" SG_ 2566722558 MagnetBoostTime 4998;
BA_ "SigType" SG_ 2566722558 MagnetBoostTime 1;
BA_ "SPN" SG_ 2560032510 LwVltgDscnnctDsiredOperatingMode 5149;
BA_ "SPN" SG_ 2566717950 LowVoltageDisconnectTemp 5148;
BA_ "SigType" SG_ 2566717950 LowVoltageDisconnectTemp 1;
BA_ "SPN" SG_ 2566717950 LwVltgeDisconnectVoutOutputState 5147;
BA_ "SPN" SG_ 2566717950 LowVoltageDisconnectOutput1State 5146;
BA_ "SPN" SG_ 2566717950 LowVoltageDisconnectOutput2State 5145;
BA_ "SPN" SG_ 2566717950 LowVoltageDisconnectOutput3State 5144;
BA_ "SPN" SG_ 2566717950 LwVltgDscnnctCrrentOperatingMode 5143;
BA_ "SPN" SG_ 2566717950 LwVltgDscnnectManualConnectState 5142;
BA_ "SigType" SG_ 2566717950 LwVltgDscnnectManualConnectState 4;
BA_ "SPN" SG_ 2566717950 LwVltgDscnnctMnalDisconnectState 5141;
BA_ "SigType" SG_ 2566717950 LwVltgDscnnctMnalDisconnectState 4;
BA_ "SPN" SG_ 2499604222 BldReferenceElevationOffsetRight 5413;
BA_ "SigType" SG_ 2499604222 BldReferenceElevationOffsetRight 1;
BA_ "SPN" SG_ 2499604222 BldeReferenceElevationOffsetLeft 5412;
BA_ "SigType" SG_ 2499604222 BldeReferenceElevationOffsetLeft 1;
BA_ "SPN" SG_ 2499604222 BladeElevationDeviationRight 5411;
BA_ "SigType" SG_ 2499604222 BladeElevationDeviationRight 1;
BA_ "SPN" SG_ 2499604222 BladeElevationDeviationLeft 5410;
BA_ "SigType" SG_ 2499604222 BladeElevationDeviationLeft 1;
BA_ "SPN" SG_ 2358902526 Joystick3Lamp10Cmd 4489;
BA_ "SigType" SG_ 2358902526 Joystick3Lamp10Cmd 5;
BA_ "SPN" SG_ 2358902526 Joystick3Lamp9Cmd 4488;
BA_ "SigType" SG_ 2358902526 Joystick3Lamp9Cmd 5;
BA_ "SPN" SG_ 2358902526 Joystick3Lamp8Cmd 4487;
BA_ "SigType" SG_ 2358902526 Joystick3Lamp8Cmd 5;
BA_ "SPN" SG_ 2358902526 Joystick3Lamp7Cmd 4486;
BA_ "SigType" SG_ 2358902526 Joystick3Lamp7Cmd 5;
BA_ "SPN" SG_ 2358902526 Joystick3Lamp6Cmd 4485;
BA_ "SigType" SG_ 2358902526 Joystick3Lamp6Cmd 5;
BA_ "SPN" SG_ 2358902526 Joystick3Lamp5Cmd 4484;
BA_ "SigType" SG_ 2358902526 Joystick3Lamp5Cmd 5;
BA_ "SPN" SG_ 2358902526 Joystick3Lamp4Cmd 4483;
BA_ "SigType" SG_ 2358902526 Joystick3Lamp4Cmd 5;
BA_ "SPN" SG_ 2358902526 Joystick3Lamp3Cmd 4482;
BA_ "SigType" SG_ 2358902526 Joystick3Lamp3Cmd 5;
BA_ "SPN" SG_ 2358902526 Joystick3Lamp2Cmd 4481;
BA_ "SigType" SG_ 2358902526 Joystick3Lamp2Cmd 5;
BA_ "SPN" SG_ 2358902526 Joystick3Lamp1Cmd 4480;
BA_ "SigType" SG_ 2358902526 Joystick3Lamp1Cmd 5;
BA_ "SPN" SG_ 2358902526 Joystick2Lamp10Cmd 4479;
BA_ "SigType" SG_ 2358902526 Joystick2Lamp10Cmd 5;
BA_ "SPN" SG_ 2358902526 Joystick2Lamp9Cmd 4478;
BA_ "SigType" SG_ 2358902526 Joystick2Lamp9Cmd 5;
BA_ "SPN" SG_ 2358902526 Joystick2Lamp8Cmd 4477;
BA_ "SigType" SG_ 2358902526 Joystick2Lamp8Cmd 5;
BA_ "SPN" SG_ 2358902526 Joystick2Lamp7Cmd 4476;
BA_ "SigType" SG_ 2358902526 Joystick2Lamp7Cmd 5;
BA_ "SPN" SG_ 2358902526 Joystick2Lamp6Cmd 4475;
BA_ "SigType" SG_ 2358902526 Joystick2Lamp6Cmd 5;
BA_ "SPN" SG_ 2358902526 Joystick2Lamp5Cmd 4474;
BA_ "SigType" SG_ 2358902526 Joystick2Lamp5Cmd 5;
BA_ "SPN" SG_ 2358902526 Joystick2Lamp4Cmd 4473;
BA_ "SigType" SG_ 2358902526 Joystick2Lamp4Cmd 5;
BA_ "SPN" SG_ 2358902526 Joystick2Lamp3Cmd 4472;
BA_ "SigType" SG_ 2358902526 Joystick2Lamp3Cmd 5;
BA_ "SPN" SG_ 2358902526 Joystick2Lamp2Cmd 4471;
BA_ "SigType" SG_ 2358902526 Joystick2Lamp2Cmd 5;
BA_ "SPN" SG_ 2358902526 Joystick2Lamp1Cmd 4470;
BA_ "SigType" SG_ 2358902526 Joystick2Lamp1Cmd 5;
BA_ "SPN" SG_ 2358902526 Joystick1Lamp10Cmd 4469;
BA_ "SigType" SG_ 2358902526 Joystick1Lamp10Cmd 5;
BA_ "SPN" SG_ 2358902526 Joystick1Lamp9Cmd 4468;
BA_ "SigType" SG_ 2358902526 Joystick1Lamp9Cmd 5;
BA_ "SPN" SG_ 2358902526 Joystick1Lamp8Cmd 4467;
BA_ "SigType" SG_ 2358902526 Joystick1Lamp8Cmd 5;
BA_ "SPN" SG_ 2358902526 Joystick1Lamp7Cmd 4466;
BA_ "SigType" SG_ 2358902526 Joystick1Lamp7Cmd 5;
BA_ "SPN" SG_ 2358902526 Joystick1Lamp6Cmd 4465;
BA_ "SigType" SG_ 2358902526 Joystick1Lamp6Cmd 5;
BA_ "SPN" SG_ 2358902526 Joystick1Lamp5Cmd 4464;
BA_ "SigType" SG_ 2358902526 Joystick1Lamp5Cmd 5;
BA_ "SPN" SG_ 2358902526 Joystick1Lamp4Cmd 4463;
BA_ "SigType" SG_ 2358902526 Joystick1Lamp4Cmd 5;
BA_ "SPN" SG_ 2358902526 Joystick1Lamp3Cmd 4462;
BA_ "SigType" SG_ 2358902526 Joystick1Lamp3Cmd 5;
BA_ "SPN" SG_ 2358902526 Joystick1Lamp2Cmd 4461;
BA_ "SigType" SG_ 2358902526 Joystick1Lamp2Cmd 5;
BA_ "SPN" SG_ 2358902526 Joystick1Lamp1Cmd 4460;
BA_ "SigType" SG_ 2358902526 Joystick1Lamp1Cmd 5;
BA_ "SPN" SG_ 2566711550 IntkVlvActtnSystmOlPrss2SlndCtrl 5500;
BA_ "SigType" SG_ 2566711550 IntkVlvActtnSystmOlPrss2SlndCtrl 5;
BA_ "SPN" SG_ 2566711550 IntkVlvActtnSystmOlPrss1SlndCtrl 5499;
BA_ "SigType" SG_ 2566711550 IntkVlvActtnSystmOlPrss1SlndCtrl 5;
BA_ "SPN" SG_ 2633832958 SpecialIgnitorLoop90Resistance 4917;
BA_ "SigType" SG_ 2633832958 SpecialIgnitorLoop90Resistance 1;
BA_ "SPN" SG_ 2633832958 SpecialIgnitorLoop89Resistance 4916;
BA_ "SigType" SG_ 2633832958 SpecialIgnitorLoop89Resistance 1;
BA_ "SPN" SG_ 2633832958 SpecialIgnitorLoop88Resistance 4915;
BA_ "SigType" SG_ 2633832958 SpecialIgnitorLoop88Resistance 1;
BA_ "SPN" SG_ 2633832958 SpecialIgnitorLoop87Resistance 4914;
BA_ "SigType" SG_ 2633832958 SpecialIgnitorLoop87Resistance 1;
BA_ "SPN" SG_ 2633832958 SpecialIgnitorLoop86Resistance 4913;
BA_ "SigType" SG_ 2633832958 SpecialIgnitorLoop86Resistance 1;
BA_ "SPN" SG_ 2633832958 SpecialIgnitorLoop85Resistance 4912;
BA_ "SigType" SG_ 2633832958 SpecialIgnitorLoop85Resistance 1;
BA_ "SPN" SG_ 2633832958 SpecialIgnitorLoop84Resistance 4911;
BA_ "SigType" SG_ 2633832958 SpecialIgnitorLoop84Resistance 1;
BA_ "SPN" SG_ 2633832958 SpecialIgnitorLoop83Resistance 4910;
BA_ "SigType" SG_ 2633832958 SpecialIgnitorLoop83Resistance 1;
BA_ "SPN" SG_ 2633832958 SpecialIgnitorLoop82Resistance 4909;
BA_ "SigType" SG_ 2633832958 SpecialIgnitorLoop82Resistance 1;
BA_ "SPN" SG_ 2633832958 SpecialIgnitorLoop81Resistance 4908;
BA_ "SigType" SG_ 2633832958 SpecialIgnitorLoop81Resistance 1;
BA_ "SPN" SG_ 2633832958 SpecialIgnitorLoop80Resistance 4907;
BA_ "SigType" SG_ 2633832958 SpecialIgnitorLoop80Resistance 1;
BA_ "SPN" SG_ 2633832958 SpecialIgnitorLoop79Resistance 4906;
BA_ "SigType" SG_ 2633832958 SpecialIgnitorLoop79Resistance 1;
BA_ "SPN" SG_ 2633832958 SpecialIgnitorLoop78Resistance 4905;
BA_ "SigType" SG_ 2633832958 SpecialIgnitorLoop78Resistance 1;
BA_ "SPN" SG_ 2633832958 SpecialIgnitorLoop77Resistance 4904;
BA_ "SigType" SG_ 2633832958 SpecialIgnitorLoop77Resistance 1;
BA_ "SPN" SG_ 2633832958 SpecialIgnitorLoop76Resistance 4903;
BA_ "SigType" SG_ 2633832958 SpecialIgnitorLoop76Resistance 1;
BA_ "SPN" SG_ 2633832958 SpecialIgnitorLoop75Resistance 4902;
BA_ "SigType" SG_ 2633832958 SpecialIgnitorLoop75Resistance 1;
BA_ "SPN" SG_ 2633832958 SpecialIgnitorLoop74Resistance 4901;
BA_ "SigType" SG_ 2633832958 SpecialIgnitorLoop74Resistance 1;
BA_ "SPN" SG_ 2633832958 SpecialIgnitorLoop73Resistance 4900;
BA_ "SigType" SG_ 2633832958 SpecialIgnitorLoop73Resistance 1;
BA_ "SPN" SG_ 2633832958 SpecialIgnitorLoop72Resistance 4899;
BA_ "SigType" SG_ 2633832958 SpecialIgnitorLoop72Resistance 1;
BA_ "SPN" SG_ 2633832958 SpecialIgnitorLoop71Resistance 4898;
BA_ "SigType" SG_ 2633832958 SpecialIgnitorLoop71Resistance 1;
BA_ "SPN" SG_ 2633832958 SpecialIgnitorLoop70Resistance 4897;
BA_ "SigType" SG_ 2633832958 SpecialIgnitorLoop70Resistance 1;
BA_ "SPN" SG_ 2633832958 SpecialIgnitorLoop69Resistance 4896;
BA_ "SigType" SG_ 2633832958 SpecialIgnitorLoop69Resistance 1;
BA_ "SPN" SG_ 2633832958 SpecialIgnitorLoop68Resistance 4895;
BA_ "SigType" SG_ 2633832958 SpecialIgnitorLoop68Resistance 1;
BA_ "SPN" SG_ 2633832958 SpecialIgnitorLoop67Resistance 4894;
BA_ "SigType" SG_ 2633832958 SpecialIgnitorLoop67Resistance 1;
BA_ "SPN" SG_ 2633832958 SpecialIgnitorLoop66Resistance 4893;
BA_ "SigType" SG_ 2633832958 SpecialIgnitorLoop66Resistance 1;
BA_ "SPN" SG_ 2633832958 SpecialIgnitorLoop65Resistance 4892;
BA_ "SigType" SG_ 2633832958 SpecialIgnitorLoop65Resistance 1;
BA_ "SPN" SG_ 2633832958 SpecialIgnitorLoop64Resistance 4891;
BA_ "SigType" SG_ 2633832958 SpecialIgnitorLoop64Resistance 1;
BA_ "SPN" SG_ 2633832958 SpecialIgnitorLoop63Resistance 4890;
BA_ "SigType" SG_ 2633832958 SpecialIgnitorLoop63Resistance 1;
BA_ "SPN" SG_ 2633832958 SpecialIgnitorLoop62Resistance 4889;
BA_ "SigType" SG_ 2633832958 SpecialIgnitorLoop62Resistance 1;
BA_ "SPN" SG_ 2633832958 SpecialIgnitorLoop61Resistance 4888;
BA_ "SigType" SG_ 2633832958 SpecialIgnitorLoop61Resistance 1;
BA_ "SPN" SG_ 2633832958 SpecialIgnitorLoop60Resistance 4887;
BA_ "SigType" SG_ 2633832958 SpecialIgnitorLoop60Resistance 1;
BA_ "SPN" SG_ 2633832958 SpecialIgnitorLoop59Resistance 4886;
BA_ "SigType" SG_ 2633832958 SpecialIgnitorLoop59Resistance 1;
BA_ "SPN" SG_ 2633832958 SpecialIgnitorLoop58Resistance 4885;
BA_ "SigType" SG_ 2633832958 SpecialIgnitorLoop58Resistance 1;
BA_ "SPN" SG_ 2633832958 SpecialIgnitorLoop57Resistance 4884;
BA_ "SigType" SG_ 2633832958 SpecialIgnitorLoop57Resistance 1;
BA_ "SPN" SG_ 2633832958 SpecialIgnitorLoop56Resistance 4883;
BA_ "SigType" SG_ 2633832958 SpecialIgnitorLoop56Resistance 1;
BA_ "SPN" SG_ 2633832958 SpecialIgnitorLoop55Resistance 4882;
BA_ "SigType" SG_ 2633832958 SpecialIgnitorLoop55Resistance 1;
BA_ "SPN" SG_ 2633832958 SpecialIgnitorLoop54Resistance 4881;
BA_ "SigType" SG_ 2633832958 SpecialIgnitorLoop54Resistance 1;
BA_ "SPN" SG_ 2633832958 SpecialIgnitorLoop53Resistance 4880;
BA_ "SigType" SG_ 2633832958 SpecialIgnitorLoop53Resistance 1;
BA_ "SPN" SG_ 2633832958 SpecialIgnitorLoop52Resistance 4879;
BA_ "SigType" SG_ 2633832958 SpecialIgnitorLoop52Resistance 1;
BA_ "SPN" SG_ 2633832958 SpecialIgnitorLoop51Resistance 4878;
BA_ "SigType" SG_ 2633832958 SpecialIgnitorLoop51Resistance 1;
BA_ "SPN" SG_ 2633832958 SpecialIgnitorLoop50Resistance 4877;
BA_ "SigType" SG_ 2633832958 SpecialIgnitorLoop50Resistance 1;
BA_ "SPN" SG_ 2633832958 SpecialIgnitorLoop49Resistance 4876;
BA_ "SigType" SG_ 2633832958 SpecialIgnitorLoop49Resistance 1;
BA_ "SPN" SG_ 2633832958 SpecialIgnitorLoop48Resistance 4875;
BA_ "SigType" SG_ 2633832958 SpecialIgnitorLoop48Resistance 1;
BA_ "SPN" SG_ 2633832958 SpecialIgnitorLoop47Resistance 4874;
BA_ "SigType" SG_ 2633832958 SpecialIgnitorLoop47Resistance 1;
BA_ "SPN" SG_ 2633832958 SpecialIgnitorLoop46Resistance 4873;
BA_ "SigType" SG_ 2633832958 SpecialIgnitorLoop46Resistance 1;
BA_ "SPN" SG_ 2633832958 SpecialIgnitorLoop45Resistance 4872;
BA_ "SigType" SG_ 2633832958 SpecialIgnitorLoop45Resistance 1;
BA_ "SPN" SG_ 2633832958 SpecialIgnitorLoop44Resistance 4871;
BA_ "SigType" SG_ 2633832958 SpecialIgnitorLoop44Resistance 1;
BA_ "SPN" SG_ 2633832958 SpecialIgnitorLoop43Resistance 4870;
BA_ "SigType" SG_ 2633832958 SpecialIgnitorLoop43Resistance 1;
BA_ "SPN" SG_ 2633832958 SpecialIgnitorLoop42Resistance 4869;
BA_ "SigType" SG_ 2633832958 SpecialIgnitorLoop42Resistance 1;
BA_ "SPN" SG_ 2633832958 SpecialIgnitorLoop41Resistance 4868;
BA_ "SigType" SG_ 2633832958 SpecialIgnitorLoop41Resistance 1;
BA_ "SPN" SG_ 2633832958 SpecialIgnitorLoop40Resistance 4867;
BA_ "SigType" SG_ 2633832958 SpecialIgnitorLoop40Resistance 1;
BA_ "SPN" SG_ 2633832958 SpecialIgnitorLoop39Resistance 4866;
BA_ "SigType" SG_ 2633832958 SpecialIgnitorLoop39Resistance 1;
BA_ "SPN" SG_ 2633832958 SpecialIgnitorLoop38Resistance 4865;
BA_ "SigType" SG_ 2633832958 SpecialIgnitorLoop38Resistance 1;
BA_ "SPN" SG_ 2633832958 SpecialIgnitorLoop37Resistance 4864;
BA_ "SigType" SG_ 2633832958 SpecialIgnitorLoop37Resistance 1;
BA_ "SPN" SG_ 2633832958 SpecialIgnitorLoop36Resistance 4863;
BA_ "SigType" SG_ 2633832958 SpecialIgnitorLoop36Resistance 1;
BA_ "SPN" SG_ 2633832958 SpecialIgnitorLoop35Resistance 4862;
BA_ "SigType" SG_ 2633832958 SpecialIgnitorLoop35Resistance 1;
BA_ "SPN" SG_ 2633832958 SpecialIgnitorLoop34Resistance 4861;
BA_ "SigType" SG_ 2633832958 SpecialIgnitorLoop34Resistance 1;
BA_ "SPN" SG_ 2633832958 SpecialIgnitorLoop33Resistance 4860;
BA_ "SigType" SG_ 2633832958 SpecialIgnitorLoop33Resistance 1;
BA_ "SPN" SG_ 2633832958 SpecialIgnitorLoop32Resistance 4859;
BA_ "SigType" SG_ 2633832958 SpecialIgnitorLoop32Resistance 1;
BA_ "SPN" SG_ 2633832958 SpecialIgnitorLoop31Resistance 4858;
BA_ "SigType" SG_ 2633832958 SpecialIgnitorLoop31Resistance 1;
BA_ "SPN" SG_ 2633832958 SpecialIgnitorLoop30Resistance 4857;
BA_ "SigType" SG_ 2633832958 SpecialIgnitorLoop30Resistance 1;
BA_ "SPN" SG_ 2633832958 SpecialIgnitorLoop29Resistance 4856;
BA_ "SigType" SG_ 2633832958 SpecialIgnitorLoop29Resistance 1;
BA_ "SPN" SG_ 2633832958 SpecialIgnitorLoop28Resistance 4855;
BA_ "SigType" SG_ 2633832958 SpecialIgnitorLoop28Resistance 1;
BA_ "SPN" SG_ 2633832958 SpecialIgnitorLoop27Resistance 4854;
BA_ "SigType" SG_ 2633832958 SpecialIgnitorLoop27Resistance 1;
BA_ "SPN" SG_ 2633832958 SpecialIgnitorLoop26Resistance 4853;
BA_ "SigType" SG_ 2633832958 SpecialIgnitorLoop26Resistance 1;
BA_ "SPN" SG_ 2633832958 SpecialIgnitorLoop25Resistance 4852;
BA_ "SigType" SG_ 2633832958 SpecialIgnitorLoop25Resistance 1;
BA_ "SPN" SG_ 2633832958 SpecialIgnitorLoop24Resistance 4851;
BA_ "SigType" SG_ 2633832958 SpecialIgnitorLoop24Resistance 1;
BA_ "SPN" SG_ 2633832958 SpecialIgnitorLoop23Resistance 4850;
BA_ "SigType" SG_ 2633832958 SpecialIgnitorLoop23Resistance 1;
BA_ "SPN" SG_ 2633832958 SpecialIgnitorLoop22Resistance 4849;
BA_ "SigType" SG_ 2633832958 SpecialIgnitorLoop22Resistance 1;
BA_ "SPN" SG_ 2633832958 SpecialIgnitorLoop21Resistance 4848;
BA_ "SigType" SG_ 2633832958 SpecialIgnitorLoop21Resistance 1;
BA_ "SPN" SG_ 2633832958 SpecialIgnitorLoop20Resistance 4847;
BA_ "SigType" SG_ 2633832958 SpecialIgnitorLoop20Resistance 1;
BA_ "SPN" SG_ 2633832958 SpecialIgnitorLoop19Resistance 4846;
BA_ "SigType" SG_ 2633832958 SpecialIgnitorLoop19Resistance 1;
BA_ "SPN" SG_ 2633832958 SpecialIgnitorLoop18Resistance 4845;
BA_ "SigType" SG_ 2633832958 SpecialIgnitorLoop18Resistance 1;
BA_ "SPN" SG_ 2633832958 SpecialIgnitorLoop17Resistance 4844;
BA_ "SigType" SG_ 2633832958 SpecialIgnitorLoop17Resistance 1;
BA_ "SPN" SG_ 2633832958 SpecialIgnitorLoop16Resistance 4843;
BA_ "SigType" SG_ 2633832958 SpecialIgnitorLoop16Resistance 1;
BA_ "SPN" SG_ 2633832958 SpecialIgnitorLoop15Resistance 4842;
BA_ "SigType" SG_ 2633832958 SpecialIgnitorLoop15Resistance 1;
BA_ "SPN" SG_ 2633832958 SpecialIgnitorLoop14Resistance 4841;
BA_ "SigType" SG_ 2633832958 SpecialIgnitorLoop14Resistance 1;
BA_ "SPN" SG_ 2633832958 SpecialIgnitorLoop13Resistance 4840;
BA_ "SigType" SG_ 2633832958 SpecialIgnitorLoop13Resistance 1;
BA_ "SPN" SG_ 2633832958 SpecialIgnitorLoop12Resistance 4839;
BA_ "SigType" SG_ 2633832958 SpecialIgnitorLoop12Resistance 1;
BA_ "SPN" SG_ 2633832958 SpecialIgnitorLoop11Resistance 4838;
BA_ "SigType" SG_ 2633832958 SpecialIgnitorLoop11Resistance 1;
BA_ "SPN" SG_ 2633832958 SpecialIgnitorLoop10Resistance 4837;
BA_ "SigType" SG_ 2633832958 SpecialIgnitorLoop10Resistance 1;
BA_ "SPN" SG_ 2633832958 SpecialIgnitorLoop9Resistance 4836;
BA_ "SigType" SG_ 2633832958 SpecialIgnitorLoop9Resistance 1;
BA_ "SPN" SG_ 2633832958 SpecialIgnitorLoop8Resistance 4835;
BA_ "SigType" SG_ 2633832958 SpecialIgnitorLoop8Resistance 1;
BA_ "SPN" SG_ 2633832958 SpecialIgnitorLoop7Resistance 4834;
BA_ "SigType" SG_ 2633832958 SpecialIgnitorLoop7Resistance 1;
BA_ "SPN" SG_ 2633832958 SpecialIgnitorLoop6Resistance 4833;
BA_ "SigType" SG_ 2633832958 SpecialIgnitorLoop6Resistance 1;
BA_ "SPN" SG_ 2633832958 SpecialIgnitorLoop5Resistance 4832;
BA_ "SigType" SG_ 2633832958 SpecialIgnitorLoop5Resistance 1;
BA_ "SPN" SG_ 2633832958 SpecialIgnitorLoop4Resistance 4831;
BA_ "SigType" SG_ 2633832958 SpecialIgnitorLoop4Resistance 1;
BA_ "SPN" SG_ 2633832958 SpecialIgnitorLoop3Resistance 4830;
BA_ "SigType" SG_ 2633832958 SpecialIgnitorLoop3Resistance 1;
BA_ "SPN" SG_ 2633832958 SpecialIgnitorLoop2Resistance 4829;
BA_ "SigType" SG_ 2633832958 SpecialIgnitorLoop2Resistance 1;
BA_ "SPN" SG_ 2633832958 SpecialIgnitorLoop1Resistance 4828;
BA_ "SigType" SG_ 2633832958 SpecialIgnitorLoop1Resistance 1;
BA_ "SPN" SG_ 2633832958 SdBagIgnitorLoop2RightResistance 4827;
BA_ "SigType" SG_ 2633832958 SdBagIgnitorLoop2RightResistance 1;
BA_ "SPN" SG_ 2633832958 SdBagIgnitorLoop1RightResistance 4826;
BA_ "SigType" SG_ 2633832958 SdBagIgnitorLoop1RightResistance 1;
BA_ "SPN" SG_ 2633832958 SdeBagIgnitorLoop2LeftResistance 4825;
BA_ "SigType" SG_ 2633832958 SdeBagIgnitorLoop2LeftResistance 1;
BA_ "SPN" SG_ 2633832958 SdeBagIgnitorLoop1LeftResistance 4824;
BA_ "SigType" SG_ 2633832958 SdeBagIgnitorLoop1LeftResistance 1;
BA_ "SPN" SG_ 2633832958 PssngrBltTnsnrIgntrLopResistance 4823;
BA_ "SigType" SG_ 2633832958 PssngrBltTnsnrIgntrLopResistance 1;
BA_ "SPN" SG_ 2633832958 DrvrBltTnsnrIgntorLoopResistance 4822;
BA_ "SigType" SG_ 2633832958 DrvrBltTnsnrIgntorLoopResistance 1;
BA_ "SPN" SG_ 2633832958 PssngrArbgIgntrLp2ndStgRsistance 4821;
BA_ "SigType" SG_ 2633832958 PssngrArbgIgntrLp2ndStgRsistance 1;
BA_ "SPN" SG_ 2633832958 DrvrArbgIgntrLp2ndStgeResistance 4820;
BA_ "SigType" SG_ 2633832958 DrvrArbgIgntrLp2ndStgeResistance 1;
BA_ "SPN" SG_ 2633832958 PssngrArbgIgntrLp1stStgRsistance 4819;
BA_ "SigType" SG_ 2633832958 PssngrArbgIgntrLp1stStgRsistance 1;
BA_ "SPN" SG_ 2633832958 DrvrArbgIgntrLp1stStgeResistance 4818;
BA_ "SigType" SG_ 2633832958 DrvrArbgIgntrLp1stStgeResistance 1;
BA_ "SPN" SG_ 2566719998 HighResolutionEngTotalFuelUsed 5054;
BA_ "SigType" SG_ 2566719998 HighResolutionEngTotalFuelUsed 1;
BA_ "SPN" SG_ 2566719998 HighResolutionEngTripFuel 5053;
BA_ "SigType" SG_ 2566719998 HighResolutionEngTripFuel 1;
BA_ "SPN" SG_ 2565877502 EngTrbCmprssrBlowoffActuator1Cmd 6201;
BA_ "SigType" SG_ 2565877502 EngTrbCmprssrBlowoffActuator1Cmd 1;
BA_ "SPN" SG_ 2565877502 EngExhstBckPressRegulatorCtrlCmd 649;
BA_ "SigType" SG_ 2565877502 EngExhstBckPressRegulatorCtrlCmd 1;
BA_ "SPN" SG_ 2565877502 EngTurboWastegateActuator2Cmd 5387;
BA_ "SigType" SG_ 2565877502 EngTurboWastegateActuator2Cmd 1;
BA_ "SPN" SG_ 2565877502 EngTurboWastegateActuator1Cmd 5386;
BA_ "SigType" SG_ 2565877502 EngTurboWastegateActuator1Cmd 1;
BA_ "SPN" SG_ 2566713854 EngExhaustBackPressActuator1Temp 5790;
BA_ "SigType" SG_ 2566713854 EngExhaustBackPressActuator1Temp 1;
BA_ "SPN" SG_ 2566713854 EngExhstBckPrssActtor1DesiredPos 5789;
BA_ "SigType" SG_ 2566713854 EngExhstBckPrssActtor1DesiredPos 1;
BA_ "SPN" SG_ 2566713854 EngTurboWastegateActuator1Temp 5788;
BA_ "SigType" SG_ 2566713854 EngTurboWastegateActuator1Temp 1;
BA_ "SPN" SG_ 2566713854 EngExhstBckPrssRgltrCtrlOprtnStt 5628;
BA_ "SPN" SG_ 2566713854 EngExhstBckPrssRglatorTempStatus 5627;
BA_ "SPN" SG_ 2566713854 EngExhstBckPrssRgltrPrlminaryFMI 5626;
BA_ "SPN" SG_ 2566713854 EngExhaustBackPressRegulatorPos 5625;
BA_ "SigType" SG_ 2566713854 EngExhaustBackPressRegulatorPos 1;
BA_ "SPN" SG_ 2566713854 EngTrbWstgtActtr2OperationStatus 5452;
BA_ "SPN" SG_ 2566713854 EngTrbWstgtActtr1OperationStatus 5451;
BA_ "SPN" SG_ 2566713854 EngTrbWstgateActuator2TempStatus 5385;
BA_ "SPN" SG_ 2566713854 EngTrbWstgtActtor2PreliminaryFMI 5384;
BA_ "SPN" SG_ 2566714366 EngTrbCmprssrBypassActuator2Temp 5792;
BA_ "SigType" SG_ 2566714366 EngTrbCmprssrBypassActuator2Temp 1;
BA_ "SPN" SG_ 2566714366 EngTrbCmprssrBypassActuator1Temp 5791;
BA_ "SigType" SG_ 2566714366 EngTrbCmprssrBypassActuator1Temp 1;
BA_ "SPN" SG_ 2566714366 EngTrbCmprssrBypssActtr2OprtnStt 5450;
BA_ "SPN" SG_ 2566714366 EngTrbCmprssrBypssActtr1OprtnStt 5449;
BA_ "SPN" SG_ 2566714366 EngTrbCmprssrBypssActtr2TmpSttus 5391;
BA_ "SPN" SG_ 2566714366 EngTrbCmprssrBypssActtr2PrlmnryF 5390;
BA_ "SPN" SG_ 2566714366 EngDsrdTrbCmprssrBypssActtor2Pos 5389;
BA_ "SigType" SG_ 2566714366 EngDsrdTrbCmprssrBypssActtor2Pos 1;
BA_ "SPN" SG_ 2566714366 EngTrbCmprssorBypassActuator2Pos 5388;
BA_ "SigType" SG_ 2566714366 EngTrbCmprssorBypassActuator2Pos 1;
BA_ "SPN" SG_ 2566714110 EngFuelValve2OperationStatus 5448;
BA_ "SPN" SG_ 2566714110 EngFuelValve1OperationStatus 5447;
BA_ "SPN" SG_ 2566714110 EngThrottleValve2OperationStatus 5446;
BA_ "SPN" SG_ 2566714110 EngThrottleValve1OperationStatus 5445;
BA_ "SPN" SG_ 2566714110 EngFuelValve2TempStatus 5383;
BA_ "SPN" SG_ 2566714110 EngFuelValve2PreliminaryFMI 5382;
BA_ "SPN" SG_ 2566714110 EngFuelValve1TempStatus 5381;
BA_ "SPN" SG_ 2566714110 EngFuelValve1PreliminaryFMI 5380;
BA_ "SPN" SG_ 2566714110 EngThrottleValve2TempStatus 5379;
BA_ "SPN" SG_ 2566714110 EngThrottleValve2PreliminaryFMI 5378;
BA_ "SPN" SG_ 2566714110 EngDesiredThrottleValve2Pos 5377;
BA_ "SigType" SG_ 2566714110 EngDesiredThrottleValve2Pos 1;
BA_ "SPN" SG_ 2566714110 EngThrottleValve1TempStatus 5376;
BA_ "SPN" SG_ 2566714110 EngThrottleValve1PreliminaryFMI 5375;
BA_ "SPN" SG_ 2566714110 EngDesiredThrottleValve1Pos 5374;
BA_ "SigType" SG_ 2566714110 EngDesiredThrottleValve1Pos 1;
BA_ "SPN" SG_ 2566717438 EngExhstGsRcrcltn2MxerIntakeTemp 5256;
BA_ "SigType" SG_ 2566717438 EngExhstGsRcrcltn2MxerIntakeTemp 1;
BA_ "SPN" SG_ 2566717438 EngExhaustGasRecirculation2Temp 5255;
BA_ "SigType" SG_ 2566717438 EngExhaustGasRecirculation2Temp 1;
BA_ "SPN" SG_ 2633828606 EngOilTemp3 5925;
BA_ "SigType" SG_ 2633828606 EngOilTemp3 1;
BA_ "SPN" SG_ 2633828606 EngOilRelativeDielectricity 5468;
BA_ "SigType" SG_ 2633828606 EngOilRelativeDielectricity 1;
BA_ "SPN" SG_ 2633828606 EngOilDensity 5056;
BA_ "SigType" SG_ 2633828606 EngOilDensity 1;
BA_ "SPN" SG_ 2633828606 EngOilViscosity 5055;
BA_ "SigType" SG_ 2633828606 EngOilViscosity 1;
BA_ "SPN" SG_ 2499607550 EngExhstMnfldBnk2FlwBlncVlvActtr 5279;
BA_ "SigType" SG_ 2499607550 EngExhstMnfldBnk2FlwBlncVlvActtr 1;
BA_ "SPN" SG_ 2499607550 EngExhstMnfldBnk1FlwBlncVlvActtr 5277;
BA_ "SigType" SG_ 2499607550 EngExhstMnfldBnk1FlwBlncVlvActtr 1;
BA_ "SPN" SG_ 2633825534 EngExhstMnfldBnk2FlwBlncVlvActtr 5278;
BA_ "SigType" SG_ 2633825534 EngExhstMnfldBnk2FlwBlncVlvActtr 1;
BA_ "SPN" SG_ 2633825534 EngExhstMnfldBnk1FlwBlncVlvActtr 5276;
BA_ "SigType" SG_ 2633825534 EngExhstMnfldBnk1FlwBlncVlvActtr 1;
BA_ "SPN" SG_ 2365400574 Joystick9Button13PressedStatus 6763;
BA_ "SigType" SG_ 2365400574 Joystick9Button13PressedStatus 4;
BA_ "SPN" SG_ 2365400574 Joystick9Button14PressedStatus 6764;
BA_ "SigType" SG_ 2365400574 Joystick9Button14PressedStatus 4;
BA_ "SPN" SG_ 2365400574 Joystick9Button15PressedStatus 6765;
BA_ "SigType" SG_ 2365400574 Joystick9Button15PressedStatus 4;
BA_ "SPN" SG_ 2365400574 Joystick9Button16PressedStatus 6766;
BA_ "SigType" SG_ 2365400574 Joystick9Button16PressedStatus 4;
BA_ "SPN" SG_ 2365400574 Jystick9GripXAxisDetentPosStatus 4712;
BA_ "SigType" SG_ 2365400574 Jystick9GripXAxisDetentPosStatus 4;
BA_ "SPN" SG_ 2365400574 Jystick9GripYAxisDetentPosStatus 4711;
BA_ "SigType" SG_ 2365400574 Jystick9GripYAxisDetentPosStatus 4;
BA_ "SPN" SG_ 2365400574 Jystick9ThetaAxisDetentPosStatus 4710;
BA_ "SigType" SG_ 2365400574 Jystick9ThetaAxisDetentPosStatus 4;
BA_ "SPN" SG_ 2365400574 Joystick9ThetaAxisPos 4709;
BA_ "SPN" SG_ 2365400574 Jystck9ThtAxsClckwsPstvPosStatus 4708;
BA_ "SigType" SG_ 2365400574 Jystck9ThtAxsClckwsPstvPosStatus 4;
BA_ "SPN" SG_ 2365400574 Jystck9ThtAxsCntrClckwsNgtvPsStt 4707;
BA_ "SigType" SG_ 2365400574 Jystck9ThtAxsCntrClckwsNgtvPsStt 4;
BA_ "SPN" SG_ 2365400574 Jystck9ThetaAxisNeutralPosStatus 4706;
BA_ "SigType" SG_ 2365400574 Jystck9ThetaAxisNeutralPosStatus 4;
BA_ "SPN" SG_ 2365400574 Joystick9GripYAxisPos 4705;
BA_ "SPN" SG_ 2365400574 Jystck9GrpYAxsLvrFrwrdPstvPsStts 4704;
BA_ "SigType" SG_ 2365400574 Jystck9GrpYAxsLvrFrwrdPstvPsStts 4;
BA_ "SPN" SG_ 2365400574 Jystck9GrpYAxsLvrBckNgtvPsStatus 4703;
BA_ "SigType" SG_ 2365400574 Jystck9GrpYAxsLvrBckNgtvPsStatus 4;
BA_ "SPN" SG_ 2365400574 Jystck9GripYAxisNeutralPosStatus 4702;
BA_ "SigType" SG_ 2365400574 Jystck9GripYAxisNeutralPosStatus 4;
BA_ "SPN" SG_ 2365400574 Joystick9GripXAxisPos 4701;
BA_ "SPN" SG_ 2365400574 Jystck9GrpXAxsLvrRghtPstvPsSttus 4700;
BA_ "SigType" SG_ 2365400574 Jystck9GrpXAxsLvrRghtPstvPsSttus 4;
BA_ "SPN" SG_ 2365400574 Jystck9GrpXAxsLvrLftNgtvPsStatus 4699;
BA_ "SigType" SG_ 2365400574 Jystck9GrpXAxsLvrLftNgtvPsStatus 4;
BA_ "SPN" SG_ 2365400574 Jystck9GripXAxisNeutralPosStatus 4698;
BA_ "SigType" SG_ 2365400574 Jystck9GripXAxisNeutralPosStatus 4;
BA_ "SPN" SG_ 2365401086 Joystick8Button13PressedStatus 6759;
BA_ "SigType" SG_ 2365401086 Joystick8Button13PressedStatus 4;
BA_ "SPN" SG_ 2365401086 Joystick8Button14PressedStatus 6760;
BA_ "SigType" SG_ 2365401086 Joystick8Button14PressedStatus 4;
BA_ "SPN" SG_ 2365401086 Joystick8Button15PressedStatus 6761;
BA_ "SigType" SG_ 2365401086 Joystick8Button15PressedStatus 4;
BA_ "SPN" SG_ 2365401086 Joystick8Button16PressedStatus 6762;
BA_ "SigType" SG_ 2365401086 Joystick8Button16PressedStatus 4;
BA_ "SPN" SG_ 2365401086 Jystick8GripXAxisDetentPosStatus 4675;
BA_ "SigType" SG_ 2365401086 Jystick8GripXAxisDetentPosStatus 4;
BA_ "SPN" SG_ 2365401086 Jystick8GripYAxisDetentPosStatus 4674;
BA_ "SigType" SG_ 2365401086 Jystick8GripYAxisDetentPosStatus 4;
BA_ "SPN" SG_ 2365401086 Jystick8ThetaAxisDetentPosStatus 4673;
BA_ "SigType" SG_ 2365401086 Jystick8ThetaAxisDetentPosStatus 4;
BA_ "SPN" SG_ 2365401086 Joystick8ThetaAxisPos 4672;
BA_ "SPN" SG_ 2365401086 Jystck8ThtAxsClckwsPstvPosStatus 4671;
BA_ "SigType" SG_ 2365401086 Jystck8ThtAxsClckwsPstvPosStatus 4;
BA_ "SPN" SG_ 2365401086 Jystck8ThtAxsCntrClckwsNgtvPsStt 4670;
BA_ "SigType" SG_ 2365401086 Jystck8ThtAxsCntrClckwsNgtvPsStt 4;
BA_ "SPN" SG_ 2365401086 Jystck8ThetaAxisNeutralPosStatus 4669;
BA_ "SigType" SG_ 2365401086 Jystck8ThetaAxisNeutralPosStatus 4;
BA_ "SPN" SG_ 2365401086 Joystick8GripYAxisPos 4668;
BA_ "SPN" SG_ 2365401086 Jystck8GrpYAxsLvrFrwrdPstvPsStts 4667;
BA_ "SigType" SG_ 2365401086 Jystck8GrpYAxsLvrFrwrdPstvPsStts 4;
BA_ "SPN" SG_ 2365401086 Jystck8GrpYAxsLvrBckNgtvPsStatus 4666;
BA_ "SigType" SG_ 2365401086 Jystck8GrpYAxsLvrBckNgtvPsStatus 4;
BA_ "SPN" SG_ 2365401086 Jystck8GripYAxisNeutralPosStatus 4665;
BA_ "SigType" SG_ 2365401086 Jystck8GripYAxisNeutralPosStatus 4;
BA_ "SPN" SG_ 2365401086 Joystick8GripXAxisPos 4664;
BA_ "SPN" SG_ 2365401086 Jystck8GrpXAxsLvrRghtPstvPsSttus 4663;
BA_ "SigType" SG_ 2365401086 Jystck8GrpXAxsLvrRghtPstvPsSttus 4;
BA_ "SPN" SG_ 2365401086 Jystck8GrpXAxsLvrLftNgtvPsStatus 4662;
BA_ "SigType" SG_ 2365401086 Jystck8GrpXAxsLvrLftNgtvPsStatus 4;
BA_ "SPN" SG_ 2365401086 Jystck8GripXAxisNeutralPosStatus 4661;
BA_ "SigType" SG_ 2365401086 Jystck8GripXAxisNeutralPosStatus 4;
BA_ "SPN" SG_ 2365401598 Joystick7Button13PressedStatus 6755;
BA_ "SigType" SG_ 2365401598 Joystick7Button13PressedStatus 4;
BA_ "SPN" SG_ 2365401598 Joystick7Button14PressedStatus 6756;
BA_ "SigType" SG_ 2365401598 Joystick7Button14PressedStatus 4;
BA_ "SPN" SG_ 2365401598 Joystick7Button15PressedStatus 6757;
BA_ "SigType" SG_ 2365401598 Joystick7Button15PressedStatus 4;
BA_ "SPN" SG_ 2365401598 Joystick7Button16PressedStatus 6758;
BA_ "SigType" SG_ 2365401598 Joystick7Button16PressedStatus 4;
BA_ "SPN" SG_ 2365401598 Jystick7GripXAxisDetentPosStatus 4638;
BA_ "SigType" SG_ 2365401598 Jystick7GripXAxisDetentPosStatus 4;
BA_ "SPN" SG_ 2365401598 Jystick7GripYAxisDetentPosStatus 4637;
BA_ "SigType" SG_ 2365401598 Jystick7GripYAxisDetentPosStatus 4;
BA_ "SPN" SG_ 2365401598 Jystick7ThetaAxisDetentPosStatus 4636;
BA_ "SigType" SG_ 2365401598 Jystick7ThetaAxisDetentPosStatus 4;
BA_ "SPN" SG_ 2365401598 Joystick7ThetaAxisPos 4635;
BA_ "SPN" SG_ 2365401598 Jystck7ThtAxsClckwsPstvPosStatus 4634;
BA_ "SigType" SG_ 2365401598 Jystck7ThtAxsClckwsPstvPosStatus 4;
BA_ "SPN" SG_ 2365401598 Jystck7ThtAxsCntrClckwsNgtvPsStt 4633;
BA_ "SigType" SG_ 2365401598 Jystck7ThtAxsCntrClckwsNgtvPsStt 4;
BA_ "SPN" SG_ 2365401598 Jystck7ThetaAxisNeutralPosStatus 4632;
BA_ "SigType" SG_ 2365401598 Jystck7ThetaAxisNeutralPosStatus 4;
BA_ "SPN" SG_ 2365401598 Joystick7GripYAxisPos 4631;
BA_ "SPN" SG_ 2365401598 Jystck7GrpYAxsLvrFrwrdPstvPsStts 4630;
BA_ "SigType" SG_ 2365401598 Jystck7GrpYAxsLvrFrwrdPstvPsStts 4;
BA_ "SPN" SG_ 2365401598 Jystck7GrpYAxsLvrBckNgtvPsStatus 4629;
BA_ "SigType" SG_ 2365401598 Jystck7GrpYAxsLvrBckNgtvPsStatus 4;
BA_ "SPN" SG_ 2365401598 Jystck7GripYAxisNeutralPosStatus 4628;
BA_ "SigType" SG_ 2365401598 Jystck7GripYAxisNeutralPosStatus 4;
BA_ "SPN" SG_ 2365401598 Joystick7GripXAxisPos 4627;
BA_ "SPN" SG_ 2365401598 Jystck7GrpXAxsLvrRghtPstvPsSttus 4626;
BA_ "SigType" SG_ 2365401598 Jystck7GrpXAxsLvrRghtPstvPsSttus 4;
BA_ "SPN" SG_ 2365401598 Jystck7GrpXAxsLvrLftNgtvPsStatus 4625;
BA_ "SigType" SG_ 2365401598 Jystck7GrpXAxsLvrLftNgtvPsStatus 4;
BA_ "SPN" SG_ 2365401598 Jystck7GripXAxisNeutralPosStatus 4624;
BA_ "SigType" SG_ 2365401598 Jystck7GripXAxisNeutralPosStatus 4;
VAL_ 2566730238 Fan2DriveState 15 "Not available" 14 "Other" 13 "Engine brake" 12 "Timer" 11 "A/C system" 10 "Transmission retarder" 9 "Manual control" 8 "Reverse Operation" 7 "Default Operation" 6 "Excessive hydraulic oil temperature" 5 "Excessive transmission oil temperature" 4 "Excessive engine coolant temperature" 3 "Excessive engine oil temperature" 2 "Excessive engine air temperature" 1 "Engine system-General" 0 "Fan off" ;
VAL_ 2566711038 LubricationTimingCycleStatus 3 "Not available or not installed" 2 "Error" 1 "Enabled" 0 "Paused" ;
VAL_ 2566711038 LubricationReservoirLevel 3 "Not available or not installed" 2 "Error" 1 "Reservoir Low" 0 "Reservoir Not Low" ;
VAL_ 2566711038 LubricationPumpEnableStatus 3 "Not available" 2 "Error" 1 "Enabled" 0 "Disabled" ;
VAL_ 2566711038 LubricationOperationModeStatus 7 "Not Available" 6 "Error" 5 "Reserved" 4 "Test Mode # 3" 3 "Test Mode # 2" 2 "Test Mode # 1" 1 "Manual Service Mode" 0 "Automatic Mode" ;
VAL_ 2566711038 LubricationCycleModeStatus 7 "Not available" 6 "Error" 2 "Cycle mode # 3" 1 "Cycle mode # 2" 0 "Cycle mode # 1" ;
VAL_ 2566711038 LubricationCycleModeLockStatus 3 "Not available" 2 "Error" 1 "Locked" 0 "Not Locked" ;
VAL_ 2566710014 SupplementalFanDriveStatus 15 "Not available" 14 "Error" 5 "Uncontrolled Shutdown Active = Actuator current is off so it is limp" 4 "Controlled Shutdown Active = Driving to the default position" 3 "Derate Active = Torque output reduced due to environmental conditions" 2 "Alarm High Severity = Functional but transient performance may be reduced" 1 "Alarm = Fully operational but needs service" 0 "Normal = OK" ;
VAL_ 2566710014 SupplementalFanCtrlTempStatus 7 "Not available" 6 "Error" 5 "Not Defined" 4 "Low Most severe" 3 "Low Least severe" 2 "In Range" 1 "High Least severe" 0 "High most severe" ;
VAL_ 2566710014 SupplementalFanVelocityStatus 3 "Fan Spin Down" 2 "Fan Spin Up" 1 "Velocity Error " 0 "At Velocity" 15 "Not available" 14 "Error" 4 "Fan Stall" ;
VAL_ 2566710014 SupplementalFanDirectionStatus 3 "Not available/Not installed" 2 "Error" 1 "Reverse" 0 "Forward" ;
VAL_ 2566710014 SupplementalFanEnableStatus 3 "Not available/Not installed" 2 "Error" 1 "Enabled" 0 "Disabled" ;
VAL_ 2566708478 DriverCancellationStatus 3 "Not available" 2 "Error" 1 "Cruise control cancelled by driver action" 0 "Driver action has not cancelled cruise control" ;
VAL_ 2566708478 PrdctvCrsCtrlStSpeedOffsetStatus 3 "Not available" 2 "SAE Reserved" 1 "Cruise Control Speed, SPN 7319) includes Predictive Cruise Control Set Speed Offset" 0 "Cruise Control Speed, SPN 7319) does not include Predictive Cruise Control Set Speed Offset" ;
VAL_ 2566708478 AEBSReadinessState 3 "Not Available/Not Supported" 2 "Condition exists that prevents system from responding to AEBS commands even though it is configured" 1 "On" 0 "Off" ;
VAL_ 2566708478 CruiseCtrlSystemCmdState 7 "Not Supported" 4 "Cruise control device has received a Cruise Control Resume Command" 3 "Cruise control has been re-activated by Cruise Control Resume Command" 2 "Cruise control  has been disabled by Cruise Control Pause Command" 1 "Cruise control has been disabled by Cruise Control Disable Command" 0 "No Cruise Control System Command" ;
VAL_ 2566708478 AdptiveCruiseCtrlReadinessStatus 3 "Not Available/Not Supported" 2 "Error Condition" 1 "On" 0 "Off" ;
VAL_ 2297441790 SpprtVrblTrnsRpttnRtFrAcclrtnSns 3 "ECU only supports standard transmission rate of 10 ms" 2 "20 ms rate supported" 1 "Reserved for SAE assignment" 0 "Reserve for SAE assignment" ;
VAL_ 2297441790 VrtclAcclrtnExRangeFigureOfMerit 3 "not available" 2 "error" 1 "verticalacceleration is degraded" 0 "vertical acceleration is fully functional" ;
VAL_ 2297441790 LngtdnlAcclrtnExRngFigureOfMerit 3 "not available" 2 "error" 1 "longitudinal acceleration is degraded" 0 "longitudinal acceleration is fully functional" ;
VAL_ 2297441790 LtrlAcclrtonExRangeFigureOfMerit 3 "not available" 2 "error" 1 "lateral acceleration is degraded" 0 "lateral acceleration is fully functional" ;
VAL_ 2364549630 RollAngleExRangeFigureOfMerit 3 "Not available" 2 "Error" 1 "Roll angle degraded" 0 "Roll angle fully functional" ;
VAL_ 2364549630 RollAngleExRangeCompensation 3 "Not Available" 2 "Error" 1 "Off" 0 "On" ;
VAL_ 2364549630 PitchAngleExRangeFigureOfMerit 3 "Not available" 2 "Error" 1 "Pitch angle degraded" 0 "Pitch angle fully functional" ;
VAL_ 2364549630 PitchAngleExRangeCompensation 3 "Not Available" 2 "Error" 1 "Off" 0 "On" ;
VAL_ 2499614462 OccpntClssficationSystem10Status 3 "not available" 2 "Error" 1 "occupied" 0 "empty" ;
VAL_ 2499614462 OccpntClssificationSystem9Status 3 "not available" 2 "Error" 1 "occupied" 0 "empty" ;
VAL_ 2499614462 OccpntClssificationSystem8Status 3 "not available" 2 "Error" 1 "occupied" 0 "empty" ;
VAL_ 2499614462 OccpntClssificationSystem7Status 3 "not available" 2 "Error" 1 "occupied" 0 "empty" ;
VAL_ 2499614462 OccpntClssificationSystem6Status 3 "not available" 2 "Error" 1 "occupied" 0 "empty" ;
VAL_ 2499614462 OccpntClssificationSystem5Status 3 "not available" 2 "Error" 1 "occupied" 0 "empty" ;
VAL_ 2499614462 OccpntClssificationSystem4Status 3 "not available" 2 "Error" 1 "occupied" 0 "empty" ;
VAL_ 2499614462 OccpntClssificationSystem3Status 3 "not available" 2 "Error" 1 "occupied" 0 "empty" ;
VAL_ 2499614462 PssngrOccpntClssfctnSystemStatus 7 "not available" 6 "reserved" 5 "Error" 4 "large adult" 3 "adult" 2 "small adult" 1 "child" 0 "empty" ;
VAL_ 2499614462 DrvrOccpntClssfctionSystemStatus 7 "not available" 6 "Error" 5 "reserved" 4 "large adult" 3 "adult" 2 "small adult" 1 "child" 0 "empty" ;
VAL_ 2560098046 CabNoiseCtrlTuningStatus 15 "Not Available/Not Tuning/Not Requested" 14 "Tuning Mode" 13 "Reserved" 12 "Reserved" 11 "Reserved" 10 "Automatic Tuning Mode, Saving Data" 9 "Automatic Tuning Mode, Command Complete" 8 "Automatic Tuning Mode" 7 "Manual Tuning Denied" 6 "Reserved" 5 "Reserved" 4 "Reserved" 3 "Reserved" 2 "Manual Tuning Mode, Saving Data" 1 "Manual Tuning Mode, Command Complete" 0 "Manual Tuning Mode" ;
VAL_ 2560098046 CabNoiseCtrlStatus 3 "Not Available/Not Requested" 2 "Error Indicator" 1 "Cab Noise Control System OFF-Line" 0 "Cab Noise Control System ON-Line" ;
VAL_ 2560163582 CabNoiseCtrlTuningCmd 7 "Don't Care" 6 "Reserved" 5 "Exit Tuning,  Saving Parameters" 4 "Exit Tuning,  Not Saving Parameters" 3 "Remain In Tuning" 2 "Activate Automatic Tuning State" 1 "Activate Automatic Tuning" 0 "Activate Manual Tuning" ;
VAL_ 2560163582 CabNoiseCtrlCmd 3 "Don't Care/Not Commanded" 2 "Reserved" 1 "Bring Cab Noise Control System On Line" 0 "Take Cab Noise Control System Off Line" ;
VAL_ 2297441534 MagnetGeneratorCtrl 3 "Take No Action" 2 "Reserved" 1 "On" 0 "Off" ;
VAL_ 2297441534 DropRelayCtrl 3 "Take No Action" 2 "Reserved" 1 "On" 0 "Off" ;
VAL_ 2297441534 LiftRelayCtrl 3 "Take No Action" 2 "Reserved" 1 "On" 0 "Off" ;
VAL_ 2297441534 MaterialDropActiveStatus 3 "Not Available" 2 "Error" 1 "On" 0 "Off" ;
VAL_ 2297441534 MaterialLiftActiveStatus 3 "Not Available" 2 "Error" 1 "On" 0 "Off" ;
VAL_ 2297441534 GneratorCurrentBoostActiveStatus 3 "Not Available" 2 "Error" 1 "On" 0 "Off" ;
VAL_ 2297441534 MaterialDropSwitch 3 "Not Available" 2 "Error" 1 "Drop" 0 "Don't Drop" ;
VAL_ 2297441534 MaterialLiftSwitch 3 "Not Available" 2 "Error" 1 "Lift" 0 "Don't Lift" ;
VAL_ 2566722302 GeneratorDutyCycleExceededStatus 3 "Not Avaiable" 2 "Error" 1 "Duty Cycle Exceed" 0 "Duty Cycle Not Exceed" ;
VAL_ 2566722302 VoltageMonitorActiveStatus 3 "Not Available" 2 "Error" 1 "Monitor is On" 0 "Monitor is Off" ;
VAL_ 2566722302 GensetEnableActiveStatus 3 "Not Avaialble" 2 "Error" 1 "Enabled" 0 "Not Enabled" ;
VAL_ 2566722302 ReverseCurrentRangeSetting 31 "Not Available" 30 "Error" 15 "16" 14 "15" 13 "14" 12 "13" 11 "12" 10 "11" 9 "10" 8 "9" 7 "8" 6 "7" 5 "6" 4 "5" 3 "4" 2 "3" 1 "2" 0 "1" ;
VAL_ 2566722302 GensetSoftstartActiveStatus 3 "Not Available" 2 "Error" 1 "On" 0 "Off" ;
VAL_ 2566722302 Grapple_MagnetSelectionSwitch 3 "Not Available" 2 "Error" 1 "Magnet Selected" 0 "Grapple Selected" ;
VAL_ 2566722302 GnstSystmOtputVoltageRangeStatus 3 "Not Available" 2 "Error" 1 "In Range" 0 "Out of Range" ;
VAL_ 2566722302 GeneratorOverheatStatus 3 "Not Available" 2 "Error" 1 "Overheat" 0 "Not Overheat" ;
VAL_ 2560032510 LwVltgDscnnctDsiredOperatingMode 15 "No change" 5 "Manual Connect" 4 "Manual Disconnect" 0 "Automatic" ;
VAL_ 2566717950 LwVltgeDisconnectVoutOutputState 15 "Not available or not installed" 14 "Output fault" 4 "Connect pending" 3 "Disconnect pending" 2 "Disconnect alarm expired" 1 "Output on or connected" 0 "Output off or disconnected" ;
VAL_ 2566717950 LowVoltageDisconnectOutput1State 15 "Not available or not installed" 14 "Output fault" 4 "Connect pending" 3 "Disconnect pending" 2 "Disconnect alarm expired" 1 "Output on or connected" 0 "Output off or disconnected" ;
VAL_ 2566717950 LowVoltageDisconnectOutput2State 14 "Output fault" 4 "Connect pending" 3 "Disconnect pending" 2 "Disconnect alarm expired" 1 "Output on or connected" 0 "Output off or disconnected" 15 "Not available or not installed" ;
VAL_ 2566717950 LowVoltageDisconnectOutput3State 15 "Not available or not installed" 14 "Output fault" 4 "Connect pending" 3 "Disconnect pending" 2 "Disconnect alarm expired" 1 "Output on or connected" 0 "Output off or disconnected" ;
VAL_ 2566717950 LwVltgDscnnctCrrentOperatingMode 15 "Not available" 9 "Manual Connect via hardwired input" 8 "Manual Disconnect via hardwired input" 5 "Manual Connect via J1939 request" 4 "Manual Disconnect via J1939 request" 0 "Automatic" ;
VAL_ 2566717950 LwVltgDscnnectManualConnectState 3 "Not installed" 2 "Error" 1 "Input on" 0 "Input off" ;
VAL_ 2566717950 LwVltgDscnnctMnalDisconnectState 3 "Not installed" 2 "Error" 1 "Input on" 0 "Input off" ;
VAL_ 2358902526 Joystick3Lamp10Cmd 3 "Don't care / Take no action" 2 "Blinking" 1 "On" 0 "Off" ;
VAL_ 2358902526 Joystick3Lamp9Cmd 3 "Don't care / Take no action" 2 "Blinking" 1 "On" 0 "Off" ;
VAL_ 2358902526 Joystick3Lamp8Cmd 3 "Don't care / Take no action" 2 "Blinking" 1 "On" 0 "Off" ;
VAL_ 2358902526 Joystick3Lamp7Cmd 3 "Don't care / Take no action" 2 "Blinking" 1 "On" 0 "Off" ;
VAL_ 2358902526 Joystick3Lamp6Cmd 3 "Don't care / Take no action" 2 "Blinking" 1 "On" 0 "Off" ;
VAL_ 2358902526 Joystick3Lamp5Cmd 3 "Don't care / Take no action" 2 "Blinking" 1 "On" 0 "Off" ;
VAL_ 2358902526 Joystick3Lamp4Cmd 3 "Don't care / Take no action" 2 "Blinking" 1 "On" 0 "Off" ;
VAL_ 2358902526 Joystick3Lamp3Cmd 3 "Don't care / Take no action" 2 "Blinking" 1 "On" 0 "Off" ;
VAL_ 2358902526 Joystick3Lamp2Cmd 3 "Don't care / Take no action" 2 "Blinking" 1 "On" 0 "Off" ;
VAL_ 2358902526 Joystick3Lamp1Cmd 3 "Don't care / Take no action" 2 "Blinking" 1 "On" 0 "Off" ;
VAL_ 2358902526 Joystick2Lamp10Cmd 3 "Don't care / Take no action" 2 "Blinking" 1 "On" 0 "Off" ;
VAL_ 2358902526 Joystick2Lamp9Cmd 3 "Don't care / Take no action" 2 "Blinking" 1 "On" 0 "Off" ;
VAL_ 2358902526 Joystick2Lamp8Cmd 3 "Don't care / Take no action" 2 "Blinking" 1 "On" 0 "Off" ;
VAL_ 2358902526 Joystick2Lamp7Cmd 3 "Don't care / Take no action" 2 "Blinking" 1 "On" 0 "Off" ;
VAL_ 2358902526 Joystick2Lamp6Cmd 3 "Don't care / Take no action" 2 "Blinking" 1 "On" 0 "Off" ;
VAL_ 2358902526 Joystick2Lamp5Cmd 3 "Don't care / Take no action" 2 "Blinking" 1 "On" 0 "Off" ;
VAL_ 2358902526 Joystick2Lamp4Cmd 0 "Off" 3 "Don't care / Take no action" 2 "Blinking" 1 "On" ;
VAL_ 2358902526 Joystick2Lamp3Cmd 3 "Don't care / Take no action" 2 "Blinking" 1 "On" 0 "Off" ;
VAL_ 2358902526 Joystick2Lamp2Cmd 3 "Don't care / Take no action" 2 "Blinking" 1 "On" 0 "Off" ;
VAL_ 2358902526 Joystick2Lamp1Cmd 3 "Don't care / Take no action" 2 "Blinking" 1 "On" 0 "Off" ;
VAL_ 2358902526 Joystick1Lamp10Cmd 3 "Don't care / Take no action" 2 "Blinking" 1 "On" 0 "Off" ;
VAL_ 2358902526 Joystick1Lamp9Cmd 3 "Don't care / Take no action" 2 "Blinking" 1 "On" 0 "Off" ;
VAL_ 2358902526 Joystick1Lamp8Cmd 3 "Don't care / Take no action" 2 "Blinking" 1 "On" 0 "Off" ;
VAL_ 2358902526 Joystick1Lamp7Cmd 3 "Don't care / Take no action" 2 "Blinking" 1 "On" 0 "Off" ;
VAL_ 2358902526 Joystick1Lamp6Cmd 3 "Don't care / Take no action" 2 "Blinking" 1 "On" 0 "Off" ;
VAL_ 2358902526 Joystick1Lamp5Cmd 3 "Don't care / Take no action" 2 "Blinking" 1 "On" 0 "Off" ;
VAL_ 2358902526 Joystick1Lamp4Cmd 3 "Don't care / Take no action" 2 "Blinking" 1 "On" 0 "Off" ;
VAL_ 2358902526 Joystick1Lamp3Cmd 3 "Don't care / Take no action" 2 "Blinking" 1 "On" 0 "Off" ;
VAL_ 2358902526 Joystick1Lamp2Cmd 3 "Don't care / Take no action" 2 "Blinking" 1 "On" 0 "Off" ;
VAL_ 2358902526 Joystick1Lamp1Cmd 3 "Don't care / Take no action" 2 "Blinking" 1 "On" 0 "Off" ;
VAL_ 2566711550 IntkVlvActtnSystmOlPrss2SlndCtrl 3 "not available" 2 "reserved for SAE assignment" 1 "on" 0 "off" ;
VAL_ 2566711550 IntkVlvActtnSystmOlPrss1SlndCtrl 3 "not available" 2 "reserved for SAE assignment" 1 "on" 0 "off" ;
VAL_ 2566713854 EngExhstBckPrssRgltrCtrlOprtnStt 15 "Not available" 14 "Error" 5 "Uncontrolled Shutdown Active" 4 "Controlled Shutdown Active" 3 "Derate Active" 2 "Alarm High Severity" 1 "Alarm" 0 "Normal" ;
VAL_ 2566713854 EngExhstBckPrssRglatorTempStatus 7 "Not available" 6 "Error" 5 "Not Defined" 4 "Low Most severe" 3 "Low Least severe" 2 "In Range" 1 "High Least severe" 0 "High most severe" ;
VAL_ 2566713854 EngTrbWstgtActtr2OperationStatus 14 "Error" 5 "Uncontrolled Shutdown Active" 4 "Controlled Shutdown Active" 3 "Derate Active" 2 "Alarm High Severity" 1 "Alarm" 0 "Normal" ;
VAL_ 2566713854 EngTrbWstgtActtr1OperationStatus 14 "Error" 6 "Calibration in Progress" 5 "Uncontrolled Shutdown Active" 4 "Controlled Shutdown Active" 3 "Derate Active" 2 "Alarm High Severity" 1 "Alarm" 0 "Normal" ;
VAL_ 2566713854 EngTrbWstgateActuator2TempStatus 7 "Not available" 6 "Error" 5 "Not Defined" 4 "Low Most severe" 3 "Low Least severe" 2 "In Range" 1 "High Least severe" 0 "High most severe" ;
VAL_ 2566714366 EngTrbCmprssrBypssActtr2OprtnStt 14 "Error" 5 "Uncontrolled Shutdown Active" 4 "Controlled Shutdown Active" 3 "Derate Active" 2 "Alarm High Severity" 1 "Alarm" 0 "Normal" ;
VAL_ 2566714366 EngTrbCmprssrBypssActtr1OprtnStt 14 "Error" 5 "Uncontrolled Shutdown Active" 4 "Controlled Shutdown Active" 3 "Derate Active" 2 "Alarm High Severity" 1 "Alarm" 0 "Normal" ;
VAL_ 2566714366 EngTrbCmprssrBypssActtr2TmpSttus 7 "Not available" 6 "Error" 5 "Not Defined" 4 "Low Most severe" 3 "Low Least severe" 2 "In Range" 1 "High Least severe" 0 "High most severe" ;
VAL_ 2566714110 EngFuelValve2OperationStatus 14 "Error" 6 "Test Mode Active" 5 "Uncontrolled Shutdown Active" 4 "Controlled Shutdown Active" 3 "Derate Active" 2 "Alarm High Severity" 1 "Alarm" 0 "Normal" ;
VAL_ 2566714110 EngFuelValve1OperationStatus 14 "Error" 6 "Test Mode Active" 5 "Uncontrolled Shutdown Active" 4 "Controlled Shutdown Active" 3 "Derate Active" 2 "Alarm High Severity" 1 "Alarm" 0 "Normal" ;
VAL_ 2566714110 EngThrottleValve2OperationStatus 14 "Error" 5 "Uncontrolled Shutdown Active" 4 "Controlled Shutdown Active" 3 "Derate Active" 2 "Alarm High Severity" 1 "Alarm" 0 "Normal" ;
VAL_ 2566714110 EngThrottleValve1OperationStatus 15 "Not available" 14 "Error" 6 "Calibration in Progress" 5 "Uncontrolled Shutdown Active" 4 "Controlled Shutdown Active" 3 "Derate Active" 2 "Alarm High Severity" 1 "Alarm" 0 "Normal" ;
VAL_ 2566714110 EngFuelValve2TempStatus 7 "Not available" 6 "Error" 5 "Not Defined" 4 "Low Most severe" 3 "Low Least severe" 2 "In Range" 1 "High Least severe" 0 "High most severe" ;
VAL_ 2566714110 EngFuelValve1TempStatus 7 "Not available" 6 "Error" 5 "Not Defined" 4 "Low Most severe" 3 "Low Least severe" 2 "In Range" 1 "High Least severe" 0 "High Most severe" ;
VAL_ 2566714110 EngThrottleValve2TempStatus 7 "Not available" 6 "Error" 5 "Not Defined" 4 "Low Most severe" 3 "Low Least severe" 2 "In Range" 1 "High Least severe" 0 "High Most severe" ;
VAL_ 2566714110 EngThrottleValve1TempStatus 7 "Not available" 6 "Error" 5 "Not Defined" 4 "Low Most severe" 3 "Low Least severe" 2 "In Range" 1 "High Least severe" 0 "High most severe" ;
VAL_ 2365400574 Joystick9Button13PressedStatus 3 "Not Available" 2 "Error Indicator" 1 "Button pressed" 0 "Button not pressed" ;
VAL_ 2365400574 Joystick9Button14PressedStatus 3 "Not Available" 2 "Error Indicator" 1 "Button pressed" 0 "Button not pressed" ;
VAL_ 2365400574 Joystick9Button15PressedStatus 3 "Not Available" 2 "Error Indicator" 1 "Button pressed" 0 "Button not pressed" ;
VAL_ 2365400574 Joystick9Button16PressedStatus 3 "Not Available" 2 "Error Indicator" 1 "Button pressed" 0 "Button not pressed" ;
VAL_ 2365400574 Jystick9GripXAxisDetentPosStatus 3 "Not Available" 2 "Error Indicator" 1 "In the Detent Position" 0 "Not in the Detent Position" ;
VAL_ 2365400574 Jystick9GripYAxisDetentPosStatus 3 "Not Available" 2 "Error Indicator" 1 "In the Detent Position" 0 "Not in the Detent Position" ;
VAL_ 2365400574 Jystick9ThetaAxisDetentPosStatus 3 "Not Available" 2 "Error Indicator" 1 "In the Detent Position" 0 "Not in the Detent Position" ;
VAL_ 2365400574 Jystck9ThtAxsClckwsPstvPosStatus 3 "Not Available" 2 "Error Indicator" 1 "On positive side of Neutral" 0 "Not on Positive side of Neutral" ;
VAL_ 2365400574 Jystck9ThtAxsCntrClckwsNgtvPsStt 3 "Not Available" 2 "Error Indicator" 1 "On negative side of Neutral" 0 "Not on negative side of Neutral" ;
VAL_ 2365400574 Jystck9ThetaAxisNeutralPosStatus 3 "Not Available" 2 "Error Indicator" 1 "In Neutral Position" 0 "Not in Neutral Position" ;
VAL_ 2365400574 Jystck9GrpYAxsLvrFrwrdPstvPsStts 3 "Not Available" 2 "Error Indicator" 1 "On positive side of Neutral" 0 "Not on Positive side of Neutral" ;
VAL_ 2365400574 Jystck9GrpYAxsLvrBckNgtvPsStatus 3 "Not Available" 2 "Error Indicator" 1 "On negative side of Neutral" 0 "Not on negative side of Neutral" ;
VAL_ 2365400574 Jystck9GripYAxisNeutralPosStatus 3 "Not Available" 2 "Error Indicator" 1 "In Neutral Position" 0 "Not in Neutral Position" ;
VAL_ 2365400574 Jystck9GrpXAxsLvrRghtPstvPsSttus 3 "Not Available" 2 "Error Indicator" 1 "On positive side of Neutral" 0 "Not on Positive side of Neutral" ;
VAL_ 2365400574 Jystck9GrpXAxsLvrLftNgtvPsStatus 3 "Not Available" 2 "Error Indicator" 1 "On negative side of Neutral" 0 "Not on negative side of Neutral" ;
VAL_ 2365400574 Jystck9GripXAxisNeutralPosStatus 3 "Not Available" 2 "Error Indicator" 1 "In Neutral Position" 0 "Not in Neutral Position" ;
VAL_ 2365401086 Joystick8Button13PressedStatus 3 "Not Available" 2 "Error Indicator" 1 "Button pressed" 0 "Button not pressed" ;
VAL_ 2365401086 Joystick8Button14PressedStatus 3 "Not Available" 2 "Error Indicator" 1 "Button pressed" 0 "Button not pressed" ;
VAL_ 2365401086 Joystick8Button15PressedStatus 3 "Not Available" 2 "Error Indicator" 1 "Button pressed" 0 "Button not pressed" ;
VAL_ 2365401086 Joystick8Button16PressedStatus 3 "Not Available" 2 "Error Indicator" 1 "Button pressed" 0 "Button not pressed" ;
VAL_ 2365401086 Jystick8GripXAxisDetentPosStatus 3 "Not Available" 2 "Error Indicator" 1 "In the Detent Position" 0 "Not in the Detent Position" ;
VAL_ 2365401086 Jystick8GripYAxisDetentPosStatus 3 "Not Available" 2 "Error Indicator" 1 "In the Detent Position" 0 "Not in the Detent Position" ;
VAL_ 2365401086 Jystick8ThetaAxisDetentPosStatus 3 "Not Available" 2 "Error Indicator" 1 "In the Detent Position" 0 "Not in the Detent Position" ;
VAL_ 2365401086 Jystck8ThtAxsClckwsPstvPosStatus 3 "Not Available" 2 "Error Indicator" 1 "On positive side of Neutral" 0 "Not on Positive side of Neutral" ;
VAL_ 2365401086 Jystck8ThtAxsCntrClckwsNgtvPsStt 3 "Not Available" 2 "Error Indicator" 1 "On negative side of Neutral" 0 "Not on negative side of Neutral" ;
VAL_ 2365401086 Jystck8ThetaAxisNeutralPosStatus 3 "Not Available" 2 "Error Indicator" 1 "In Neutral Position" 0 "Not in Neutral Position" ;
VAL_ 2365401086 Jystck8GrpYAxsLvrFrwrdPstvPsStts 3 "Not Available" 2 "Error Indicator" 1 "On positive side of Neutral" 0 "Not on Positive side of Neutral" ;
VAL_ 2365401086 Jystck8GrpYAxsLvrBckNgtvPsStatus 3 "Not Available" 2 "Error Indicator" 1 "On negative side of Neutral" 0 "Not on negative side of Neutral" ;
VAL_ 2365401086 Jystck8GripYAxisNeutralPosStatus 3 "Not Available" 2 "Error Indicator" 1 "In Neutral Position" 0 "Not in Neutral Position" ;
VAL_ 2365401086 Jystck8GrpXAxsLvrRghtPstvPsSttus 3 "Not Available" 2 "Error Indicator" 1 "On positive side of Neutral" 0 "Not on Positive side of Neutral" ;
VAL_ 2365401086 Jystck8GrpXAxsLvrLftNgtvPsStatus 3 "Not Available" 2 "Error Indicator" 1 "On negative side of Neutral" 0 "Not on negative side of Neutral" ;
VAL_ 2365401086 Jystck8GripXAxisNeutralPosStatus 3 "Not Available" 2 "Error Indicator" 1 "In Neutral Position" 0 "Not in Neutral Position" ;
VAL_ 2365401598 Joystick7Button13PressedStatus 3 "Not Available" 2 "Error Indicator" 1 "Button pressed" 0 "Button not pressed" ;
VAL_ 2365401598 Joystick7Button14PressedStatus 3 "Not Available" 2 "Error Indicator" 1 "Button pressed" 0 "Button not pressed" ;
VAL_ 2365401598 Joystick7Button15PressedStatus 3 "Not Available" 2 "Error Indicator" 1 "Button pressed" 0 "Button not pressed" ;
VAL_ 2365401598 Joystick7Button16PressedStatus 3 "Not Available" 2 "Error Indicator" 1 "Button pressed" 0 "Button not pressed" ;
VAL_ 2365401598 Jystick7GripXAxisDetentPosStatus 3 "Not Available" 2 "Error Indicator" 1 "In the Detent Position" 0 "Not in the Detent Position" ;
VAL_ 2365401598 Jystick7GripYAxisDetentPosStatus 3 "Not Available" 2 "Error Indicator" 1 "In the Detent Position" 0 "Not in the Detent Position" ;
VAL_ 2365401598 Jystick7ThetaAxisDetentPosStatus 3 "Not Available" 2 "Error Indicator" 1 "In the Detent Position" 0 "Not in the Detent Position" ;
VAL_ 2365401598 Jystck7ThtAxsClckwsPstvPosStatus 3 "Not Available" 2 "Error Indicator" 1 "On positive side of Neutral" 0 "Not on Positive side of Neutral" ;
VAL_ 2365401598 Jystck7ThtAxsCntrClckwsNgtvPsStt 3 "Not Available" 2 "Error Indicator" 1 "On negative side of Neutral" 0 "Not on negative side of Neutral" ;
VAL_ 2365401598 Jystck7ThetaAxisNeutralPosStatus 3 "Not Available" 2 "Error Indicator" 1 "In Neutral Position" 0 "Not in Neutral Position" ;
VAL_ 2365401598 Jystck7GrpYAxsLvrFrwrdPstvPsStts 3 "Not Available" 2 "Error Indicator" 1 "On positive side of Neutral" 0 "Not on Positive side of Neutral" ;
VAL_ 2365401598 Jystck7GrpYAxsLvrBckNgtvPsStatus 3 "Not Available" 2 "Error Indicator" 1 "On negative side of Neutral" 0 "Not on negative side of Neutral" ;
VAL_ 2365401598 Jystck7GripYAxisNeutralPosStatus 3 "Not Available" 2 "Error Indicator" 1 "In Neutral Position" 0 "Not in Neutral Position" ;
VAL_ 2365401598 Jystck7GrpXAxsLvrRghtPstvPsSttus 3 "Not Available" 2 "Error Indicator" 1 "On positive side of Neutral" 0 "Not on Positive side of Neutral" ;
VAL_ 2365401598 Jystck7GrpXAxsLvrLftNgtvPsStatus 3 "Not Available" 2 "Error Indicator" 1 "On negative side of Neutral" 0 "Not on negative side of Neutral" ;
VAL_ 2365401598 Jystck7GripXAxisNeutralPosStatus 3 "Not Available" 2 "Error Indicator" 1 "In Neutral Position" 0 "Not in Neutral Position" ;
